VERSION "dbc-export 1 2025.20.8"

NS_ :

BS_:

BU_: ADSP APSB BB BMS CMP CP DAS DI DIF DIR DPB EPASTP EPASTS GTW ICR IDB OCS1P PM PMF PMR PTC RCM RCU TCU UI UIS VCLEFT VCSEC

BO_ 896 PM_alertMatrix2: 8 PM
 SG_ PM_a066_pmfMIA : 1|1@1+ (1,0) [0|1] "" Vector__XXX
 SG_ PM_a067_pmrMIA : 2|1@1+ (1,0) [0|1] "" Vector__XXX
 SG_ PM_a068_brakePedalMonitor : 3|1@1+ (1,0) [0|1] "" Vector__XXX
 SG_ PM_a069_brakeMonitorsUnhealthy : 4|1@1+ (1,0) [0|1] "" Vector__XXX
 SG_ PM_a070_brakeTorqueSplitMonitorT : 5|1@1+ (1,0) [0|1] "" Vector__XXX
 SG_ PM_a071_baseBrakingMonitor : 6|1@1+ (1,0) [0|1] "" Vector__XXX
 SG_ PM_a072_brakeTorqueCommandInterf : 7|1@1+ (1,0) [0|1] "" Vector__XXX
 SG_ PM_a073_canDataBusC : 8|1@1+ (1,0) [0|1] "" Vector__XXX
 SG_ PM_a074_canHardwareBusC : 9|1@1+ (1,0) [0|1] "" Vector__XXX
 SG_ PM_a075_canDataBusD : 10|1@1+ (1,0) [0|1] "" Vector__XXX
 SG_ PM_a076_canHardwareBusD : 11|1@1+ (1,0) [0|1] "" Vector__XXX
 SG_ PM_a077_canDataBusE : 12|1@1+ (1,0) [0|1] "" Vector__XXX
 SG_ PM_a078_canHardwareBusE : 13|1@1+ (1,0) [0|1] "" Vector__XXX
 SG_ PM_a079_rcuMIA : 14|1@1+ (1,0) [0|1] "" Vector__XXX
 SG_ PM_a080_exceptionPrefetchAbort : 15|1@1+ (1,0) [0|1] "" Vector__XXX
 SG_ PM_a081_exceptionDataAbort : 16|1@1+ (1,0) [0|1] "" Vector__XXX
 SG_ PM_a082_exceptionDataAbort2 : 17|1@1+ (1,0) [0|1] "" Vector__XXX
 SG_ PM_a083_ahbWriteError : 18|1@1+ (1,0) [0|1] "" Vector__XXX
 SG_ PM_a084_exceptionMpuFirewall : 19|1@1+ (1,0) [0|1] "" Vector__XXX
 SG_ PM_a085_dpbMIA : 20|1@1+ (1,0) [0|1] "" Vector__XXX
 SG_ PM_a086_exceptionUndefinedInstru : 21|1@1+ (1,0) [0|1] "" Vector__XXX
 SG_ PM_a087_canHardwareBusLIPC : 22|1@1+ (1,0) [0|1] "" Vector__XXX
 SG_ PM_a092_xtalOscillator : 27|1@1+ (1,0) [0|1] "" Vector__XXX
 SG_ PM_a093_accelPedalSupply : 28|1@1+ (1,0) [0|1] "" Vector__XXX
 SG_ PM_a095_ITPMSTimeoutGNSSConverge : 30|1@1+ (1,0) [0|1] "" Vector__XXX
 SG_ PM_a096_ITPMSConvergedGNSSAbsRad : 31|1@1+ (1,0) [0|1] "" Vector__XXX
 SG_ PM_a098_ITPMSTriggerDebug : 33|1@1+ (1,0) [0|1] "" Vector__XXX
 SG_ PM_a099_ITPMSCalibrated : 34|1@1+ (1,0) [0|1] "" Vector__XXX
 SG_ PM_a100_diTraceInfo1 : 35|1@1+ (1,0) [0|1] "" Vector__XXX
 SG_ PM_a110_indirectTPMSSoftWarningF : 45|1@1+ (1,0) [0|1] "" Vector__XXX
 SG_ PM_a111_indirectTPMSSoftWarningF : 46|1@1+ (1,0) [0|1] "" Vector__XXX
 SG_ PM_a112_indirectTPMSSoftWarningR : 47|1@1+ (1,0) [0|1] "" Vector__XXX
 SG_ PM_a113_indirectTPMSSoftWarningR : 48|1@1+ (1,0) [0|1] "" Vector__XXX
 SG_ PM_a114_indirectTPMSHardWarningF : 49|1@1+ (1,0) [0|1] "" Vector__XXX
 SG_ PM_a115_indirectTPMSHardWarningF : 50|1@1+ (1,0) [0|1] "" Vector__XXX
 SG_ PM_a116_indirectTPMSHardWarningR : 51|1@1+ (1,0) [0|1] "" Vector__XXX
 SG_ PM_a117_indirectTPMSHardWarningR : 52|1@1+ (1,0) [0|1] "" Vector__XXX
 SG_ PM_a120_indirectTPMSFaulted : 55|1@1+ (1,0) [0|1] "" Vector__XXX
 SG_ PM_a121_unintendedReset2 : 56|1@1+ (1,0) [0|1] "" Vector__XXX

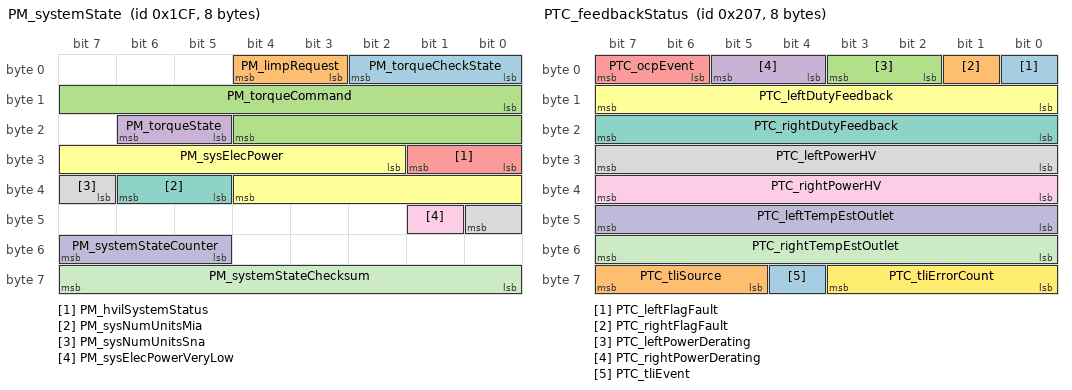
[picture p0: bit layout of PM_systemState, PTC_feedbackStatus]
BO_ 463 PM_systemState: 8 PM
 SG_ PM_torqueCheckState : 0|3@1+ (1,0) [0|7] "" Vector__XXX
 SG_ PM_limpRequest : 3|2@1+ (1,0) [0|3] "" Vector__XXX
 SG_ PM_torqueCommand : 8|13@1- (2,0) [-8192|8190] "Nm" Vector__XXX
 SG_ PM_torqueState : 21|2@1+ (1,0) [0|3] "" Vector__XXX
 SG_ PM_hvilSystemStatus : 24|2@1+ (1,0) [0|2] "" Vector__XXX
 SG_ PM_sysElecPower : 26|11@1- (1,250) [-774|1273] "kW" Vector__XXX
 SG_ PM_sysNumUnitsMia : 37|2@1+ (1,0) [0|3] "" Vector__XXX
 SG_ PM_sysNumUnitsSna : 39|2@1+ (1,0) [0|3] "" Vector__XXX
 SG_ PM_sysElecPowerVeryLow : 41|1@1+ (1,0) [0|1] "" Vector__XXX
 SG_ PM_systemStateCounter : 53|3@1+ (1,0) [0|7] "" Vector__XXX
 SG_ PM_systemStateChecksum : 56|8@1+ (1,0) [0|255] "" Vector__XXX

BO_ 519 PTC_feedbackStatus: 8 PTC
 SG_ PTC_leftFlagFault : 0|1@1+ (1,0) [0|1] "" Vector__XXX
 SG_ PTC_rightFlagFault : 1|1@1+ (1,0) [0|1] "" Vector__XXX
 SG_ PTC_leftPowerDerating : 2|2@1+ (1,0) [0|3] "" Vector__XXX
 SG_ PTC_rightPowerDerating : 4|2@1+ (1,0) [0|3] "" Vector__XXX
 SG_ PTC_ocpEvent : 6|2@1+ (1,0) [0|3] "" Vector__XXX
 SG_ PTC_leftDutyFeedback : 8|8@1+ (0.5,0) [0|100] "%" Vector__XXX
 SG_ PTC_rightDutyFeedback : 16|8@1+ (0.5,0) [0|100] "%" Vector__XXX
 SG_ PTC_leftPowerHV : 24|8@1+ (30,0) [0|7650] "W" Vector__XXX
 SG_ PTC_rightPowerHV : 32|8@1+ (30,0) [0|7650] "W" Vector__XXX
 SG_ PTC_leftTempEstOutlet : 40|8@1+ (1,-40) [-40|200] "degC" Vector__XXX
 SG_ PTC_rightTempEstOutlet : 48|8@1+ (1,-40) [-40|200] "degC" Vector__XXX
 SG_ PTC_tliErrorCount : 56|4@1+ (1,0) [0|15] "" Vector__XXX
 SG_ PTC_tliEvent : 60|1@1+ (1,0) [0|1] "" Vector__XXX
 SG_ PTC_tliSource : 61|3@1+ (1,0) [0|7] "" Vector__XXX

BO_ 1297 RCM_alertLog: 8 RCM
 SG_ RCM_alertID M : 0|10@1+ (1,0) [0|1023] "" Vector__XXX
 SG_ RCM_alertState : 10|1@1+ (1,0) [0|1] "" Vector__XXX
 SG_ RCM_a000_eventArmStatus m0 : 11|1@1+ (1,0) [0|1] "" Vector__XXX
 SG_ RCM_a000_eventFactoryMode m0 : 12|1@1+ (1,0) [0|1] "" Vector__XXX
 SG_ RCM_a000_eventDiagEnabled m0 : 13|1@1+ (1,0) [0|1] "" Vector__XXX
 SG_ RCM_a000_eventDriveOrientation m0 : 14|1@1+ (1,0) [0|1] "" Vector__XXX
 SG_ RCM_a000_crashDetectedFront m0 : 16|1@1+ (1,0) [0|1] "" Vector__XXX
 SG_ RCM_a000_crashDetectedRear m0 : 17|1@1+ (1,0) [0|1] "" Vector__XXX
 SG_ RCM_a000_crashDetectedLeft m0 : 18|1@1+ (1,0) [0|1] "" Vector__XXX
 SG_ RCM_a000_crashDetectedRight m0 : 19|1@1+ (1,0) [0|1] "" Vector__XXX
 SG_ RCM_a000_crashDetectedRoll m0 : 20|1@1+ (1,0) [0|1] "" Vector__XXX
 SG_ RCM_a000_crashDetectedPreten m0 : 21|1@1+ (1,0) [0|1] "" Vector__XXX
 SG_ RCM_a000_crashDetectedStage1 m0 : 22|1@1+ (1,0) [0|1] "" Vector__XXX
 SG_ RCM_a000_crashDetectedStage2 m0 : 23|1@1+ (1,0) [0|1] "" Vector__XXX
 SG_ RCM_a000_crashDetectedHVpyro m0 : 24|1@1+ (1,0) [0|1] "" Vector__XXX
 SG_ RCM_a000_eventIDFsignal m0 : 25|1@1+ (1,0) [0|1] "" Vector__XXX
 SG_ RCM_a000_eventFrontLeftSeatbelt m0 : 26|1@1+ (1,0) [0|1] "" Vector__XXX
 SG_ RCM_a000_eventFrontRightSeatbelt m0 : 27|1@1+ (1,0) [0|1] "" Vector__XXX
 SG_ RCM_a000_eventVehicleSpeed m0 : 28|12@1+ (0.08,-40) [-40|287.6] "kph" Vector__XXX
 SG_ RCM_a000_eventSteeringAngle m0 : 45|14@0+ (0.1,-819.2) [-819.2|819.1] "deg" Vector__XXX
 SG_ RCM_a000_eventDriverBrakeApply m0 : 46|2@1+ (1,0) [0|3] "" Vector__XXX
 SG_ RCM_a000_eventAccelPedalPos m0 : 56|8@1+ (0.4,0) [0|102] "%" Vector__XXX
 SG_ RCM_a001_eventArmStatus m1 : 11|1@1+ (1,0) [0|1] "" Vector__XXX
 SG_ RCM_a001_eventFactoryMode m1 : 12|1@1+ (1,0) [0|1] "" Vector__XXX
 SG_ RCM_a001_eventDiagEnabled m1 : 13|1@1+ (1,0) [0|1] "" Vector__XXX
 SG_ RCM_a001_eventDriveOrientation m1 : 14|1@1+ (1,0) [0|1] "" Vector__XXX
 SG_ RCM_a001_nearDeployFront m1 : 16|1@1+ (1,0) [0|1] "" Vector__XXX
 SG_ RCM_a001_nearDeployRear m1 : 17|1@1+ (1,0) [0|1] "" Vector__XXX
 SG_ RCM_a001_nearDeployLeft m1 : 18|1@1+ (1,0) [0|1] "" Vector__XXX
 SG_ RCM_a001_nearDeployRight m1 : 19|1@1+ (1,0) [0|1] "" Vector__XXX
 SG_ RCM_a001_nearDeployRoll m1 : 20|1@1+ (1,0) [0|1] "" Vector__XXX
 SG_ RCM_a001_nearDeployPretensioner m1 : 21|1@1+ (1,0) [0|1] "" Vector__XXX
 SG_ RCM_a001_eventIDFsignal m1 : 25|1@1+ (1,0) [0|1] "" Vector__XXX
 SG_ RCM_a001_eventFrontLeftSeatbelt m1 : 26|1@1+ (1,0) [0|1] "" Vector__XXX
 SG_ RCM_a001_eventFrontRightSeatbelt m1 : 27|1@1+ (1,0) [0|1] "" Vector__XXX
 SG_ RCM_a001_eventVehicleSpeed m1 : 28|12@1+ (0.08,-40) [-40|287.6] "kph" Vector__XXX
 SG_ RCM_a001_eventSteeringAngle m1 : 45|14@0+ (0.1,-819.2) [-819.2|819.1] "deg" Vector__XXX
 SG_ RCM_a001_eventDriverBrakeApply m1 : 46|2@1+ (1,0) [0|2] "" Vector__XXX
 SG_ RCM_a001_eventAccelPedalPos m1 : 56|8@1+ (0.4,0) [0|101.6] "%" Vector__XXX
 SG_ RCM_a002_eventArmStatus m2 : 11|1@1+ (1,0) [0|1] "" Vector__XXX
 SG_ RCM_a002_eventFactoryMode m2 : 12|1@1+ (1,0) [0|1] "" Vector__XXX
 SG_ RCM_a002_eventDiagEnabled m2 : 13|1@1+ (1,0) [0|1] "" Vector__XXX
 SG_ RCM_a002_eventDriveOrientation m2 : 14|1@1+ (1,0) [0|1] "" Vector__XXX
 SG_ RCM_a002_airbagsUnArmed m2 : 16|1@1+ (1,0) [0|1] "" Vector__XXX
 SG_ RCM_a002_eventIDFsignal m2 : 25|1@1+ (1,0) [0|1] "" Vector__XXX
 SG_ RCM_a002_eventFrontLeftSeatbelt m2 : 26|1@1+ (1,0) [0|1] "" Vector__XXX
 SG_ RCM_a002_eventFrontRightSeatbelt m2 : 27|1@1+ (1,0) [0|1] "" Vector__XXX
 SG_ RCM_a002_eventVehicleSpeed m2 : 28|12@1+ (0.08,-40) [-40|287.6] "kph" Vector__XXX
 SG_ RCM_a002_eventSteeringAngle m2 : 45|14@0+ (0.1,-819.2) [-819.2|819.1] "deg" Vector__XXX
 SG_ RCM_a002_eventDriverBrakeApply m2 : 46|2@1+ (1,0) [0|2] "" Vector__XXX
 SG_ RCM_a002_eventAccelPedalPos m2 : 56|8@1+ (0.4,0) [0|101.6] "%" Vector__XXX
 SG_ RCM_a003_eventArmStatus m3 : 11|1@1+ (1,0) [0|1] "" Vector__XXX
 SG_ RCM_a003_eventFactoryMode m3 : 12|1@1+ (1,0) [0|1] "" Vector__XXX
 SG_ RCM_a003_eventDiagEnabled m3 : 13|1@1+ (1,0) [0|1] "" Vector__XXX
 SG_ RCM_a003_eventDriveOrientation m3 : 14|1@1+ (1,0) [0|1] "" Vector__XXX
 SG_ RCM_a003_warningIndicatorOn m3 : 16|1@1+ (1,0) [0|1] "" Vector__XXX
 SG_ RCM_a003_eventIDFsignal m3 : 25|1@1+ (1,0) [0|1] "" Vector__XXX
 SG_ RCM_a003_eventFrontLeftSeatbelt m3 : 26|1@1+ (1,0) [0|1] "" Vector__XXX
 SG_ RCM_a003_eventFrontRightSeatbelt m3 : 27|1@1+ (1,0) [0|1] "" Vector__XXX
 SG_ RCM_a003_eventVehicleSpeed m3 : 28|12@1+ (0.08,-40) [-40|287.6] "kph" Vector__XXX
 SG_ RCM_a003_eventSteeringAngle m3 : 45|14@0+ (0.1,-819.2) [-819.2|819.1] "deg" Vector__XXX
 SG_ RCM_a003_eventDriverBrakeApply m3 : 46|2@1+ (1,0) [0|2] "" Vector__XXX
 SG_ RCM_a003_eventAccelPedalPos m3 : 56|8@1+ (0.4,0) [0|101.6] "%" Vector__XXX
 SG_ RCM_a004_eventArmStatus m4 : 11|1@1+ (1,0) [0|1] "" Vector__XXX
 SG_ RCM_a004_eventFactoryMode m4 : 12|1@1+ (1,0) [0|1] "" Vector__XXX
 SG_ RCM_a004_eventDiagEnabled m4 : 13|1@1+ (1,0) [0|1] "" Vector__XXX
 SG_ RCM_a004_eventDriveOrientation m4 : 14|1@1+ (1,0) [0|1] "" Vector__XXX
 SG_ RCM_a004_frontAlgoDisabled m4 : 16|1@1+ (1,0) [0|1] "" Vector__XXX
 SG_ RCM_a004_sideAlgoDisabled m4 : 17|1@1+ (1,0) [0|1] "" Vector__XXX
 SG_ RCM_a004_rollAlgoDisabled m4 : 18|1@1+ (1,0) [0|1] "" Vector__XXX
 SG_ RCM_a004_idleMode m4 : 19|1@1+ (1,0) [0|1] "" Vector__XXX
 SG_ RCM_a004_internalFaultDetected m4 : 20|1@1+ (1,0) [0|1] "" Vector__XXX
 SG_ RCM_a004_swVersionMismatch m4 : 21|1@1+ (1,0) [0|1] "" Vector__XXX
 SG_ RCM_a004_paramLayoutIDInv m4 : 22|1@1+ (1,0) [0|1] "" Vector__XXX
 SG_ RCM_a004_algoPASIDMismatch m4 : 23|1@1+ (1,0) [0|1] "" Vector__XXX
 SG_ RCM_a004_eventIDFsignal m4 : 25|1@1+ (1,0) [0|1] "" Vector__XXX
 SG_ RCM_a004_eventFrontLeftSeatbelt m4 : 26|1@1+ (1,0) [0|1] "" Vector__XXX
 SG_ RCM_a004_eventFrontRightSeatbelt m4 : 27|1@1+ (1,0) [0|1] "" Vector__XXX
 SG_ RCM_a004_eventVehicleSpeed m4 : 28|12@1+ (0.08,-40) [-40|287.6] "kph" Vector__XXX
 SG_ RCM_a004_eventSteeringAngle m4 : 45|14@0+ (0.1,-819.2) [-819.2|819.1] "deg" Vector__XXX
 SG_ RCM_a004_eventDriverBrakeApply m4 : 46|2@1+ (1,0) [0|2] "" Vector__XXX
 SG_ RCM_a004_eventAccelPedalPos m4 : 56|8@1+ (0.4,0) [0|101.6] "%" Vector__XXX
 SG_ RCM_a005_eventArmStatus m5 : 11|1@1+ (1,0) [0|1] "" Vector__XXX
 SG_ RCM_a005_eventFactoryMode m5 : 12|1@1+ (1,0) [0|1] "" Vector__XXX
 SG_ RCM_a005_eventDiagEnabled m5 : 13|1@1+ (1,0) [0|1] "" Vector__XXX
 SG_ RCM_a005_eventDriveOrientation m5 : 14|1@1+ (1,0) [0|1] "" Vector__XXX
 SG_ RCM_a005_externalCRCError m5 : 16|1@1+ (1,0) [0|1] "" Vector__XXX
 SG_ RCM_a005_eventIDFsignal m5 : 25|1@1+ (1,0) [0|1] "" Vector__XXX
 SG_ RCM_a005_eventFrontLeftSeatbelt m5 : 26|1@1+ (1,0) [0|1] "" Vector__XXX
 SG_ RCM_a005_eventFrontRightSeatbelt m5 : 27|1@1+ (1,0) [0|1] "" Vector__XXX
 SG_ RCM_a005_eventVehicleSpeed m5 : 28|12@1+ (0.08,-40) [-40|287.6] "kph" Vector__XXX
 SG_ RCM_a005_eventSteeringAngle m5 : 45|14@0+ (0.1,-819.2) [-819.2|819.1] "deg" Vector__XXX
 SG_ RCM_a005_eventDriverBrakeApply m5 : 46|2@1+ (1,0) [0|2] "" Vector__XXX
 SG_ RCM_a005_eventAccelPedalPos m5 : 56|8@1+ (0.4,0) [0|101.6] "%" Vector__XXX
 SG_ RCM_a006_eventArmStatus m6 : 11|1@1+ (1,0) [0|1] "" Vector__XXX
 SG_ RCM_a006_eventFactoryMode m6 : 12|1@1+ (1,0) [0|1] "" Vector__XXX
 SG_ RCM_a006_eventDiagEnabled m6 : 13|1@1+ (1,0) [0|1] "" Vector__XXX
 SG_ RCM_a006_eventDriveOrientation m6 : 14|1@1+ (1,0) [0|1] "" Vector__XXX
 SG_ RCM_a006_batteryVoltageTooHigh m6 : 16|1@1+ (1,0) [0|1] "" Vector__XXX
 SG_ RCM_a006_batteryVoltageTooLow m6 : 17|1@1+ (1,0) [0|1] "" Vector__XXX
 SG_ RCM_a006_eventIDFsignal m6 : 25|1@1+ (1,0) [0|1] "" Vector__XXX
 SG_ RCM_a006_eventFrontLeftSeatbelt m6 : 26|1@1+ (1,0) [0|1] "" Vector__XXX
 SG_ RCM_a006_eventFrontRightSeatbelt m6 : 27|1@1+ (1,0) [0|1] "" Vector__XXX
 SG_ RCM_a006_eventVehicleSpeed m6 : 28|12@1+ (0.08,-40) [-40|287.6] "kph" Vector__XXX
 SG_ RCM_a006_eventSteeringAngle m6 : 45|14@0+ (0.1,-819.2) [-819.2|819.1] "deg" Vector__XXX
 SG_ RCM_a006_eventDriverBrakeApply m6 : 46|2@1+ (1,0) [0|2] "" Vector__XXX
 SG_ RCM_a006_eventAccelPedalPos m6 : 56|8@1+ (0.4,0) [0|101.6] "%" Vector__XXX
 SG_ RCM_a008_eventArmStatus m8 : 11|1@1+ (1,0) [0|1] "" Vector__XXX
 SG_ RCM_a008_eventFactoryMode m8 : 12|1@1+ (1,0) [0|1] "" Vector__XXX
 SG_ RCM_a008_eventDiagEnabled m8 : 13|1@1+ (1,0) [0|1] "" Vector__XXX
 SG_ RCM_a008_eventDriveOrientation m8 : 14|1@1+ (1,0) [0|1] "" Vector__XXX
 SG_ RCM_a008_lossOfMainPwrSupMonit m8 : 16|1@1+ (1,0) [0|1] "" Vector__XXX
 SG_ RCM_a008_lossOfBckupPwrSupMonit m8 : 17|1@1+ (1,0) [0|1] "" Vector__XXX
 SG_ RCM_a008_normalShtdwnUnavail m8 : 18|1@1+ (1,0) [0|1] "" Vector__XXX
 SG_ RCM_a008_eventIDFsignal m8 : 25|1@1+ (1,0) [0|1] "" Vector__XXX
 SG_ RCM_a008_eventFrontLeftSeatbelt m8 : 26|1@1+ (1,0) [0|1] "" Vector__XXX
 SG_ RCM_a008_eventFrontRightSeatbelt m8 : 27|1@1+ (1,0) [0|1] "" Vector__XXX
 SG_ RCM_a008_eventVehicleSpeed m8 : 28|12@1+ (0.08,-40) [-40|287.6] "kph" Vector__XXX
 SG_ RCM_a008_eventSteeringAngle m8 : 45|14@0+ (0.1,-819.2) [-819.2|819.1] "deg" Vector__XXX
 SG_ RCM_a008_eventDriverBrakeApply m8 : 46|2@1+ (1,0) [0|2] "" Vector__XXX
 SG_ RCM_a008_eventAccelPedalPos m8 : 56|8@1+ (0.4,0) [0|101.6] "%" Vector__XXX
 SG_ RCM_a009_eventArmStatus m9 : 11|1@1+ (1,0) [0|1] "" Vector__XXX
 SG_ RCM_a009_eventFactoryMode m9 : 12|1@1+ (1,0) [0|1] "" Vector__XXX
 SG_ RCM_a009_eventDiagEnabled m9 : 13|1@1+ (1,0) [0|1] "" Vector__XXX
 SG_ RCM_a009_eventDriveOrientation m9 : 14|1@1+ (1,0) [0|1] "" Vector__XXX
 SG_ RCM_a009_reprogramLimitExceeded m9 : 16|1@1+ (1,0) [0|1] "" Vector__XXX
 SG_ RCM_a009_eventIDFsignal m9 : 25|1@1+ (1,0) [0|1] "" Vector__XXX
 SG_ RCM_a009_eventFrontLeftSeatbelt m9 : 26|1@1+ (1,0) [0|1] "" Vector__XXX
 SG_ RCM_a009_eventFrontRightSeatbelt m9 : 27|1@1+ (1,0) [0|1] "" Vector__XXX
 SG_ RCM_a009_eventVehicleSpeed m9 : 28|12@1+ (0.08,-40) [-40|287.6] "kph" Vector__XXX
 SG_ RCM_a009_eventSteeringAngle m9 : 45|14@0+ (0.1,-819.2) [-819.2|819.1] "deg" Vector__XXX
 SG_ RCM_a009_eventDriverBrakeApply m9 : 46|2@1+ (1,0) [0|2] "" Vector__XXX
 SG_ RCM_a009_eventAccelPedalPos m9 : 56|8@1+ (0.4,0) [0|101.6] "%" Vector__XXX
 SG_ RCM_a011_eventArmStatus m11 : 11|1@1+ (1,0) [0|1] "" Vector__XXX
 SG_ RCM_a011_eventFactoryMode m11 : 12|1@1+ (1,0) [0|1] "" Vector__XXX
 SG_ RCM_a011_eventDiagEnabled m11 : 13|1@1+ (1,0) [0|1] "" Vector__XXX
 SG_ RCM_a011_eventDriveOrientation m11 : 14|1@1+ (1,0) [0|1] "" Vector__XXX
 SG_ RCM_a011_edrDataAreaLocked m11 : 16|1@1+ (1,0) [0|1] "" Vector__XXX
 SG_ RCM_a011_eventIDFsignal m11 : 25|1@1+ (1,0) [0|1] "" Vector__XXX
 SG_ RCM_a011_eventFrontLeftSeatbelt m11 : 26|1@1+ (1,0) [0|1] "" Vector__XXX
 SG_ RCM_a011_eventFrontRightSeatbelt m11 : 27|1@1+ (1,0) [0|1] "" Vector__XXX
 SG_ RCM_a011_eventVehicleSpeed m11 : 28|12@1+ (0.08,-40) [-40|287.6] "kph" Vector__XXX
 SG_ RCM_a011_eventSteeringAngle m11 : 45|14@0+ (0.1,-819.2) [-819.2|819.1] "deg" Vector__XXX
 SG_ RCM_a011_eventDriverBrakeApply m11 : 46|2@1+ (1,0) [0|2] "" Vector__XXX
 SG_ RCM_a011_eventAccelPedalPos m11 : 56|8@1+ (0.4,0) [0|101.6] "%" Vector__XXX
 SG_ RCM_a012_eventArmStatus m12 : 11|1@1+ (1,0) [0|1] "" Vector__XXX
 SG_ RCM_a012_eventFactoryMode m12 : 12|1@1+ (1,0) [0|1] "" Vector__XXX
 SG_ RCM_a012_eventDiagEnabled m12 : 13|1@1+ (1,0) [0|1] "" Vector__XXX
 SG_ RCM_a012_eventDriveOrientation m12 : 14|1@1+ (1,0) [0|1] "" Vector__XXX
 SG_ RCM_a012_vinMismatch m12 : 16|1@1+ (1,0) [0|1] "" Vector__XXX
 SG_ RCM_a012_vinNotProgrammed m12 : 17|1@1+ (1,0) [0|1] "" Vector__XXX
 SG_ RCM_a012_eventIDFsignal m12 : 25|1@1+ (1,0) [0|1] "" Vector__XXX
 SG_ RCM_a012_eventFrontLeftSeatbelt m12 : 26|1@1+ (1,0) [0|1] "" Vector__XXX
 SG_ RCM_a012_eventFrontRightSeatbelt m12 : 27|1@1+ (1,0) [0|1] "" Vector__XXX
 SG_ RCM_a012_eventVehicleSpeed m12 : 28|12@1+ (0.08,-40) [-40|287.6] "kph" Vector__XXX
 SG_ RCM_a012_eventSteeringAngle m12 : 45|14@0+ (0.1,-819.2) [-819.2|819.1] "deg" Vector__XXX
 SG_ RCM_a012_eventDriverBrakeApply m12 : 46|2@1+ (1,0) [0|2] "" Vector__XXX
 SG_ RCM_a012_eventAccelPedalPos m12 : 56|8@1+ (0.4,0) [0|101.6] "%" Vector__XXX
 SG_ RCM_a013_eventArmStatus m13 : 11|1@1+ (1,0) [0|1] "" Vector__XXX
 SG_ RCM_a013_eventFactoryMode m13 : 12|1@1+ (1,0) [0|1] "" Vector__XXX
 SG_ RCM_a013_eventDiagEnabled m13 : 13|1@1+ (1,0) [0|1] "" Vector__XXX
 SG_ RCM_a013_eventDriveOrientation m13 : 14|1@1+ (1,0) [0|1] "" Vector__XXX
 SG_ RCM_a013_driveOrientiInitNotDone m13 : 16|1@1+ (1,0) [0|1] "" Vector__XXX
 SG_ RCM_a013_driveOrientPlausiCheck m13 : 17|1@1+ (1,0) [0|1] "" Vector__XXX
 SG_ RCM_a013_eventIDFsignal m13 : 25|1@1+ (1,0) [0|1] "" Vector__XXX
 SG_ RCM_a013_eventFrontLeftSeatbelt m13 : 26|1@1+ (1,0) [0|1] "" Vector__XXX
 SG_ RCM_a013_eventFrontRightSeatbelt m13 : 27|1@1+ (1,0) [0|1] "" Vector__XXX
 SG_ RCM_a013_eventVehicleSpeed m13 : 28|12@1+ (0.08,-40) [-40|287.6] "kph" Vector__XXX
 SG_ RCM_a013_eventSteeringAngle m13 : 45|14@0+ (0.1,-819.2) [-819.2|819.1] "deg" Vector__XXX
 SG_ RCM_a013_eventDriverBrakeApply m13 : 46|2@1+ (1,0) [0|2] "" Vector__XXX
 SG_ RCM_a013_eventAccelPedalPos m13 : 56|8@1+ (0.4,0) [0|101.6] "%" Vector__XXX
 SG_ RCM_a014_eventArmStatus m14 : 11|1@1+ (1,0) [0|1] "" Vector__XXX
 SG_ RCM_a014_eventFactoryMode m14 : 12|1@1+ (1,0) [0|1] "" Vector__XXX
 SG_ RCM_a014_eventDiagEnabled m14 : 13|1@1+ (1,0) [0|1] "" Vector__XXX
 SG_ RCM_a014_eventDriveOrientation m14 : 14|1@1+ (1,0) [0|1] "" Vector__XXX
 SG_ RCM_a014_driverABStg1Sht2Gnd m14 : 16|1@1+ (1,0) [0|1] "" Vector__XXX
 SG_ RCM_a014_driverABStg1Sht2Bat m14 : 17|1@1+ (1,0) [0|1] "" Vector__XXX
 SG_ RCM_a014_driverABStg1Open m14 : 18|1@1+ (1,0) [0|1] "" Vector__XXX
 SG_ RCM_a014_driverABStg1Short m14 : 19|1@1+ (1,0) [0|1] "" Vector__XXX
 SG_ RCM_a014_driverABStg1CrossCoup m14 : 20|1@1+ (1,0) [0|1] "" Vector__XXX
 SG_ RCM_a014_driverABStg1Config m14 : 21|1@1+ (1,0) [0|1] "" Vector__XXX
 SG_ RCM_a014_eventIDFsignal m14 : 25|1@1+ (1,0) [0|1] "" Vector__XXX
 SG_ RCM_a014_eventFrontLeftSeatbelt m14 : 26|1@1+ (1,0) [0|1] "" Vector__XXX
 SG_ RCM_a014_eventFrontRightSeatbelt m14 : 27|1@1+ (1,0) [0|1] "" Vector__XXX
 SG_ RCM_a014_eventVehicleSpeed m14 : 28|12@1+ (0.08,-40) [-40|287.6] "kph" Vector__XXX
 SG_ RCM_a014_eventSteeringAngle m14 : 45|14@0+ (0.1,-819.2) [-819.2|819.1] "deg" Vector__XXX
 SG_ RCM_a014_eventDriverBrakeApply m14 : 46|2@1+ (1,0) [0|2] "" Vector__XXX
 SG_ RCM_a014_eventAccelPedalPos m14 : 56|8@1+ (0.4,0) [0|101.6] "%" Vector__XXX
 SG_ RCM_a015_eventArmStatus m15 : 11|1@1+ (1,0) [0|1] "" Vector__XXX
 SG_ RCM_a015_eventFactoryMode m15 : 12|1@1+ (1,0) [0|1] "" Vector__XXX
 SG_ RCM_a015_eventDiagEnabled m15 : 13|1@1+ (1,0) [0|1] "" Vector__XXX
 SG_ RCM_a015_eventDriveOrientation m15 : 14|1@1+ (1,0) [0|1] "" Vector__XXX
 SG_ RCM_a015_driverABStg2Sht2Gnd m15 : 16|1@1+ (1,0) [0|1] "" Vector__XXX
 SG_ RCM_a015_driverABStg2Sht2Bat m15 : 17|1@1+ (1,0) [0|1] "" Vector__XXX
 SG_ RCM_a015_driverABStg2Open m15 : 18|1@1+ (1,0) [0|1] "" Vector__XXX
 SG_ RCM_a015_driverABStg2Short m15 : 19|1@1+ (1,0) [0|1] "" Vector__XXX
 SG_ RCM_a015_driverABStg2CrossCoup m15 : 20|1@1+ (1,0) [0|1] "" Vector__XXX
 SG_ RCM_a015_driverABStg2Config m15 : 21|1@1+ (1,0) [0|1] "" Vector__XXX
 SG_ RCM_a015_eventIDFsignal m15 : 25|1@1+ (1,0) [0|1] "" Vector__XXX
 SG_ RCM_a015_eventFrontLeftSeatbelt m15 : 26|1@1+ (1,0) [0|1] "" Vector__XXX
 SG_ RCM_a015_eventFrontRightSeatbelt m15 : 27|1@1+ (1,0) [0|1] "" Vector__XXX
 SG_ RCM_a015_eventVehicleSpeed m15 : 28|12@1+ (0.08,-40) [-40|287.6] "kph" Vector__XXX
 SG_ RCM_a015_eventSteeringAngle m15 : 45|14@0+ (0.1,-819.2) [-819.2|819.1] "deg" Vector__XXX
 SG_ RCM_a015_eventDriverBrakeApply m15 : 46|2@1+ (1,0) [0|2] "" Vector__XXX
 SG_ RCM_a015_eventAccelPedalPos m15 : 56|8@1+ (0.4,0) [0|101.6] "%" Vector__XXX
 SG_ RCM_a016_eventArmStatus m16 : 11|1@1+ (1,0) [0|1] "" Vector__XXX
 SG_ RCM_a016_eventFactoryMode m16 : 12|1@1+ (1,0) [0|1] "" Vector__XXX
 SG_ RCM_a016_eventDiagEnabled m16 : 13|1@1+ (1,0) [0|1] "" Vector__XXX
 SG_ RCM_a016_eventDriveOrientation m16 : 14|1@1+ (1,0) [0|1] "" Vector__XXX
 SG_ RCM_a016_passABStg1Sht2Gnd m16 : 16|1@1+ (1,0) [0|1] "" Vector__XXX
 SG_ RCM_a016_passABStg1Sht2Bat m16 : 17|1@1+ (1,0) [0|1] "" Vector__XXX
 SG_ RCM_a016_passABStg1Open m16 : 18|1@1+ (1,0) [0|1] "" Vector__XXX
 SG_ RCM_a016_passABStg1Short m16 : 19|1@1+ (1,0) [0|1] "" Vector__XXX
 SG_ RCM_a016_passABStg1CrossCoup m16 : 20|1@1+ (1,0) [0|1] "" Vector__XXX
 SG_ RCM_a016_passABStg1Config m16 : 21|1@1+ (1,0) [0|1] "" Vector__XXX
 SG_ RCM_a016_eventIDFsignal m16 : 25|1@1+ (1,0) [0|1] "" Vector__XXX
 SG_ RCM_a016_eventFrontLeftSeatbelt m16 : 26|1@1+ (1,0) [0|1] "" Vector__XXX
 SG_ RCM_a016_eventFrontRightSeatbelt m16 : 27|1@1+ (1,0) [0|1] "" Vector__XXX
 SG_ RCM_a016_eventVehicleSpeed m16 : 28|12@1+ (0.08,-40) [-40|287.6] "kph" Vector__XXX
 SG_ RCM_a016_eventSteeringAngle m16 : 45|14@0+ (0.1,-819.2) [-819.2|819.1] "deg" Vector__XXX
 SG_ RCM_a016_eventDriverBrakeApply m16 : 46|2@1+ (1,0) [0|2] "" Vector__XXX
 SG_ RCM_a016_eventAccelPedalPos m16 : 56|8@1+ (0.4,0) [0|101.6] "%" Vector__XXX
 SG_ RCM_a017_eventArmStatus m17 : 11|1@1+ (1,0) [0|1] "" Vector__XXX
 SG_ RCM_a017_eventFactoryMode m17 : 12|1@1+ (1,0) [0|1] "" Vector__XXX
 SG_ RCM_a017_eventDiagEnabled m17 : 13|1@1+ (1,0) [0|1] "" Vector__XXX
 SG_ RCM_a017_eventDriveOrientation m17 : 14|1@1+ (1,0) [0|1] "" Vector__XXX
 SG_ RCM_a017_passABStg2Sht2Gnd m17 : 16|1@1+ (1,0) [0|1] "" Vector__XXX
 SG_ RCM_a017_passABStg2Sht2Bat m17 : 17|1@1+ (1,0) [0|1] "" Vector__XXX
 SG_ RCM_a017_passABStg2Open m17 : 18|1@1+ (1,0) [0|1] "" Vector__XXX
 SG_ RCM_a017_passABStg2Short m17 : 19|1@1+ (1,0) [0|1] "" Vector__XXX
 SG_ RCM_a017_passABStg2CrossCoup m17 : 20|1@1+ (1,0) [0|1] "" Vector__XXX
 SG_ RCM_a017_passABStg2Config m17 : 21|1@1+ (1,0) [0|1] "" Vector__XXX
 SG_ RCM_a017_eventIDFsignal m17 : 25|1@1+ (1,0) [0|1] "" Vector__XXX
 SG_ RCM_a017_eventFrontLeftSeatbelt m17 : 26|1@1+ (1,0) [0|1] "" Vector__XXX
 SG_ RCM_a017_eventFrontRightSeatbelt m17 : 27|1@1+ (1,0) [0|1] "" Vector__XXX
 SG_ RCM_a017_eventVehicleSpeed m17 : 28|12@1+ (0.08,-40) [-40|287.6] "kph" Vector__XXX
 SG_ RCM_a017_eventSteeringAngle m17 : 45|14@0+ (0.1,-819.2) [-819.2|819.1] "deg" Vector__XXX
 SG_ RCM_a017_eventDriverBrakeApply m17 : 46|2@1+ (1,0) [0|2] "" Vector__XXX
 SG_ RCM_a017_eventAccelPedalPos m17 : 56|8@1+ (0.4,0) [0|101.6] "%" Vector__XXX
 SG_ RCM_a018_eventArmStatus m18 : 11|1@1+ (1,0) [0|1] "" Vector__XXX
 SG_ RCM_a018_eventFactoryMode m18 : 12|1@1+ (1,0) [0|1] "" Vector__XXX
 SG_ RCM_a018_eventDiagEnabled m18 : 13|1@1+ (1,0) [0|1] "" Vector__XXX
 SG_ RCM_a018_eventDriveOrientation m18 : 14|1@1+ (1,0) [0|1] "" Vector__XXX
 SG_ RCM_a018_passActiveVentSht2Gnd m18 : 16|1@1+ (1,0) [0|1] "" Vector__XXX
 SG_ RCM_a018_passActiveVentSht2Bat m18 : 17|1@1+ (1,0) [0|1] "" Vector__XXX
 SG_ RCM_a018_passActiveVentOpen m18 : 18|1@1+ (1,0) [0|1] "" Vector__XXX
 SG_ RCM_a018_passActiveVentShort m18 : 19|1@1+ (1,0) [0|1] "" Vector__XXX
 SG_ RCM_a018_passActiveVentCrossCoup m18 : 20|1@1+ (1,0) [0|1] "" Vector__XXX
 SG_ RCM_a018_passActiveVentConfig m18 : 21|1@1+ (1,0) [0|1] "" Vector__XXX
 SG_ RCM_a018_eventIDFsignal m18 : 25|1@1+ (1,0) [0|1] "" Vector__XXX
 SG_ RCM_a018_eventFrontLeftSeatbelt m18 : 26|1@1+ (1,0) [0|1] "" Vector__XXX
 SG_ RCM_a018_eventFrontRightSeatbelt m18 : 27|1@1+ (1,0) [0|1] "" Vector__XXX
 SG_ RCM_a018_eventVehicleSpeed m18 : 28|12@1+ (0.08,-40) [-40|287.6] "kph" Vector__XXX
 SG_ RCM_a018_eventSteeringAngle m18 : 45|14@0+ (0.1,-819.2) [-819.2|819.1] "deg" Vector__XXX
 SG_ RCM_a018_eventDriverBrakeApply m18 : 46|2@1+ (1,0) [0|2] "" Vector__XXX
 SG_ RCM_a018_eventAccelPedalPos m18 : 56|8@1+ (0.4,0) [0|101.6] "%" Vector__XXX
 SG_ RCM_a019_eventArmStatus m19 : 11|1@1+ (1,0) [0|1] "" Vector__XXX
 SG_ RCM_a019_eventFactoryMode m19 : 12|1@1+ (1,0) [0|1] "" Vector__XXX
 SG_ RCM_a019_eventDiagEnabled m19 : 13|1@1+ (1,0) [0|1] "" Vector__XXX
 SG_ RCM_a019_eventDriveOrientation m19 : 14|1@1+ (1,0) [0|1] "" Vector__XXX
 SG_ RCM_a019_pretenShldLeftSht2Gnd m19 : 16|1@1+ (1,0) [0|1] "" Vector__XXX
 SG_ RCM_a019_pretenShldLeftSht2Bat m19 : 17|1@1+ (1,0) [0|1] "" Vector__XXX
 SG_ RCM_a019_pretenShldLeftOpen m19 : 18|1@1+ (1,0) [0|1] "" Vector__XXX
 SG_ RCM_a019_pretenShldLeftShort m19 : 19|1@1+ (1,0) [0|1] "" Vector__XXX
 SG_ RCM_a019_pretenShldLeftCrossC m19 : 20|1@1+ (1,0) [0|1] "" Vector__XXX
 SG_ RCM_a019_pretenShldLeftConfig m19 : 21|1@1+ (1,0) [0|1] "" Vector__XXX
 SG_ RCM_a019_eventIDFsignal m19 : 25|1@1+ (1,0) [0|1] "" Vector__XXX
 SG_ RCM_a019_eventFrontLeftSeatbelt m19 : 26|1@1+ (1,0) [0|1] "" Vector__XXX
 SG_ RCM_a019_eventFrontRightSeatbelt m19 : 27|1@1+ (1,0) [0|1] "" Vector__XXX
 SG_ RCM_a019_eventVehicleSpeed m19 : 28|12@1+ (0.08,-40) [-40|287.6] "kph" Vector__XXX
 SG_ RCM_a019_eventSteeringAngle m19 : 45|14@0+ (0.1,-819.2) [-819.2|819.1] "deg" Vector__XXX
 SG_ RCM_a019_eventDriverBrakeApply m19 : 46|2@1+ (1,0) [0|2] "" Vector__XXX
 SG_ RCM_a019_eventAccelPedalPos m19 : 56|8@1+ (0.4,0) [0|101.6] "%" Vector__XXX
 SG_ RCM_a020_eventArmStatus m20 : 11|1@1+ (1,0) [0|1] "" Vector__XXX
 SG_ RCM_a020_eventFactoryMode m20 : 12|1@1+ (1,0) [0|1] "" Vector__XXX
 SG_ RCM_a020_eventDiagEnabled m20 : 13|1@1+ (1,0) [0|1] "" Vector__XXX
 SG_ RCM_a020_eventDriveOrientation m20 : 14|1@1+ (1,0) [0|1] "" Vector__XXX
 SG_ RCM_a020_pretenShldRightSht2Gnd m20 : 16|1@1+ (1,0) [0|1] "" Vector__XXX
 SG_ RCM_a020_pretenShldRightSht2Bat m20 : 17|1@1+ (1,0) [0|1] "" Vector__XXX
 SG_ RCM_a020_pretenShldRightOpen m20 : 18|1@1+ (1,0) [0|1] "" Vector__XXX
 SG_ RCM_a020_pretenShldRightShort m20 : 19|1@1+ (1,0) [0|1] "" Vector__XXX
 SG_ RCM_a020_pretenShldRightCrossC m20 : 20|1@1+ (1,0) [0|1] "" Vector__XXX
 SG_ RCM_a020_pretenShldRightConfig m20 : 21|1@1+ (1,0) [0|1] "" Vector__XXX
 SG_ RCM_a020_eventIDFsignal m20 : 25|1@1+ (1,0) [0|1] "" Vector__XXX
 SG_ RCM_a020_eventFrontLeftSeatbelt m20 : 26|1@1+ (1,0) [0|1] "" Vector__XXX
 SG_ RCM_a020_eventFrontRightSeatbelt m20 : 27|1@1+ (1,0) [0|1] "" Vector__XXX
 SG_ RCM_a020_eventVehicleSpeed m20 : 28|12@1+ (0.08,-40) [-40|287.6] "kph" Vector__XXX
 SG_ RCM_a020_eventSteeringAngle m20 : 45|14@0+ (0.1,-819.2) [-819.2|819.1] "deg" Vector__XXX
 SG_ RCM_a020_eventDriverBrakeApply m20 : 46|2@1+ (1,0) [0|2] "" Vector__XXX
 SG_ RCM_a020_eventAccelPedalPos m20 : 56|8@1+ (0.4,0) [0|101.6] "%" Vector__XXX
 SG_ RCM_a021_eventArmStatus m21 : 11|1@1+ (1,0) [0|1] "" Vector__XXX
 SG_ RCM_a021_eventFactoryMode m21 : 12|1@1+ (1,0) [0|1] "" Vector__XXX
 SG_ RCM_a021_eventDiagEnabled m21 : 13|1@1+ (1,0) [0|1] "" Vector__XXX
 SG_ RCM_a021_eventDriveOrientation m21 : 14|1@1+ (1,0) [0|1] "" Vector__XXX
 SG_ RCM_a021_pretenLapLeftSht2Gnd m21 : 16|1@1+ (1,0) [0|1] "" Vector__XXX
 SG_ RCM_a021_pretenLapLeftSht2Bat m21 : 17|1@1+ (1,0) [0|1] "" Vector__XXX
 SG_ RCM_a021_pretenLapLeftOpen m21 : 18|1@1+ (1,0) [0|1] "" Vector__XXX
 SG_ RCM_a021_pretenLapLeftShort m21 : 19|1@1+ (1,0) [0|1] "" Vector__XXX
 SG_ RCM_a021_pretenLapLeftCrossCoup m21 : 20|1@1+ (1,0) [0|1] "" Vector__XXX
 SG_ RCM_a021_pretenLapLeftConfig m21 : 21|1@1+ (1,0) [0|1] "" Vector__XXX
 SG_ RCM_a021_eventIDFsignal m21 : 25|1@1+ (1,0) [0|1] "" Vector__XXX
 SG_ RCM_a021_eventFrontLeftSeatbelt m21 : 26|1@1+ (1,0) [0|1] "" Vector__XXX
 SG_ RCM_a021_eventFrontRightSeatbelt m21 : 27|1@1+ (1,0) [0|1] "" Vector__XXX
 SG_ RCM_a021_eventVehicleSpeed m21 : 28|12@1+ (0.08,-40) [-40|287.6] "kph" Vector__XXX
 SG_ RCM_a021_eventSteeringAngle m21 : 45|14@0+ (0.1,-819.2) [-819.2|819.1] "deg" Vector__XXX
 SG_ RCM_a021_eventDriverBrakeApply m21 : 46|2@1+ (1,0) [0|2] "" Vector__XXX
 SG_ RCM_a021_eventAccelPedalPos m21 : 56|8@1+ (0.4,0) [0|101.6] "%" Vector__XXX
 SG_ RCM_a022_eventArmStatus m22 : 11|1@1+ (1,0) [0|1] "" Vector__XXX
 SG_ RCM_a022_eventFactoryMode m22 : 12|1@1+ (1,0) [0|1] "" Vector__XXX
 SG_ RCM_a022_eventDiagEnabled m22 : 13|1@1+ (1,0) [0|1] "" Vector__XXX
 SG_ RCM_a022_eventDriveOrientation m22 : 14|1@1+ (1,0) [0|1] "" Vector__XXX
 SG_ RCM_a022_pretenLapRightSht2Gnd m22 : 16|1@1+ (1,0) [0|1] "" Vector__XXX
 SG_ RCM_a022_pretenLapRightSht2Bat m22 : 17|1@1+ (1,0) [0|1] "" Vector__XXX
 SG_ RCM_a022_pretenLapRightOpen m22 : 18|1@1+ (1,0) [0|1] "" Vector__XXX
 SG_ RCM_a022_pretenLapRightShort m22 : 19|1@1+ (1,0) [0|1] "" Vector__XXX
 SG_ RCM_a022_pretenLapRightCrossCoup m22 : 20|1@1+ (1,0) [0|1] "" Vector__XXX
 SG_ RCM_a022_pretenLapRightConfig m22 : 21|1@1+ (1,0) [0|1] "" Vector__XXX
 SG_ RCM_a022_eventIDFsignal m22 : 25|1@1+ (1,0) [0|1] "" Vector__XXX
 SG_ RCM_a022_eventFrontLeftSeatbelt m22 : 26|1@1+ (1,0) [0|1] "" Vector__XXX
 SG_ RCM_a022_eventFrontRightSeatbelt m22 : 27|1@1+ (1,0) [0|1] "" Vector__XXX
 SG_ RCM_a022_eventVehicleSpeed m22 : 28|12@1+ (0.08,-40) [-40|287.6] "kph" Vector__XXX
 SG_ RCM_a022_eventSteeringAngle m22 : 45|14@0+ (0.1,-819.2) [-819.2|819.1] "deg" Vector__XXX
 SG_ RCM_a022_eventDriverBrakeApply m22 : 46|2@1+ (1,0) [0|2] "" Vector__XXX
 SG_ RCM_a022_eventAccelPedalPos m22 : 56|8@1+ (0.4,0) [0|101.6] "%" Vector__XXX
 SG_ RCM_a023_eventArmStatus m23 : 11|1@1+ (1,0) [0|1] "" Vector__XXX
 SG_ RCM_a023_eventFactoryMode m23 : 12|1@1+ (1,0) [0|1] "" Vector__XXX
 SG_ RCM_a023_eventDiagEnabled m23 : 13|1@1+ (1,0) [0|1] "" Vector__XXX
 SG_ RCM_a023_eventDriveOrientation m23 : 14|1@1+ (1,0) [0|1] "" Vector__XXX
 SG_ RCM_a023_loadLimLeftSht2Gnd m23 : 16|1@1+ (1,0) [0|1] "" Vector__XXX
 SG_ RCM_a023_loadLimLeftSht2Bat m23 : 17|1@1+ (1,0) [0|1] "" Vector__XXX
 SG_ RCM_a023_loadLimLeftOpen m23 : 18|1@1+ (1,0) [0|1] "" Vector__XXX
 SG_ RCM_a023_loadLimLeftShort m23 : 19|1@1+ (1,0) [0|1] "" Vector__XXX
 SG_ RCM_a023_loadLimLeftCrossCoup m23 : 20|1@1+ (1,0) [0|1] "" Vector__XXX
 SG_ RCM_a023_loadLimLeftConfig m23 : 21|1@1+ (1,0) [0|1] "" Vector__XXX
 SG_ RCM_a023_eventIDFsignal m23 : 25|1@1+ (1,0) [0|1] "" Vector__XXX
 SG_ RCM_a023_eventFrontLeftSeatbelt m23 : 26|1@1+ (1,0) [0|1] "" Vector__XXX
 SG_ RCM_a023_eventFrontRightSeatbelt m23 : 27|1@1+ (1,0) [0|1] "" Vector__XXX
 SG_ RCM_a023_eventVehicleSpeed m23 : 28|12@1+ (0.08,-40) [-40|287.6] "kph" Vector__XXX
 SG_ RCM_a023_eventSteeringAngle m23 : 45|14@0+ (0.1,-819.2) [-819.2|819.1] "deg" Vector__XXX
 SG_ RCM_a023_eventDriverBrakeApply m23 : 46|2@1+ (1,0) [0|2] "" Vector__XXX
 SG_ RCM_a023_eventAccelPedalPos m23 : 56|8@1+ (0.4,0) [0|101.6] "%" Vector__XXX
 SG_ RCM_a024_eventArmStatus m24 : 11|1@1+ (1,0) [0|1] "" Vector__XXX
 SG_ RCM_a024_eventFactoryMode m24 : 12|1@1+ (1,0) [0|1] "" Vector__XXX
 SG_ RCM_a024_eventDiagEnabled m24 : 13|1@1+ (1,0) [0|1] "" Vector__XXX
 SG_ RCM_a024_eventDriveOrientation m24 : 14|1@1+ (1,0) [0|1] "" Vector__XXX
 SG_ RCM_a024_loadLimRightSht2Gnd m24 : 16|1@1+ (1,0) [0|1] "" Vector__XXX
 SG_ RCM_a024_loadLimRightSht2Bat m24 : 17|1@1+ (1,0) [0|1] "" Vector__XXX
 SG_ RCM_a024_loadLimRightOpen m24 : 18|1@1+ (1,0) [0|1] "" Vector__XXX
 SG_ RCM_a024_loadLimRightShort m24 : 19|1@1+ (1,0) [0|1] "" Vector__XXX
 SG_ RCM_a024_loadLimRightCrossCoup m24 : 20|1@1+ (1,0) [0|1] "" Vector__XXX
 SG_ RCM_a024_loadLimRightConfig m24 : 21|1@1+ (1,0) [0|1] "" Vector__XXX
 SG_ RCM_a024_eventIDFsignal m24 : 25|1@1+ (1,0) [0|1] "" Vector__XXX
 SG_ RCM_a024_eventFrontLeftSeatbelt m24 : 26|1@1+ (1,0) [0|1] "" Vector__XXX
 SG_ RCM_a024_eventFrontRightSeatbelt m24 : 27|1@1+ (1,0) [0|1] "" Vector__XXX
 SG_ RCM_a024_eventVehicleSpeed m24 : 28|12@1+ (0.08,-40) [-40|287.6] "kph" Vector__XXX
 SG_ RCM_a024_eventSteeringAngle m24 : 45|14@0+ (0.1,-819.2) [-819.2|819.1] "deg" Vector__XXX
 SG_ RCM_a024_eventDriverBrakeApply m24 : 46|2@1+ (1,0) [0|2] "" Vector__XXX
 SG_ RCM_a024_eventAccelPedalPos m24 : 56|8@1+ (0.4,0) [0|101.6] "%" Vector__XXX
 SG_ RCM_a025_eventArmStatus m25 : 11|1@1+ (1,0) [0|1] "" Vector__XXX
 SG_ RCM_a025_eventFactoryMode m25 : 12|1@1+ (1,0) [0|1] "" Vector__XXX
 SG_ RCM_a025_eventDiagEnabled m25 : 13|1@1+ (1,0) [0|1] "" Vector__XXX
 SG_ RCM_a025_eventDriveOrientation m25 : 14|1@1+ (1,0) [0|1] "" Vector__XXX
 SG_ RCM_a025_kneeABDrvrSht2Gnd m25 : 16|1@1+ (1,0) [0|1] "" Vector__XXX
 SG_ RCM_a025_kneeABDrvrSht2Bat m25 : 17|1@1+ (1,0) [0|1] "" Vector__XXX
 SG_ RCM_a025_kneeABDrvrOpen m25 : 18|1@1+ (1,0) [0|1] "" Vector__XXX
 SG_ RCM_a025_kneeABDrvrShort m25 : 19|1@1+ (1,0) [0|1] "" Vector__XXX
 SG_ RCM_a025_kneeABDrvrCrossCoup m25 : 20|1@1+ (1,0) [0|1] "" Vector__XXX
 SG_ RCM_a025_kneeABDrvrConfig m25 : 21|1@1+ (1,0) [0|1] "" Vector__XXX
 SG_ RCM_a025_eventIDFsignal m25 : 25|1@1+ (1,0) [0|1] "" Vector__XXX
 SG_ RCM_a025_eventFrontLeftSeatbelt m25 : 26|1@1+ (1,0) [0|1] "" Vector__XXX
 SG_ RCM_a025_eventFrontRightSeatbelt m25 : 27|1@1+ (1,0) [0|1] "" Vector__XXX
 SG_ RCM_a025_eventVehicleSpeed m25 : 28|12@1+ (0.08,-40) [-40|287.6] "kph" Vector__XXX
 SG_ RCM_a025_eventSteeringAngle m25 : 45|14@0+ (0.1,-819.2) [-819.2|819.1] "deg" Vector__XXX
 SG_ RCM_a025_eventDriverBrakeApply m25 : 46|2@1+ (1,0) [0|2] "" Vector__XXX
 SG_ RCM_a025_eventAccelPedalPos m25 : 56|8@1+ (0.4,0) [0|101.6] "%" Vector__XXX
 SG_ RCM_a026_eventArmStatus m26 : 11|1@1+ (1,0) [0|1] "" Vector__XXX
 SG_ RCM_a026_eventFactoryMode m26 : 12|1@1+ (1,0) [0|1] "" Vector__XXX
 SG_ RCM_a026_eventDiagEnabled m26 : 13|1@1+ (1,0) [0|1] "" Vector__XXX
 SG_ RCM_a026_eventDriveOrientation m26 : 14|1@1+ (1,0) [0|1] "" Vector__XXX
 SG_ RCM_a026_kneeABPassSht2Gnd m26 : 16|1@1+ (1,0) [0|1] "" Vector__XXX
 SG_ RCM_a026_kneeABPassSht2Bat m26 : 17|1@1+ (1,0) [0|1] "" Vector__XXX
 SG_ RCM_a026_kneeABPassOpen m26 : 18|1@1+ (1,0) [0|1] "" Vector__XXX
 SG_ RCM_a026_kneeABPassShort m26 : 19|1@1+ (1,0) [0|1] "" Vector__XXX
 SG_ RCM_a026_kneeABPassCrossCoup m26 : 20|1@1+ (1,0) [0|1] "" Vector__XXX
 SG_ RCM_a026_kneeABPassConfig m26 : 21|1@1+ (1,0) [0|1] "" Vector__XXX
 SG_ RCM_a026_eventIDFsignal m26 : 25|1@1+ (1,0) [0|1] "" Vector__XXX
 SG_ RCM_a026_eventFrontLeftSeatbelt m26 : 26|1@1+ (1,0) [0|1] "" Vector__XXX
 SG_ RCM_a026_eventFrontRightSeatbelt m26 : 27|1@1+ (1,0) [0|1] "" Vector__XXX
 SG_ RCM_a026_eventVehicleSpeed m26 : 28|12@1+ (0.08,-40) [-40|287.6] "kph" Vector__XXX
 SG_ RCM_a026_eventSteeringAngle m26 : 45|14@0+ (0.1,-819.2) [-819.2|819.1] "deg" Vector__XXX
 SG_ RCM_a026_eventDriverBrakeApply m26 : 46|2@1+ (1,0) [0|2] "" Vector__XXX
 SG_ RCM_a026_eventAccelPedalPos m26 : 56|8@1+ (0.4,0) [0|101.6] "%" Vector__XXX
 SG_ RCM_a027_eventArmStatus m27 : 11|1@1+ (1,0) [0|1] "" Vector__XXX
 SG_ RCM_a027_eventFactoryMode m27 : 12|1@1+ (1,0) [0|1] "" Vector__XXX
 SG_ RCM_a027_eventDiagEnabled m27 : 13|1@1+ (1,0) [0|1] "" Vector__XXX
 SG_ RCM_a027_eventDriveOrientation m27 : 14|1@1+ (1,0) [0|1] "" Vector__XXX
 SG_ RCM_a027_sideAB1stRowLSht2Gnd m27 : 16|1@1+ (1,0) [0|1] "" Vector__XXX
 SG_ RCM_a027_sideAB1stRowLSht2Bat m27 : 17|1@1+ (1,0) [0|1] "" Vector__XXX
 SG_ RCM_a027_sideAB1stRowLOpen m27 : 18|1@1+ (1,0) [0|1] "" Vector__XXX
 SG_ RCM_a027_sideAB1stRowLShort m27 : 19|1@1+ (1,0) [0|1] "" Vector__XXX
 SG_ RCM_a027_sideAB1stRowLCrossCoup m27 : 20|1@1+ (1,0) [0|1] "" Vector__XXX
 SG_ RCM_a027_sideAB1stRowLConfig m27 : 21|1@1+ (1,0) [0|1] "" Vector__XXX
 SG_ RCM_a027_eventIDFsignal m27 : 25|1@1+ (1,0) [0|1] "" Vector__XXX
 SG_ RCM_a027_eventFrontLeftSeatbelt m27 : 26|1@1+ (1,0) [0|1] "" Vector__XXX
 SG_ RCM_a027_eventFrontRightSeatbelt m27 : 27|1@1+ (1,0) [0|1] "" Vector__XXX
 SG_ RCM_a027_eventVehicleSpeed m27 : 28|12@1+ (0.08,-40) [-40|287.6] "kph" Vector__XXX
 SG_ RCM_a027_eventSteeringAngle m27 : 45|14@0+ (0.1,-819.2) [-819.2|819.1] "deg" Vector__XXX
 SG_ RCM_a027_eventDriverBrakeApply m27 : 46|2@1+ (1,0) [0|2] "" Vector__XXX
 SG_ RCM_a027_eventAccelPedalPos m27 : 56|8@1+ (0.4,0) [0|101.6] "%" Vector__XXX
 SG_ RCM_a028_eventArmStatus m28 : 11|1@1+ (1,0) [0|1] "" Vector__XXX
 SG_ RCM_a028_eventFactoryMode m28 : 12|1@1+ (1,0) [0|1] "" Vector__XXX
 SG_ RCM_a028_eventDiagEnabled m28 : 13|1@1+ (1,0) [0|1] "" Vector__XXX
 SG_ RCM_a028_eventDriveOrientation m28 : 14|1@1+ (1,0) [0|1] "" Vector__XXX
 SG_ RCM_a028_sideAB1stRowRSht2Gnd m28 : 16|1@1+ (1,0) [0|1] "" Vector__XXX
 SG_ RCM_a028_sideAB1stRowRSht2Bat m28 : 17|1@1+ (1,0) [0|1] "" Vector__XXX
 SG_ RCM_a028_sideAB1stRowROpen m28 : 18|1@1+ (1,0) [0|1] "" Vector__XXX
 SG_ RCM_a028_sideAB1stRowRShort m28 : 19|1@1+ (1,0) [0|1] "" Vector__XXX
 SG_ RCM_a028_sideAB1stRowRCrossCoup m28 : 20|1@1+ (1,0) [0|1] "" Vector__XXX
 SG_ RCM_a028_sideAB1stRowRConfig m28 : 21|1@1+ (1,0) [0|1] "" Vector__XXX
 SG_ RCM_a028_eventIDFsignal m28 : 25|1@1+ (1,0) [0|1] "" Vector__XXX
 SG_ RCM_a028_eventFrontLeftSeatbelt m28 : 26|1@1+ (1,0) [0|1] "" Vector__XXX
 SG_ RCM_a028_eventFrontRightSeatbelt m28 : 27|1@1+ (1,0) [0|1] "" Vector__XXX
 SG_ RCM_a028_eventVehicleSpeed m28 : 28|12@1+ (0.08,-40) [-40|287.6] "kph" Vector__XXX
 SG_ RCM_a028_eventSteeringAngle m28 : 45|14@0+ (0.1,-819.2) [-819.2|819.1] "deg" Vector__XXX
 SG_ RCM_a028_eventDriverBrakeApply m28 : 46|2@1+ (1,0) [0|2] "" Vector__XXX
 SG_ RCM_a028_eventAccelPedalPos m28 : 56|8@1+ (0.4,0) [0|101.6] "%" Vector__XXX
 SG_ RCM_a029_eventArmStatus m29 : 11|1@1+ (1,0) [0|1] "" Vector__XXX
 SG_ RCM_a029_eventFactoryMode m29 : 12|1@1+ (1,0) [0|1] "" Vector__XXX
 SG_ RCM_a029_eventDiagEnabled m29 : 13|1@1+ (1,0) [0|1] "" Vector__XXX
 SG_ RCM_a029_eventDriveOrientation m29 : 14|1@1+ (1,0) [0|1] "" Vector__XXX
 SG_ RCM_a029_driverABAVSht2Gnd m29 : 16|1@1+ (1,0) [0|1] "" Vector__XXX
 SG_ RCM_a029_driverABAVSht2Bat m29 : 17|1@1+ (1,0) [0|1] "" Vector__XXX
 SG_ RCM_a029_driverABAVOpen m29 : 18|1@1+ (1,0) [0|1] "" Vector__XXX
 SG_ RCM_a029_driverABAVShort m29 : 19|1@1+ (1,0) [0|1] "" Vector__XXX
 SG_ RCM_a029_driverABAVCrossCoup m29 : 20|1@1+ (1,0) [0|1] "" Vector__XXX
 SG_ RCM_a029_driverABAVConfig m29 : 21|1@1+ (1,0) [0|1] "" Vector__XXX
 SG_ RCM_a029_eventIDFsignal m29 : 25|1@1+ (1,0) [0|1] "" Vector__XXX
 SG_ RCM_a029_eventFrontLeftSeatbelt m29 : 26|1@1+ (1,0) [0|1] "" Vector__XXX
 SG_ RCM_a029_eventFrontRightSeatbelt m29 : 27|1@1+ (1,0) [0|1] "" Vector__XXX
 SG_ RCM_a029_eventVehicleSpeed m29 : 28|12@1+ (0.08,-40) [-40|287.6] "kph" Vector__XXX
 SG_ RCM_a029_eventSteeringAngle m29 : 45|14@0+ (0.1,-819.2) [-819.2|819.1] "deg" Vector__XXX
 SG_ RCM_a029_eventDriverBrakeApply m29 : 46|2@1+ (1,0) [0|2] "" Vector__XXX
 SG_ RCM_a029_eventAccelPedalPos m29 : 56|8@1+ (0.4,0) [0|101.6] "%" Vector__XXX
 SG_ RCM_a030_eventArmStatus m30 : 11|1@1+ (1,0) [0|1] "" Vector__XXX
 SG_ RCM_a030_eventFactoryMode m30 : 12|1@1+ (1,0) [0|1] "" Vector__XXX
 SG_ RCM_a030_eventDiagEnabled m30 : 13|1@1+ (1,0) [0|1] "" Vector__XXX
 SG_ RCM_a030_eventDriveOrientation m30 : 14|1@1+ (1,0) [0|1] "" Vector__XXX
 SG_ RCM_a030_farsideABSht2Gnd m30 : 16|1@1+ (1,0) [0|1] "" Vector__XXX
 SG_ RCM_a030_farsideABSht2Bat m30 : 17|1@1+ (1,0) [0|1] "" Vector__XXX
 SG_ RCM_a030_farsideABOpen m30 : 18|1@1+ (1,0) [0|1] "" Vector__XXX
 SG_ RCM_a030_farsideABShort m30 : 19|1@1+ (1,0) [0|1] "" Vector__XXX
 SG_ RCM_a030_farsideABCrossCoup m30 : 20|1@1+ (1,0) [0|1] "" Vector__XXX
 SG_ RCM_a030_farsideABConfig m30 : 21|1@1+ (1,0) [0|1] "" Vector__XXX
 SG_ RCM_a030_eventIDFsignal m30 : 25|1@1+ (1,0) [0|1] "" Vector__XXX
 SG_ RCM_a030_eventFrontLeftSeatbelt m30 : 26|1@1+ (1,0) [0|1] "" Vector__XXX
 SG_ RCM_a030_eventFrontRightSeatbelt m30 : 27|1@1+ (1,0) [0|1] "" Vector__XXX
 SG_ RCM_a030_eventVehicleSpeed m30 : 28|12@1+ (0.08,-40) [-40|287.6] "kph" Vector__XXX
 SG_ RCM_a030_eventSteeringAngle m30 : 45|14@0+ (0.1,-819.2) [-819.2|819.1] "deg" Vector__XXX
 SG_ RCM_a030_eventDriverBrakeApply m30 : 46|2@1+ (1,0) [0|2] "" Vector__XXX
 SG_ RCM_a030_eventAccelPedalPos m30 : 56|8@1+ (0.4,0) [0|101.6] "%" Vector__XXX
 SG_ RCM_a031_eventArmStatus m31 : 11|1@1+ (1,0) [0|1] "" Vector__XXX
 SG_ RCM_a031_eventFactoryMode m31 : 12|1@1+ (1,0) [0|1] "" Vector__XXX
 SG_ RCM_a031_eventDiagEnabled m31 : 13|1@1+ (1,0) [0|1] "" Vector__XXX
 SG_ RCM_a031_eventDriveOrientation m31 : 14|1@1+ (1,0) [0|1] "" Vector__XXX
 SG_ RCM_a031_frntCentrABSht2Gnd m31 : 16|1@1+ (1,0) [0|1] "" Vector__XXX
 SG_ RCM_a031_frntCentrABSht2Bat m31 : 17|1@1+ (1,0) [0|1] "" Vector__XXX
 SG_ RCM_a031_frntCentrABOpen m31 : 18|1@1+ (1,0) [0|1] "" Vector__XXX
 SG_ RCM_a031_frntCentrABShort m31 : 19|1@1+ (1,0) [0|1] "" Vector__XXX
 SG_ RCM_a031_frntCentrABCrossCoup m31 : 20|1@1+ (1,0) [0|1] "" Vector__XXX
 SG_ RCM_a031_frntCentrABConfig m31 : 21|1@1+ (1,0) [0|1] "" Vector__XXX
 SG_ RCM_a031_eventIDFsignal m31 : 25|1@1+ (1,0) [0|1] "" Vector__XXX
 SG_ RCM_a031_eventFrontLeftSeatbelt m31 : 26|1@1+ (1,0) [0|1] "" Vector__XXX
 SG_ RCM_a031_eventFrontRightSeatbelt m31 : 27|1@1+ (1,0) [0|1] "" Vector__XXX
 SG_ RCM_a031_eventVehicleSpeed m31 : 28|12@1+ (0.08,-40) [-40|287.6] "kph" Vector__XXX
 SG_ RCM_a031_eventSteeringAngle m31 : 45|14@0+ (0.1,-819.2) [-819.2|819.1] "deg" Vector__XXX
 SG_ RCM_a031_eventDriverBrakeApply m31 : 46|2@1+ (1,0) [0|2] "" Vector__XXX
 SG_ RCM_a031_eventAccelPedalPos m31 : 56|8@1+ (0.4,0) [0|101.6] "%" Vector__XXX
 SG_ RCM_a032_eventArmStatus m32 : 11|1@1+ (1,0) [0|1] "" Vector__XXX
 SG_ RCM_a032_eventFactoryMode m32 : 12|1@1+ (1,0) [0|1] "" Vector__XXX
 SG_ RCM_a032_eventDiagEnabled m32 : 13|1@1+ (1,0) [0|1] "" Vector__XXX
 SG_ RCM_a032_eventDriveOrientation m32 : 14|1@1+ (1,0) [0|1] "" Vector__XXX
 SG_ RCM_a032_curABLeftSht2Gnd m32 : 16|1@1+ (1,0) [0|1] "" Vector__XXX
 SG_ RCM_a032_curABLeftSht2Bat m32 : 17|1@1+ (1,0) [0|1] "" Vector__XXX
 SG_ RCM_a032_curABLeftOpen m32 : 18|1@1+ (1,0) [0|1] "" Vector__XXX
 SG_ RCM_a032_curABLeftShort m32 : 19|1@1+ (1,0) [0|1] "" Vector__XXX
 SG_ RCM_a032_curABLeftCrossCoup m32 : 20|1@1+ (1,0) [0|1] "" Vector__XXX
 SG_ RCM_a032_curABLeftConfig m32 : 21|1@1+ (1,0) [0|1] "" Vector__XXX
 SG_ RCM_a032_eventIDFsignal m32 : 25|1@1+ (1,0) [0|1] "" Vector__XXX
 SG_ RCM_a032_eventFrontLeftSeatbelt m32 : 26|1@1+ (1,0) [0|1] "" Vector__XXX
 SG_ RCM_a032_eventFrontRightSeatbelt m32 : 27|1@1+ (1,0) [0|1] "" Vector__XXX
 SG_ RCM_a032_eventVehicleSpeed m32 : 28|12@1+ (0.08,-40) [-40|287.6] "kph" Vector__XXX
 SG_ RCM_a032_eventSteeringAngle m32 : 45|14@0+ (0.1,-819.2) [-819.2|819.1] "deg" Vector__XXX
 SG_ RCM_a032_eventDriverBrakeApply m32 : 46|2@1+ (1,0) [0|2] "" Vector__XXX
 SG_ RCM_a032_eventAccelPedalPos m32 : 56|8@1+ (0.4,0) [0|101.6] "%" Vector__XXX
 SG_ RCM_a033_eventArmStatus m33 : 11|1@1+ (1,0) [0|1] "" Vector__XXX
 SG_ RCM_a033_eventFactoryMode m33 : 12|1@1+ (1,0) [0|1] "" Vector__XXX
 SG_ RCM_a033_eventDiagEnabled m33 : 13|1@1+ (1,0) [0|1] "" Vector__XXX
 SG_ RCM_a033_eventDriveOrientation m33 : 14|1@1+ (1,0) [0|1] "" Vector__XXX
 SG_ RCM_a033_curABRightSht2Gnd m33 : 16|1@1+ (1,0) [0|1] "" Vector__XXX
 SG_ RCM_a033_curABRightSht2Bat m33 : 17|1@1+ (1,0) [0|1] "" Vector__XXX
 SG_ RCM_a033_curABRightOpen m33 : 18|1@1+ (1,0) [0|1] "" Vector__XXX
 SG_ RCM_a033_curABRightShort m33 : 19|1@1+ (1,0) [0|1] "" Vector__XXX
 SG_ RCM_a033_curABRightCrossCoup m33 : 20|1@1+ (1,0) [0|1] "" Vector__XXX
 SG_ RCM_a033_curABRightConfig m33 : 21|1@1+ (1,0) [0|1] "" Vector__XXX
 SG_ RCM_a033_eventIDFsignal m33 : 25|1@1+ (1,0) [0|1] "" Vector__XXX
 SG_ RCM_a033_eventFrontLeftSeatbelt m33 : 26|1@1+ (1,0) [0|1] "" Vector__XXX
 SG_ RCM_a033_eventFrontRightSeatbelt m33 : 27|1@1+ (1,0) [0|1] "" Vector__XXX
 SG_ RCM_a033_eventVehicleSpeed m33 : 28|12@1+ (0.08,-40) [-40|287.6] "kph" Vector__XXX
 SG_ RCM_a033_eventSteeringAngle m33 : 45|14@0+ (0.1,-819.2) [-819.2|819.1] "deg" Vector__XXX
 SG_ RCM_a033_eventDriverBrakeApply m33 : 46|2@1+ (1,0) [0|2] "" Vector__XXX
 SG_ RCM_a033_eventAccelPedalPos m33 : 56|8@1+ (0.4,0) [0|101.6] "%" Vector__XXX
 SG_ RCM_a034_eventArmStatus m34 : 11|1@1+ (1,0) [0|1] "" Vector__XXX
 SG_ RCM_a034_eventFactoryMode m34 : 12|1@1+ (1,0) [0|1] "" Vector__XXX
 SG_ RCM_a034_eventDiagEnabled m34 : 13|1@1+ (1,0) [0|1] "" Vector__XXX
 SG_ RCM_a034_eventDriveOrientation m34 : 14|1@1+ (1,0) [0|1] "" Vector__XXX
 SG_ RCM_a034_preten2ndRowLSht2Gnd m34 : 16|1@1+ (1,0) [0|1] "" Vector__XXX
 SG_ RCM_a034_preten2ndRowLSht2Bat m34 : 17|1@1+ (1,0) [0|1] "" Vector__XXX
 SG_ RCM_a034_preten2ndRowLOpen m34 : 18|1@1+ (1,0) [0|1] "" Vector__XXX
 SG_ RCM_a034_preten2ndRowLShort m34 : 19|1@1+ (1,0) [0|1] "" Vector__XXX
 SG_ RCM_a034_preten2ndRowLCrossCoup m34 : 20|1@1+ (1,0) [0|1] "" Vector__XXX
 SG_ RCM_a034_preten2ndRowLCgf m34 : 21|1@1+ (1,0) [0|1] "" Vector__XXX
 SG_ RCM_a034_eventIDFsignal m34 : 25|1@1+ (1,0) [0|1] "" Vector__XXX
 SG_ RCM_a034_eventFrontLeftSeatbelt m34 : 26|1@1+ (1,0) [0|1] "" Vector__XXX
 SG_ RCM_a034_eventFrontRightSeatbelt m34 : 27|1@1+ (1,0) [0|1] "" Vector__XXX
 SG_ RCM_a034_eventVehicleSpeed m34 : 28|12@1+ (0.08,-40) [-40|287.6] "kph" Vector__XXX
 SG_ RCM_a034_eventSteeringAngle m34 : 45|14@0+ (0.1,-819.2) [-819.2|819.1] "deg" Vector__XXX
 SG_ RCM_a034_eventDriverBrakeApply m34 : 46|2@1+ (1,0) [0|2] "" Vector__XXX
 SG_ RCM_a034_eventAccelPedalPos m34 : 56|8@1+ (0.4,0) [0|101.6] "%" Vector__XXX
 SG_ RCM_a035_eventArmStatus m35 : 11|1@1+ (1,0) [0|1] "" Vector__XXX
 SG_ RCM_a035_eventFactoryMode m35 : 12|1@1+ (1,0) [0|1] "" Vector__XXX
 SG_ RCM_a035_eventDiagEnabled m35 : 13|1@1+ (1,0) [0|1] "" Vector__XXX
 SG_ RCM_a035_eventDriveOrientation m35 : 14|1@1+ (1,0) [0|1] "" Vector__XXX
 SG_ RCM_a035_preten2ndRowRSht2Gnd m35 : 16|1@1+ (1,0) [0|1] "" Vector__XXX
 SG_ RCM_a035_preten2ndRowRSht2Bat m35 : 17|1@1+ (1,0) [0|1] "" Vector__XXX
 SG_ RCM_a035_preten2ndRowROpen m35 : 18|1@1+ (1,0) [0|1] "" Vector__XXX
 SG_ RCM_a035_preten2ndRowRShort m35 : 19|1@1+ (1,0) [0|1] "" Vector__XXX
 SG_ RCM_a035_preten2ndRowRCrossCoup m35 : 20|1@1+ (1,0) [0|1] "" Vector__XXX
 SG_ RCM_a035_preten2ndRowRCgf m35 : 21|1@1+ (1,0) [0|1] "" Vector__XXX
 SG_ RCM_a035_eventIDFsignal m35 : 25|1@1+ (1,0) [0|1] "" Vector__XXX
 SG_ RCM_a035_eventFrontLeftSeatbelt m35 : 26|1@1+ (1,0) [0|1] "" Vector__XXX
 SG_ RCM_a035_eventFrontRightSeatbelt m35 : 27|1@1+ (1,0) [0|1] "" Vector__XXX
 SG_ RCM_a035_eventVehicleSpeed m35 : 28|12@1+ (0.08,-40) [-40|287.6] "kph" Vector__XXX
 SG_ RCM_a035_eventSteeringAngle m35 : 45|14@0+ (0.1,-819.2) [-819.2|819.1] "deg" Vector__XXX
 SG_ RCM_a035_eventDriverBrakeApply m35 : 46|2@1+ (1,0) [0|2] "" Vector__XXX
 SG_ RCM_a035_eventAccelPedalPos m35 : 56|8@1+ (0.4,0) [0|101.6] "%" Vector__XXX
 SG_ RCM_a036_eventArmStatus m36 : 11|1@1+ (1,0) [0|1] "" Vector__XXX
 SG_ RCM_a036_eventFactoryMode m36 : 12|1@1+ (1,0) [0|1] "" Vector__XXX
 SG_ RCM_a036_eventDiagEnabled m36 : 13|1@1+ (1,0) [0|1] "" Vector__XXX
 SG_ RCM_a036_eventDriveOrientation m36 : 14|1@1+ (1,0) [0|1] "" Vector__XXX
 SG_ RCM_a036_curAB2ndRowLSht2Gnd m36 : 16|1@1+ (1,0) [0|1] "" Vector__XXX
 SG_ RCM_a036_curAB2ndRowLSht2Bat m36 : 17|1@1+ (1,0) [0|1] "" Vector__XXX
 SG_ RCM_a036_curAB2ndRowLOpen m36 : 18|1@1+ (1,0) [0|1] "" Vector__XXX
 SG_ RCM_a036_curAB2ndRowLShort m36 : 19|1@1+ (1,0) [0|1] "" Vector__XXX
 SG_ RCM_a036_curAB2ndRowLCrossCoup m36 : 20|1@1+ (1,0) [0|1] "" Vector__XXX
 SG_ RCM_a036_curAB2ndRowLConfig m36 : 21|1@1+ (1,0) [0|1] "" Vector__XXX
 SG_ RCM_a036_eventIDFsignal m36 : 25|1@1+ (1,0) [0|1] "" Vector__XXX
 SG_ RCM_a036_eventFrontLeftSeatbelt m36 : 26|1@1+ (1,0) [0|1] "" Vector__XXX
 SG_ RCM_a036_eventFrontRightSeatbelt m36 : 27|1@1+ (1,0) [0|1] "" Vector__XXX
 SG_ RCM_a036_eventVehicleSpeed m36 : 28|12@1+ (0.08,-40) [-40|287.6] "kph" Vector__XXX
 SG_ RCM_a036_eventSteeringAngle m36 : 45|14@0+ (0.1,-819.2) [-819.2|819.1] "deg" Vector__XXX
 SG_ RCM_a036_eventDriverBrakeApply m36 : 46|2@1+ (1,0) [0|2] "" Vector__XXX
 SG_ RCM_a036_eventAccelPedalPos m36 : 56|8@1+ (0.4,0) [0|101.6] "%" Vector__XXX
 SG_ RCM_a037_eventArmStatus m37 : 11|1@1+ (1,0) [0|1] "" Vector__XXX
 SG_ RCM_a037_eventFactoryMode m37 : 12|1@1+ (1,0) [0|1] "" Vector__XXX
 SG_ RCM_a037_eventDiagEnabled m37 : 13|1@1+ (1,0) [0|1] "" Vector__XXX
 SG_ RCM_a037_eventDriveOrientation m37 : 14|1@1+ (1,0) [0|1] "" Vector__XXX
 SG_ RCM_a037_curAB2ndRowRSht2Gnd m37 : 16|1@1+ (1,0) [0|1] "" Vector__XXX
 SG_ RCM_a037_curAB2ndRowRSht2Bat m37 : 17|1@1+ (1,0) [0|1] "" Vector__XXX
 SG_ RCM_a037_curAB2ndRowROpen m37 : 18|1@1+ (1,0) [0|1] "" Vector__XXX
 SG_ RCM_a037_curAB2ndRowRShort m37 : 19|1@1+ (1,0) [0|1] "" Vector__XXX
 SG_ RCM_a037_curAB2ndRowRCrossCoup m37 : 20|1@1+ (1,0) [0|1] "" Vector__XXX
 SG_ RCM_a037_curAB2ndRowRConfig m37 : 21|1@1+ (1,0) [0|1] "" Vector__XXX
 SG_ RCM_a037_eventIDFsignal m37 : 25|1@1+ (1,0) [0|1] "" Vector__XXX
 SG_ RCM_a037_eventFrontLeftSeatbelt m37 : 26|1@1+ (1,0) [0|1] "" Vector__XXX
 SG_ RCM_a037_eventFrontRightSeatbelt m37 : 27|1@1+ (1,0) [0|1] "" Vector__XXX
 SG_ RCM_a037_eventVehicleSpeed m37 : 28|12@1+ (0.08,-40) [-40|287.6] "kph" Vector__XXX
 SG_ RCM_a037_eventSteeringAngle m37 : 45|14@0+ (0.1,-819.2) [-819.2|819.1] "deg" Vector__XXX
 SG_ RCM_a037_eventDriverBrakeApply m37 : 46|2@1+ (1,0) [0|2] "" Vector__XXX
 SG_ RCM_a037_eventAccelPedalPos m37 : 56|8@1+ (0.4,0) [0|101.6] "%" Vector__XXX
 SG_ RCM_a040_eventArmStatus m40 : 11|1@1+ (1,0) [0|1] "" Vector__XXX
 SG_ RCM_a040_eventFactoryMode m40 : 12|1@1+ (1,0) [0|1] "" Vector__XXX
 SG_ RCM_a040_eventDiagEnabled m40 : 13|1@1+ (1,0) [0|1] "" Vector__XXX
 SG_ RCM_a040_eventDriveOrientation m40 : 14|1@1+ (1,0) [0|1] "" Vector__XXX
 SG_ RCM_a040_hoodActuatorRSht2Gnd m40 : 16|1@1+ (1,0) [0|1] "" Vector__XXX
 SG_ RCM_a040_hoodActuatorRSht2Bat m40 : 17|1@1+ (1,0) [0|1] "" Vector__XXX
 SG_ RCM_a040_hoodActuatorROpen m40 : 18|1@1+ (1,0) [0|1] "" Vector__XXX
 SG_ RCM_a040_hoodActuatorRShort m40 : 19|1@1+ (1,0) [0|1] "" Vector__XXX
 SG_ RCM_a040_hoodActuatorRCrossCoup m40 : 20|1@1+ (1,0) [0|1] "" Vector__XXX
 SG_ RCM_a040_hoodActuatorRConfig m40 : 21|1@1+ (1,0) [0|1] "" Vector__XXX
 SG_ RCM_a040_eventIDFsignal m40 : 25|1@1+ (1,0) [0|1] "" Vector__XXX
 SG_ RCM_a040_eventFrontLeftSeatbelt m40 : 26|1@1+ (1,0) [0|1] "" Vector__XXX
 SG_ RCM_a040_eventFrontRightSeatbelt m40 : 27|1@1+ (1,0) [0|1] "" Vector__XXX
 SG_ RCM_a040_eventVehicleSpeed m40 : 28|12@1+ (0.08,-40) [-40|287.6] "kph" Vector__XXX
 SG_ RCM_a040_eventSteeringAngle m40 : 45|14@0+ (0.1,-819.2) [-819.2|819.1] "deg" Vector__XXX
 SG_ RCM_a040_eventDriverBrakeApply m40 : 46|2@1+ (1,0) [0|2] "" Vector__XXX
 SG_ RCM_a040_eventAccelPedalPos m40 : 56|8@1+ (0.4,0) [0|101.6] "%" Vector__XXX
 SG_ RCM_a041_eventArmStatus m41 : 11|1@1+ (1,0) [0|1] "" Vector__XXX
 SG_ RCM_a041_eventFactoryMode m41 : 12|1@1+ (1,0) [0|1] "" Vector__XXX
 SG_ RCM_a041_eventDiagEnabled m41 : 13|1@1+ (1,0) [0|1] "" Vector__XXX
 SG_ RCM_a041_eventDriveOrientation m41 : 14|1@1+ (1,0) [0|1] "" Vector__XXX
 SG_ RCM_a041_hoodActuatorLSht2Gnd m41 : 16|1@1+ (1,0) [0|1] "" Vector__XXX
 SG_ RCM_a041_hoodActuatorLSht2Bat m41 : 17|1@1+ (1,0) [0|1] "" Vector__XXX
 SG_ RCM_a041_hoodActuatorLOpen m41 : 18|1@1+ (1,0) [0|1] "" Vector__XXX
 SG_ RCM_a041_hoodActuatorLShort m41 : 19|1@1+ (1,0) [0|1] "" Vector__XXX
 SG_ RCM_a041_hoodActuatorLCrossCoup m41 : 20|1@1+ (1,0) [0|1] "" Vector__XXX
 SG_ RCM_a041_hoodActuatorLConfig m41 : 21|1@1+ (1,0) [0|1] "" Vector__XXX
 SG_ RCM_a041_eventIDFsignal m41 : 25|1@1+ (1,0) [0|1] "" Vector__XXX
 SG_ RCM_a041_eventFrontLeftSeatbelt m41 : 26|1@1+ (1,0) [0|1] "" Vector__XXX
 SG_ RCM_a041_eventFrontRightSeatbelt m41 : 27|1@1+ (1,0) [0|1] "" Vector__XXX
 SG_ RCM_a041_eventVehicleSpeed m41 : 28|12@1+ (0.08,-40) [-40|287.6] "kph" Vector__XXX
 SG_ RCM_a041_eventSteeringAngle m41 : 45|14@0+ (0.1,-819.2) [-819.2|819.1] "deg" Vector__XXX
 SG_ RCM_a041_eventDriverBrakeApply m41 : 46|2@1+ (1,0) [0|2] "" Vector__XXX
 SG_ RCM_a041_eventAccelPedalPos m41 : 56|8@1+ (0.4,0) [0|101.6] "%" Vector__XXX
 SG_ RCM_a042_eventArmStatus m42 : 11|1@1+ (1,0) [0|1] "" Vector__XXX
 SG_ RCM_a042_eventFactoryMode m42 : 12|1@1+ (1,0) [0|1] "" Vector__XXX
 SG_ RCM_a042_eventDiagEnabled m42 : 13|1@1+ (1,0) [0|1] "" Vector__XXX
 SG_ RCM_a042_eventDriveOrientation m42 : 14|1@1+ (1,0) [0|1] "" Vector__XXX
 SG_ RCM_a042_ens1Sht2Bat m42 : 16|1@1+ (1,0) [0|1] "" Vector__XXX
 SG_ RCM_a042_ens1Sht2Gnd m42 : 17|1@1+ (1,0) [0|1] "" Vector__XXX
 SG_ RCM_a042_ens1Config m42 : 18|1@1+ (1,0) [0|1] "" Vector__XXX
 SG_ RCM_a042_eventIDFsignal m42 : 25|1@1+ (1,0) [0|1] "" Vector__XXX
 SG_ RCM_a042_eventFrontLeftSeatbelt m42 : 26|1@1+ (1,0) [0|1] "" Vector__XXX
 SG_ RCM_a042_eventFrontRightSeatbelt m42 : 27|1@1+ (1,0) [0|1] "" Vector__XXX
 SG_ RCM_a042_eventVehicleSpeed m42 : 28|12@1+ (0.08,-40) [-40|287.6] "kph" Vector__XXX
 SG_ RCM_a042_eventSteeringAngle m42 : 45|14@0+ (0.1,-819.2) [-819.2|819.1] "deg" Vector__XXX
 SG_ RCM_a042_eventDriverBrakeApply m42 : 46|2@1+ (1,0) [0|2] "" Vector__XXX
 SG_ RCM_a042_eventAccelPedalPos m42 : 56|8@1+ (0.4,0) [0|101.6] "%" Vector__XXX
 SG_ RCM_a043_eventArmStatus m43 : 11|1@1+ (1,0) [0|1] "" Vector__XXX
 SG_ RCM_a043_eventFactoryMode m43 : 12|1@1+ (1,0) [0|1] "" Vector__XXX
 SG_ RCM_a043_eventDiagEnabled m43 : 13|1@1+ (1,0) [0|1] "" Vector__XXX
 SG_ RCM_a043_eventDriveOrientation m43 : 14|1@1+ (1,0) [0|1] "" Vector__XXX
 SG_ RCM_a043_ens2Sht2Bat m43 : 16|1@1+ (1,0) [0|1] "" Vector__XXX
 SG_ RCM_a043_ens2Sht2Gnd m43 : 17|1@1+ (1,0) [0|1] "" Vector__XXX
 SG_ RCM_a043_ens2Config m43 : 18|1@1+ (1,0) [0|1] "" Vector__XXX
 SG_ RCM_a043_eventIDFsignal m43 : 25|1@1+ (1,0) [0|1] "" Vector__XXX
 SG_ RCM_a043_eventFrontLeftSeatbelt m43 : 26|1@1+ (1,0) [0|1] "" Vector__XXX
 SG_ RCM_a043_eventFrontRightSeatbelt m43 : 27|1@1+ (1,0) [0|1] "" Vector__XXX
 SG_ RCM_a043_eventVehicleSpeed m43 : 28|12@1+ (0.08,-40) [-40|287.6] "kph" Vector__XXX
 SG_ RCM_a043_eventSteeringAngle m43 : 45|14@0+ (0.1,-819.2) [-819.2|819.1] "deg" Vector__XXX
 SG_ RCM_a043_eventDriverBrakeApply m43 : 46|2@1+ (1,0) [0|2] "" Vector__XXX
 SG_ RCM_a043_eventAccelPedalPos m43 : 56|8@1+ (0.4,0) [0|101.6] "%" Vector__XXX
 SG_ RCM_a044_eventArmStatus m44 : 11|1@1+ (1,0) [0|1] "" Vector__XXX
 SG_ RCM_a044_eventFactoryMode m44 : 12|1@1+ (1,0) [0|1] "" Vector__XXX
 SG_ RCM_a044_eventDiagEnabled m44 : 13|1@1+ (1,0) [0|1] "" Vector__XXX
 SG_ RCM_a044_eventDriveOrientation m44 : 14|1@1+ (1,0) [0|1] "" Vector__XXX
 SG_ RCM_a044_upFrontSensorLSht2Gnd m44 : 16|1@1+ (1,0) [0|1] "" Vector__XXX
 SG_ RCM_a044_upFrontSensorLSht2Bat m44 : 17|1@1+ (1,0) [0|1] "" Vector__XXX
 SG_ RCM_a044_upFrontSensorLCrossCoup m44 : 18|1@1+ (1,0) [0|1] "" Vector__XXX
 SG_ RCM_a044_upFrontSensorLComm m44 : 19|1@1+ (1,0) [0|1] "" Vector__XXX
 SG_ RCM_a044_upFrontSensorLInitTyp m44 : 20|1@1+ (1,0) [0|1] "" Vector__XXX
 SG_ RCM_a044_upFrontSensorLOption m44 : 21|1@1+ (1,0) [0|1] "" Vector__XXX
 SG_ RCM_a044_upFrontSensorLplaus m44 : 22|1@1+ (1,0) [0|1] "" Vector__XXX
 SG_ RCM_a044_upFrontSensorLDefect m44 : 23|1@1+ (1,0) [0|1] "" Vector__XXX
 SG_ RCM_a044_eventIDFsignal m44 : 25|1@1+ (1,0) [0|1] "" Vector__XXX
 SG_ RCM_a044_eventFrontLeftSeatbelt m44 : 26|1@1+ (1,0) [0|1] "" Vector__XXX
 SG_ RCM_a044_eventFrontRightSeatbelt m44 : 27|1@1+ (1,0) [0|1] "" Vector__XXX
 SG_ RCM_a044_eventVehicleSpeed m44 : 28|12@1+ (0.08,-40) [-40|287.6] "kph" Vector__XXX
 SG_ RCM_a044_eventSteeringAngle m44 : 45|14@0+ (0.1,-819.2) [-819.2|819.1] "deg" Vector__XXX
 SG_ RCM_a044_eventDriverBrakeApply m44 : 46|2@1+ (1,0) [0|2] "" Vector__XXX
 SG_ RCM_a044_eventAccelPedalPos m44 : 56|8@1+ (0.4,0) [0|101.6] "%" Vector__XXX
 SG_ RCM_a045_eventArmStatus m45 : 11|1@1+ (1,0) [0|1] "" Vector__XXX
 SG_ RCM_a045_eventFactoryMode m45 : 12|1@1+ (1,0) [0|1] "" Vector__XXX
 SG_ RCM_a045_eventDiagEnabled m45 : 13|1@1+ (1,0) [0|1] "" Vector__XXX
 SG_ RCM_a045_eventDriveOrientation m45 : 14|1@1+ (1,0) [0|1] "" Vector__XXX
 SG_ RCM_a045_upFrontSensorRSht2Gnd m45 : 16|1@1+ (1,0) [0|1] "" Vector__XXX
 SG_ RCM_a045_upFrontSensorRSht2Bat m45 : 17|1@1+ (1,0) [0|1] "" Vector__XXX
 SG_ RCM_a045_upFrontSensorRCrossCoup m45 : 18|1@1+ (1,0) [0|1] "" Vector__XXX
 SG_ RCM_a045_upFrontSensorRComm m45 : 19|1@1+ (1,0) [0|1] "" Vector__XXX
 SG_ RCM_a045_upFrontSensorRInitTyp m45 : 20|1@1+ (1,0) [0|1] "" Vector__XXX
 SG_ RCM_a045_upFrontSensorROption m45 : 21|1@1+ (1,0) [0|1] "" Vector__XXX
 SG_ RCM_a045_upFrontSensorRplaus m45 : 22|1@1+ (1,0) [0|1] "" Vector__XXX
 SG_ RCM_a045_upFrontSensorRDefect m45 : 23|1@1+ (1,0) [0|1] "" Vector__XXX
 SG_ RCM_a045_eventIDFsignal m45 : 25|1@1+ (1,0) [0|1] "" Vector__XXX
 SG_ RCM_a045_eventFrontLeftSeatbelt m45 : 26|1@1+ (1,0) [0|1] "" Vector__XXX

BO_TX_BU_ 896 : PM;
BO_TX_BU_ 463 : PM;
BO_TX_BU_ 519 : PTC;
BO_TX_BU_ 1297 : RCM;
CM_ BO_ 896 "PM ECU message: alert matrix2";
CM_ SG_ 896 PM_a066_pmfMIA "PM ECU: a066 pmf MIA";
CM_ SG_ 896 PM_a067_pmrMIA "PM ECU: a067 pmr MIA";
CM_ SG_ 896 PM_a068_brakePedalMonitor "PM ECU: a068 brake pedal monitor";
CM_ SG_ 896 PM_a069_brakeMonitorsUnhealthy "PM ECU: a069 brake monitors unhealthy";
CM_ SG_ 896 PM_a070_brakeTorqueSplitMonitorT "PM ECU: a070 brake torque split monitor trip";
CM_ SG_ 896 PM_a071_baseBrakingMonitor "PM ECU: a071 base braking monitor";
CM_ SG_ 896 PM_a072_brakeTorqueCommandInterf "PM ECU: a072 brake torque command interface";
CM_ SG_ 896 PM_a073_canDataBusC "PM ECU: a073 can data bus c";
CM_ SG_ 896 PM_a074_canHardwareBusC "PM ECU: a074 can hardware bus c";
CM_ SG_ 896 PM_a075_canDataBusD "PM ECU: a075 can data bus d";
CM_ SG_ 896 PM_a076_canHardwareBusD "PM ECU: a076 can hardware bus d";
CM_ SG_ 896 PM_a077_canDataBusE "PM ECU: a077 can data bus e";
CM_ SG_ 896 PM_a078_canHardwareBusE "PM ECU: a078 can hardware bus e";
CM_ SG_ 896 PM_a079_rcuMIA "PM ECU: a079 rcu MIA";
CM_ SG_ 896 PM_a080_exceptionPrefetchAbort "PM ECU: a080 exception prefetch abort";
CM_ SG_ 896 PM_a081_exceptionDataAbort "PM ECU: a081 exception data abort";
CM_ SG_ 896 PM_a082_exceptionDataAbort2 "PM ECU: a082 exception data abort2";
CM_ SG_ 896 PM_a083_ahbWriteError "PM ECU: a083 ahb write error";
CM_ SG_ 896 PM_a084_exceptionMpuFirewall "PM ECU: a084 exception mpu firewall";
CM_ SG_ 896 PM_a085_dpbMIA "PM ECU: a085 dpb MIA";
CM_ SG_ 896 PM_a086_exceptionUndefinedInstru "PM ECU: a086 exception undefined instruction";
CM_ SG_ 896 PM_a087_canHardwareBusLIPC "PM ECU: a087 can hardware bus LIPC";
CM_ SG_ 896 PM_a092_xtalOscillator "PM ECU: a092 xtal oscillator";
CM_ SG_ 896 PM_a093_accelPedalSupply "PM ECU: a093 accel pedal supply";
CM_ SG_ 896 PM_a095_ITPMSTimeoutGNSSConverge "PM ECU: a095 ITPMS timeout GNSS convergence";
CM_ SG_ 896 PM_a096_ITPMSConvergedGNSSAbsRad "PM ECU: a096 ITPMS converged GNSS abs radius times";
CM_ SG_ 896 PM_a098_ITPMSTriggerDebug "PM ECU: a098 ITPMS trigger debug";
CM_ SG_ 896 PM_a099_ITPMSCalibrated "PM ECU: a099 ITPMS calibrated";
CM_ SG_ 896 PM_a100_diTraceInfo1 "PM ECU: a100 di trace info1";
CM_ SG_ 896 PM_a110_indirectTPMSSoftWarningF "PM ECU: a110 indirect TPMS soft warning front left";
CM_ SG_ 896 PM_a111_indirectTPMSSoftWarningF "PM ECU: a111 indirect TPMS soft warning front right";
CM_ SG_ 896 PM_a112_indirectTPMSSoftWarningR "PM ECU: a112 indirect TPMS soft warning rear left";
CM_ SG_ 896 PM_a113_indirectTPMSSoftWarningR "PM ECU: a113 indirect TPMS soft warning rear right";
CM_ SG_ 896 PM_a114_indirectTPMSHardWarningF "PM ECU: a114 indirect TPMS hard warning front left";
CM_ SG_ 896 PM_a115_indirectTPMSHardWarningF "PM ECU: a115 indirect TPMS hard warning front right";
CM_ SG_ 896 PM_a116_indirectTPMSHardWarningR "PM ECU: a116 indirect TPMS hard warning rear left";
CM_ SG_ 896 PM_a117_indirectTPMSHardWarningR "PM ECU: a117 indirect TPMS hard warning rear right";
CM_ SG_ 896 PM_a120_indirectTPMSFaulted "PM ECU: a120 indirect TPMS faulted";
CM_ SG_ 896 PM_a121_unintendedReset2 "PM ECU: a121 unintended reset2";
CM_ BO_ 463 "PM ECU message: system state";
CM_ SG_ 463 PM_torqueCheckState "PM ECU: torque check state";
CM_ SG_ 463 PM_limpRequest "PM ECU: limp request";
CM_ SG_ 463 PM_torqueCommand "PM ECU: torque command; raw 4096 = signal not available (SNA)";
CM_ SG_ 463 PM_torqueState "PM ECU: torque state";
CM_ SG_ 463 PM_hvilSystemStatus "HVIL system status; raw 3 = signal not available (SNA)";
CM_ SG_ 463 PM_sysElecPower "PM ECU: sys elec power; raw 1024 = signal not available (SNA)";
CM_ SG_ 463 PM_sysNumUnitsMia "PM ECU: sys num units mia";
CM_ SG_ 463 PM_sysNumUnitsSna "PM ECU: sys num units sna";
CM_ SG_ 463 PM_sysElecPowerVeryLow "PM ECU: sys elec power very low";
CM_ SG_ 463 PM_systemStateCounter "PM ECU: system state counter";
CM_ SG_ 463 PM_systemStateChecksum "PM ECU: system state checksum";
CM_ BO_ 519 "Cabin heater message: feedback status";
CM_ SG_ 519 PTC_leftFlagFault "Heater left bank fault indication flag";
CM_ SG_ 519 PTC_rightFlagFault "Heater right bank fault indication flag";
CM_ SG_ 519 PTC_leftPowerDerating "Heater left bank power derating state";
CM_ SG_ 519 PTC_rightPowerDerating "Heater right bank power derating state";
CM_ SG_ 519 PTC_ocpEvent "Indication that an over current protection event has occurred";
CM_ SG_ 519 PTC_leftDutyFeedback "Current PWM duty cycle applied to left side of PTC heater";
CM_ SG_ 519 PTC_rightDutyFeedback "Current PWM duty cycle applied to right side of PTC heater";
CM_ SG_ 519 PTC_leftPowerHV "Heater left bank power";
CM_ SG_ 519 PTC_rightPowerHV "Heater right bank power";
CM_ SG_ 519 PTC_leftTempEstOutlet "Cabin heater: left temp est outlet";
CM_ SG_ 519 PTC_rightTempEstOutlet "Cabin heater: right temp est outlet";
CM_ SG_ 519 PTC_tliErrorCount "Heater top level interrupt error count";
CM_ SG_ 519 PTC_tliEvent "Indicator of heater top level interrupt event";
CM_ SG_ 519 PTC_tliSource "Heater top level interrupt event source";
CM_ BO_ 1297 "Restraint control module message: alert log";
CM_ SG_ 1297 RCM_alertID "Restraint control module: alert ID";
CM_ SG_ 1297 RCM_alertState "Restraint control module: alert state";
CM_ SG_ 1297 RCM_a000_eventArmStatus "Restraint control module: a000 event arm status";
CM_ SG_ 1297 RCM_a000_eventFactoryMode "Restraint control module: a000 event factory mode";
CM_ SG_ 1297 RCM_a000_eventDiagEnabled "Restraint control module: a000 event diag enabled";
CM_ SG_ 1297 RCM_a000_eventDriveOrientation "Restraint control module: a000 event drive orientation";
CM_ SG_ 1297 RCM_a000_crashDetectedFront "Restraint control module: a000 crash detected front";
CM_ SG_ 1297 RCM_a000_crashDetectedRear "Restraint control module: a000 crash detected rear";
CM_ SG_ 1297 RCM_a000_crashDetectedLeft "Restraint control module: a000 crash detected left";
CM_ SG_ 1297 RCM_a000_crashDetectedRight "Restraint control module: a000 crash detected right";
CM_ SG_ 1297 RCM_a000_crashDetectedRoll "Restraint control module: a000 crash detected roll";
CM_ SG_ 1297 RCM_a000_crashDetectedPreten "Restraint control module: a000 crash detected preten";
CM_ SG_ 1297 RCM_a000_crashDetectedStage1 "Restraint control module: a000 crash detected stage1";
CM_ SG_ 1297 RCM_a000_crashDetectedStage2 "Restraint control module: a000 crash detected stage2";
CM_ SG_ 1297 RCM_a000_crashDetectedHVpyro "Restraint control module: a000 crash detected h vpyro";
CM_ SG_ 1297 RCM_a000_eventIDFsignal "Restraint control module: a000 event ID fsignal";
CM_ SG_ 1297 RCM_a000_eventFrontLeftSeatbelt "Restraint control module: a000 event front left seatbelt";
CM_ SG_ 1297 RCM_a000_eventFrontRightSeatbelt "Restraint control module: a000 event front right seatbelt";
CM_ SG_ 1297 RCM_a000_eventVehicleSpeed "Restraint control module: a000 event vehicle speed";
CM_ SG_ 1297 RCM_a000_eventSteeringAngle "Restraint control module: a000 event steering angle";
CM_ SG_ 1297 RCM_a000_eventDriverBrakeApply "Restraint control module: a000 event driver brake apply";
CM_ SG_ 1297 RCM_a000_eventAccelPedalPos "Restraint control module: a000 event accel pedal pos";
CM_ SG_ 1297 RCM_a001_eventArmStatus "Restraint control module: a001 event arm status";
CM_ SG_ 1297 RCM_a001_eventFactoryMode "Restraint control module: a001 event factory mode";
CM_ SG_ 1297 RCM_a001_eventDiagEnabled "Restraint control module: a001 event diag enabled";
CM_ SG_ 1297 RCM_a001_eventDriveOrientation "Restraint control module: a001 event drive orientation";
CM_ SG_ 1297 RCM_a001_nearDeployFront "Restraint control module: a001 near deploy front";
CM_ SG_ 1297 RCM_a001_nearDeployRear "Restraint control module: a001 near deploy rear";
CM_ SG_ 1297 RCM_a001_nearDeployLeft "Restraint control module: a001 near deploy left";
CM_ SG_ 1297 RCM_a001_nearDeployRight "Restraint control module: a001 near deploy right";
CM_ SG_ 1297 RCM_a001_nearDeployRoll "Restraint control module: a001 near deploy roll";
CM_ SG_ 1297 RCM_a001_nearDeployPretensioner "Restraint control module: a001 near deploy pretensioner";
CM_ SG_ 1297 RCM_a001_eventIDFsignal "Restraint control module: a001 event ID fsignal";
CM_ SG_ 1297 RCM_a001_eventFrontLeftSeatbelt "Restraint control module: a001 event front left seatbelt";
CM_ SG_ 1297 RCM_a001_eventFrontRightSeatbelt "Restraint control module: a001 event front right seatbelt";
CM_ SG_ 1297 RCM_a001_eventVehicleSpeed "Restraint control module: a001 event vehicle speed";
CM_ SG_ 1297 RCM_a001_eventSteeringAngle "Restraint control module: a001 event steering angle";
CM_ SG_ 1297 RCM_a001_eventDriverBrakeApply "Restraint control module: a001 event driver brake apply; raw 3 = signal not available (SNA)";
CM_ SG_ 1297 RCM_a001_eventAccelPedalPos "Restraint control module: a001 event accel pedal pos; raw 255 = signal not available (SNA)";
CM_ SG_ 1297 RCM_a002_eventArmStatus "Restraint control module: a002 event arm status";
CM_ SG_ 1297 RCM_a002_eventFactoryMode "Restraint control module: a002 event factory mode";
CM_ SG_ 1297 RCM_a002_eventDiagEnabled "Restraint control module: a002 event diag enabled";
CM_ SG_ 1297 RCM_a002_eventDriveOrientation "Restraint control module: a002 event drive orientation";
CM_ SG_ 1297 RCM_a002_airbagsUnArmed "Restraint control module: a002 airbags un armed";
CM_ SG_ 1297 RCM_a002_eventIDFsignal "Restraint control module: a002 event ID fsignal";
CM_ SG_ 1297 RCM_a002_eventFrontLeftSeatbelt "Restraint control module: a002 event front left seatbelt";
CM_ SG_ 1297 RCM_a002_eventFrontRightSeatbelt "Restraint control module: a002 event front right seatbelt";
CM_ SG_ 1297 RCM_a002_eventVehicleSpeed "Restraint control module: a002 event vehicle speed";
CM_ SG_ 1297 RCM_a002_eventSteeringAngle "Restraint control module: a002 event steering angle";
CM_ SG_ 1297 RCM_a002_eventDriverBrakeApply "Restraint control module: a002 event driver brake apply; raw 3 = signal not available (SNA)";
CM_ SG_ 1297 RCM_a002_eventAccelPedalPos "Restraint control module: a002 event accel pedal pos; raw 255 = signal not available (SNA)";
CM_ SG_ 1297 RCM_a003_eventArmStatus "Restraint control module: a003 event arm status";
CM_ SG_ 1297 RCM_a003_eventFactoryMode "Restraint control module: a003 event factory mode";
CM_ SG_ 1297 RCM_a003_eventDiagEnabled "Restraint control module: a003 event diag enabled";
CM_ SG_ 1297 RCM_a003_eventDriveOrientation "Restraint control module: a003 event drive orientation";
CM_ SG_ 1297 RCM_a003_warningIndicatorOn "Restraint control module: a003 warning indicator on";
CM_ SG_ 1297 RCM_a003_eventIDFsignal "Restraint control module: a003 event ID fsignal";
CM_ SG_ 1297 RCM_a003_eventFrontLeftSeatbelt "Restraint control module: a003 event front left seatbelt";
CM_ SG_ 1297 RCM_a003_eventFrontRightSeatbelt "Restraint control module: a003 event front right seatbelt";
CM_ SG_ 1297 RCM_a003_eventVehicleSpeed "Restraint control module: a003 event vehicle speed";
CM_ SG_ 1297 RCM_a003_eventSteeringAngle "Restraint control module: a003 event steering angle";
CM_ SG_ 1297 RCM_a003_eventDriverBrakeApply "Restraint control module: a003 event driver brake apply; raw 3 = signal not available (SNA)";
CM_ SG_ 1297 RCM_a003_eventAccelPedalPos "Restraint control module: a003 event accel pedal pos; raw 255 = signal not available (SNA)";
CM_ SG_ 1297 RCM_a004_eventArmStatus "Restraint control module: a004 event arm status";
CM_ SG_ 1297 RCM_a004_eventFactoryMode "Restraint control module: a004 event factory mode";
CM_ SG_ 1297 RCM_a004_eventDiagEnabled "Restraint control module: a004 event diag enabled";
CM_ SG_ 1297 RCM_a004_eventDriveOrientation "Restraint control module: a004 event drive orientation";
CM_ SG_ 1297 RCM_a004_frontAlgoDisabled "Restraint control module: a004 front algo disabled";
CM_ SG_ 1297 RCM_a004_sideAlgoDisabled "Restraint control module: a004 side algo disabled";
CM_ SG_ 1297 RCM_a004_rollAlgoDisabled "Restraint control module: a004 roll algo disabled";
CM_ SG_ 1297 RCM_a004_idleMode "Restraint control module: a004 idle mode";
CM_ SG_ 1297 RCM_a004_internalFaultDetected "Restraint control module: a004 internal fault detected";
CM_ SG_ 1297 RCM_a004_swVersionMismatch "Restraint control module: a004 sw version mismatch";
CM_ SG_ 1297 RCM_a004_paramLayoutIDInv "Restraint control module: a004 param layout ID inv";
CM_ SG_ 1297 RCM_a004_algoPASIDMismatch "Restraint control module: a004 algo PASID mismatch";
CM_ SG_ 1297 RCM_a004_eventIDFsignal "Restraint control module: a004 event ID fsignal";
CM_ SG_ 1297 RCM_a004_eventFrontLeftSeatbelt "Restraint control module: a004 event front left seatbelt";
CM_ SG_ 1297 RCM_a004_eventFrontRightSeatbelt "Restraint control module: a004 event front right seatbelt";
CM_ SG_ 1297 RCM_a004_eventVehicleSpeed "Restraint control module: a004 event vehicle speed";
CM_ SG_ 1297 RCM_a004_eventSteeringAngle "Restraint control module: a004 event steering angle";
CM_ SG_ 1297 RCM_a004_eventDriverBrakeApply "Restraint control module: a004 event driver brake apply; raw 3 = signal not available (SNA)";
CM_ SG_ 1297 RCM_a004_eventAccelPedalPos "Restraint control module: a004 event accel pedal pos; raw 255 = signal not available (SNA)";
CM_ SG_ 1297 RCM_a005_eventArmStatus "Restraint control module: a005 event arm status";
CM_ SG_ 1297 RCM_a005_eventFactoryMode "Restraint control module: a005 event factory mode";
CM_ SG_ 1297 RCM_a005_eventDiagEnabled "Restraint control module: a005 event diag enabled";
CM_ SG_ 1297 RCM_a005_eventDriveOrientation "Restraint control module: a005 event drive orientation";
CM_ SG_ 1297 RCM_a005_externalCRCError "Restraint control module: a005 external CRC error";
CM_ SG_ 1297 RCM_a005_eventIDFsignal "Restraint control module: a005 event ID fsignal";
CM_ SG_ 1297 RCM_a005_eventFrontLeftSeatbelt "Restraint control module: a005 event front left seatbelt";
CM_ SG_ 1297 RCM_a005_eventFrontRightSeatbelt "Restraint control module: a005 event front right seatbelt";
CM_ SG_ 1297 RCM_a005_eventVehicleSpeed "Restraint control module: a005 event vehicle speed";
CM_ SG_ 1297 RCM_a005_eventSteeringAngle "Restraint control module: a005 event steering angle";
CM_ SG_ 1297 RCM_a005_eventDriverBrakeApply "Restraint control module: a005 event driver brake apply; raw 3 = signal not available (SNA)";
CM_ SG_ 1297 RCM_a005_eventAccelPedalPos "Restraint control module: a005 event accel pedal pos; raw 255 = signal not available (SNA)";
CM_ SG_ 1297 RCM_a006_eventArmStatus "Restraint control module: a006 event arm status";
CM_ SG_ 1297 RCM_a006_eventFactoryMode "Restraint control module: a006 event factory mode";
CM_ SG_ 1297 RCM_a006_eventDiagEnabled "Restraint control module: a006 event diag enabled";
CM_ SG_ 1297 RCM_a006_eventDriveOrientation "Restraint control module: a006 event drive orientation";
CM_ SG_ 1297 RCM_a006_batteryVoltageTooHigh "Restraint control module: a006 battery voltage too high";
CM_ SG_ 1297 RCM_a006_batteryVoltageTooLow "Restraint control module: a006 battery voltage too low";
CM_ SG_ 1297 RCM_a006_eventIDFsignal "Restraint control module: a006 event ID fsignal";
CM_ SG_ 1297 RCM_a006_eventFrontLeftSeatbelt "Restraint control module: a006 event front left seatbelt";
CM_ SG_ 1297 RCM_a006_eventFrontRightSeatbelt "Restraint control module: a006 event front right seatbelt";
CM_ SG_ 1297 RCM_a006_eventVehicleSpeed "Restraint control module: a006 event vehicle speed";
CM_ SG_ 1297 RCM_a006_eventSteeringAngle "Restraint control module: a006 event steering angle";
CM_ SG_ 1297 RCM_a006_eventDriverBrakeApply "Restraint control module: a006 event driver brake apply; raw 3 = signal not available (SNA)";
CM_ SG_ 1297 RCM_a006_eventAccelPedalPos "Restraint control module: a006 event accel pedal pos; raw 255 = signal not available (SNA)";
CM_ SG_ 1297 RCM_a008_eventArmStatus "Restraint control module: a008 event arm status";
CM_ SG_ 1297 RCM_a008_eventFactoryMode "Restraint control module: a008 event factory mode";
CM_ SG_ 1297 RCM_a008_eventDiagEnabled "Restraint control module: a008 event diag enabled";
CM_ SG_ 1297 RCM_a008_eventDriveOrientation "Restraint control module: a008 event drive orientation";
CM_ SG_ 1297 RCM_a008_lossOfMainPwrSupMonit "Restraint control module: a008 loss of main pwr sup monit";
CM_ SG_ 1297 RCM_a008_lossOfBckupPwrSupMonit "Restraint control module: a008 loss of bckup pwr sup monit";
CM_ SG_ 1297 RCM_a008_normalShtdwnUnavail "Restraint control module: a008 normal shtdwn unavail";
CM_ SG_ 1297 RCM_a008_eventIDFsignal "Restraint control module: a008 event ID fsignal";
CM_ SG_ 1297 RCM_a008_eventFrontLeftSeatbelt "Restraint control module: a008 event front left seatbelt";
CM_ SG_ 1297 RCM_a008_eventFrontRightSeatbelt "Restraint control module: a008 event front right seatbelt";
CM_ SG_ 1297 RCM_a008_eventVehicleSpeed "Restraint control module: a008 event vehicle speed";
CM_ SG_ 1297 RCM_a008_eventSteeringAngle "Restraint control module: a008 event steering angle";
CM_ SG_ 1297 RCM_a008_eventDriverBrakeApply "Restraint control module: a008 event driver brake apply; raw 3 = signal not available (SNA)";
CM_ SG_ 1297 RCM_a008_eventAccelPedalPos "Restraint control module: a008 event accel pedal pos; raw 255 = signal not available (SNA)";
CM_ SG_ 1297 RCM_a009_eventArmStatus "Restraint control module: a009 event arm status";
CM_ SG_ 1297 RCM_a009_eventFactoryMode "Restraint control module: a009 event factory mode";
CM_ SG_ 1297 RCM_a009_eventDiagEnabled "Restraint control module: a009 event diag enabled";
CM_ SG_ 1297 RCM_a009_eventDriveOrientation "Restraint control module: a009 event drive orientation";
CM_ SG_ 1297 RCM_a009_reprogramLimitExceeded "Restraint control module: a009 reprogram limit exceeded";
CM_ SG_ 1297 RCM_a009_eventIDFsignal "Restraint control module: a009 event ID fsignal";
CM_ SG_ 1297 RCM_a009_eventFrontLeftSeatbelt "Restraint control module: a009 event front left seatbelt";
CM_ SG_ 1297 RCM_a009_eventFrontRightSeatbelt "Restraint control module: a009 event front right seatbelt";
CM_ SG_ 1297 RCM_a009_eventVehicleSpeed "Restraint control module: a009 event vehicle speed";
CM_ SG_ 1297 RCM_a009_eventSteeringAngle "Restraint control module: a009 event steering angle";
CM_ SG_ 1297 RCM_a009_eventDriverBrakeApply "Restraint control module: a009 event driver brake apply; raw 3 = signal not available (SNA)";
CM_ SG_ 1297 RCM_a009_eventAccelPedalPos "Restraint control module: a009 event accel pedal pos; raw 255 = signal not available (SNA)";
CM_ SG_ 1297 RCM_a011_eventArmStatus "Restraint control module: a011 event arm status";
CM_ SG_ 1297 RCM_a011_eventFactoryMode "Restraint control module: a011 event factory mode";
CM_ SG_ 1297 RCM_a011_eventDiagEnabled "Restraint control module: a011 event diag enabled";
CM_ SG_ 1297 RCM_a011_eventDriveOrientation "Restraint control module: a011 event drive orientation";
CM_ SG_ 1297 RCM_a011_edrDataAreaLocked "Restraint control module: a011 edr data area locked";
CM_ SG_ 1297 RCM_a011_eventIDFsignal "Restraint control module: a011 event ID fsignal";
CM_ SG_ 1297 RCM_a011_eventFrontLeftSeatbelt "Restraint control module: a011 event front left seatbelt";
CM_ SG_ 1297 RCM_a011_eventFrontRightSeatbelt "Restraint control module: a011 event front right seatbelt";
CM_ SG_ 1297 RCM_a011_eventVehicleSpeed "Restraint control module: a011 event vehicle speed";
CM_ SG_ 1297 RCM_a011_eventSteeringAngle "Restraint control module: a011 event steering angle";
CM_ SG_ 1297 RCM_a011_eventDriverBrakeApply "Restraint control module: a011 event driver brake apply; raw 3 = signal not available (SNA)";
CM_ SG_ 1297 RCM_a011_eventAccelPedalPos "Restraint control module: a011 event accel pedal pos; raw 255 = signal not available (SNA)";
CM_ SG_ 1297 RCM_a012_eventArmStatus "Restraint control module: a012 event arm status";
CM_ SG_ 1297 RCM_a012_eventFactoryMode "Restraint control module: a012 event factory mode";
CM_ SG_ 1297 RCM_a012_eventDiagEnabled "Restraint control module: a012 event diag enabled";
CM_ SG_ 1297 RCM_a012_eventDriveOrientation "Restraint control module: a012 event drive orientation";
CM_ SG_ 1297 RCM_a012_vinMismatch "Restraint control module: a012 vin mismatch";
CM_ SG_ 1297 RCM_a012_vinNotProgrammed "Restraint control module: a012 vin not programmed";
CM_ SG_ 1297 RCM_a012_eventIDFsignal "Restraint control module: a012 event ID fsignal";
CM_ SG_ 1297 RCM_a012_eventFrontLeftSeatbelt "Restraint control module: a012 event front left seatbelt";
CM_ SG_ 1297 RCM_a012_eventFrontRightSeatbelt "Restraint control module: a012 event front right seatbelt";
CM_ SG_ 1297 RCM_a012_eventVehicleSpeed "Restraint control module: a012 event vehicle speed";
CM_ SG_ 1297 RCM_a012_eventSteeringAngle "Restraint control module: a012 event steering angle";
CM_ SG_ 1297 RCM_a012_eventDriverBrakeApply "Restraint control module: a012 event driver brake apply; raw 3 = signal not available (SNA)";
CM_ SG_ 1297 RCM_a012_eventAccelPedalPos "Restraint control module: a012 event accel pedal pos; raw 255 = signal not available (SNA)";
CM_ SG_ 1297 RCM_a013_eventArmStatus "Restraint control module: a013 event arm status";
CM_ SG_ 1297 RCM_a013_eventFactoryMode "Restraint control module: a013 event factory mode";
CM_ SG_ 1297 RCM_a013_eventDiagEnabled "Restraint control module: a013 event diag enabled";
CM_ SG_ 1297 RCM_a013_eventDriveOrientation "Restraint control module: a013 event drive orientation";
CM_ SG_ 1297 RCM_a013_driveOrientiInitNotDone "Restraint control module: a013 drive orienti init not done";
CM_ SG_ 1297 RCM_a013_driveOrientPlausiCheck "Restraint control module: a013 drive orient plausi check";
CM_ SG_ 1297 RCM_a013_eventIDFsignal "Restraint control module: a013 event ID fsignal";
CM_ SG_ 1297 RCM_a013_eventFrontLeftSeatbelt "Restraint control module: a013 event front left seatbelt";
CM_ SG_ 1297 RCM_a013_eventFrontRightSeatbelt "Restraint control module: a013 event front right seatbelt";
CM_ SG_ 1297 RCM_a013_eventVehicleSpeed "Restraint control module: a013 event vehicle speed";
CM_ SG_ 1297 RCM_a013_eventSteeringAngle "Restraint control module: a013 event steering angle";
CM_ SG_ 1297 RCM_a013_eventDriverBrakeApply "Restraint control module: a013 event driver brake apply; raw 3 = signal not available (SNA)";
CM_ SG_ 1297 RCM_a013_eventAccelPedalPos "Restraint control module: a013 event accel pedal pos; raw 255 = signal not available (SNA)";
CM_ SG_ 1297 RCM_a014_eventArmStatus "Restraint control module: a014 event arm status";
CM_ SG_ 1297 RCM_a014_eventFactoryMode "Restraint control module: a014 event factory mode";
CM_ SG_ 1297 RCM_a014_eventDiagEnabled "Restraint control module: a014 event diag enabled";
CM_ SG_ 1297 RCM_a014_eventDriveOrientation "Restraint control module: a014 event drive orientation";
CM_ SG_ 1297 RCM_a014_driverABStg1Sht2Gnd "Restraint control module: a014 driver AB stg1 sht2 gnd";
CM_ SG_ 1297 RCM_a014_driverABStg1Sht2Bat "Restraint control module: a014 driver AB stg1 sht2 bat";
CM_ SG_ 1297 RCM_a014_driverABStg1Open "Restraint control module: a014 driver AB stg1 open";
CM_ SG_ 1297 RCM_a014_driverABStg1Short "Restraint control module: a014 driver AB stg1 short";
CM_ SG_ 1297 RCM_a014_driverABStg1CrossCoup "Restraint control module: a014 driver AB stg1 cross coup";
CM_ SG_ 1297 RCM_a014_driverABStg1Config "Restraint control module: a014 driver AB stg1 config";
CM_ SG_ 1297 RCM_a014_eventIDFsignal "Restraint control module: a014 event ID fsignal";
CM_ SG_ 1297 RCM_a014_eventFrontLeftSeatbelt "Restraint control module: a014 event front left seatbelt";
CM_ SG_ 1297 RCM_a014_eventFrontRightSeatbelt "Restraint control module: a014 event front right seatbelt";
CM_ SG_ 1297 RCM_a014_eventVehicleSpeed "Restraint control module: a014 event vehicle speed";
CM_ SG_ 1297 RCM_a014_eventSteeringAngle "Restraint control module: a014 event steering angle";
CM_ SG_ 1297 RCM_a014_eventDriverBrakeApply "Restraint control module: a014 event driver brake apply; raw 3 = signal not available (SNA)";
CM_ SG_ 1297 RCM_a014_eventAccelPedalPos "Restraint control module: a014 event accel pedal pos; raw 255 = signal not available (SNA)";
CM_ SG_ 1297 RCM_a015_eventArmStatus "Restraint control module: a015 event arm status";
CM_ SG_ 1297 RCM_a015_eventFactoryMode "Restraint control module: a015 event factory mode";
CM_ SG_ 1297 RCM_a015_eventDiagEnabled "Restraint control module: a015 event diag enabled";
CM_ SG_ 1297 RCM_a015_eventDriveOrientation "Restraint control module: a015 event drive orientation";
CM_ SG_ 1297 RCM_a015_driverABStg2Sht2Gnd "Restraint control module: a015 driver AB stg2 sht2 gnd";
CM_ SG_ 1297 RCM_a015_driverABStg2Sht2Bat "Restraint control module: a015 driver AB stg2 sht2 bat";
CM_ SG_ 1297 RCM_a015_driverABStg2Open "Restraint control module: a015 driver AB stg2 open";
CM_ SG_ 1297 RCM_a015_driverABStg2Short "Restraint control module: a015 driver AB stg2 short";
CM_ SG_ 1297 RCM_a015_driverABStg2CrossCoup "Restraint control module: a015 driver AB stg2 cross coup";
CM_ SG_ 1297 RCM_a015_driverABStg2Config "Restraint control module: a015 driver AB stg2 config";
CM_ SG_ 1297 RCM_a015_eventIDFsignal "Restraint control module: a015 event ID fsignal";
CM_ SG_ 1297 RCM_a015_eventFrontLeftSeatbelt "Restraint control module: a015 event front left seatbelt";
CM_ SG_ 1297 RCM_a015_eventFrontRightSeatbelt "Restraint control module: a015 event front right seatbelt";
CM_ SG_ 1297 RCM_a015_eventVehicleSpeed "Restraint control module: a015 event vehicle speed";
CM_ SG_ 1297 RCM_a015_eventSteeringAngle "Restraint control module: a015 event steering angle";
CM_ SG_ 1297 RCM_a015_eventDriverBrakeApply "Restraint control module: a015 event driver brake apply; raw 3 = signal not available (SNA)";
CM_ SG_ 1297 RCM_a015_eventAccelPedalPos "Restraint control module: a015 event accel pedal pos; raw 255 = signal not available (SNA)";
CM_ SG_ 1297 RCM_a016_eventArmStatus "Restraint control module: a016 event arm status";
CM_ SG_ 1297 RCM_a016_eventFactoryMode "Restraint control module: a016 event factory mode";
CM_ SG_ 1297 RCM_a016_eventDiagEnabled "Restraint control module: a016 event diag enabled";
CM_ SG_ 1297 RCM_a016_eventDriveOrientation "Restraint control module: a016 event drive orientation";
CM_ SG_ 1297 RCM_a016_passABStg1Sht2Gnd "Restraint control module: a016 pass AB stg1 sht2 gnd";
CM_ SG_ 1297 RCM_a016_passABStg1Sht2Bat "Restraint control module: a016 pass AB stg1 sht2 bat";
CM_ SG_ 1297 RCM_a016_passABStg1Open "Restraint control module: a016 pass AB stg1 open";
CM_ SG_ 1297 RCM_a016_passABStg1Short "Restraint control module: a016 pass AB stg1 short";
CM_ SG_ 1297 RCM_a016_passABStg1CrossCoup "Restraint control module: a016 pass AB stg1 cross coup";
CM_ SG_ 1297 RCM_a016_passABStg1Config "Restraint control module: a016 pass AB stg1 config";
CM_ SG_ 1297 RCM_a016_eventIDFsignal "Restraint control module: a016 event ID fsignal";
CM_ SG_ 1297 RCM_a016_eventFrontLeftSeatbelt "Restraint control module: a016 event front left seatbelt";
CM_ SG_ 1297 RCM_a016_eventFrontRightSeatbelt "Restraint control module: a016 event front right seatbelt";
CM_ SG_ 1297 RCM_a016_eventVehicleSpeed "Restraint control module: a016 event vehicle speed";
CM_ SG_ 1297 RCM_a016_eventSteeringAngle "Restraint control module: a016 event steering angle";
CM_ SG_ 1297 RCM_a016_eventDriverBrakeApply "Restraint control module: a016 event driver brake apply; raw 3 = signal not available (SNA)";
CM_ SG_ 1297 RCM_a016_eventAccelPedalPos "Restraint control module: a016 event accel pedal pos; raw 255 = signal not available (SNA)";
CM_ SG_ 1297 RCM_a017_eventArmStatus "Restraint control module: a017 event arm status";
CM_ SG_ 1297 RCM_a017_eventFactoryMode "Restraint control module: a017 event factory mode";
CM_ SG_ 1297 RCM_a017_eventDiagEnabled "Restraint control module: a017 event diag enabled";
CM_ SG_ 1297 RCM_a017_eventDriveOrientation "Restraint control module: a017 event drive orientation";
CM_ SG_ 1297 RCM_a017_passABStg2Sht2Gnd "Restraint control module: a017 pass AB stg2 sht2 gnd";
CM_ SG_ 1297 RCM_a017_passABStg2Sht2Bat "Restraint control module: a017 pass AB stg2 sht2 bat";
CM_ SG_ 1297 RCM_a017_passABStg2Open "Restraint control module: a017 pass AB stg2 open";
CM_ SG_ 1297 RCM_a017_passABStg2Short "Restraint control module: a017 pass AB stg2 short";
CM_ SG_ 1297 RCM_a017_passABStg2CrossCoup "Restraint control module: a017 pass AB stg2 cross coup";
CM_ SG_ 1297 RCM_a017_passABStg2Config "Restraint control module: a017 pass AB stg2 config";
CM_ SG_ 1297 RCM_a017_eventIDFsignal "Restraint control module: a017 event ID fsignal";
CM_ SG_ 1297 RCM_a017_eventFrontLeftSeatbelt "Restraint control module: a017 event front left seatbelt";
CM_ SG_ 1297 RCM_a017_eventFrontRightSeatbelt "Restraint control module: a017 event front right seatbelt";
CM_ SG_ 1297 RCM_a017_eventVehicleSpeed "Restraint control module: a017 event vehicle speed";
CM_ SG_ 1297 RCM_a017_eventSteeringAngle "Restraint control module: a017 event steering angle";
CM_ SG_ 1297 RCM_a017_eventDriverBrakeApply "Restraint control module: a017 event driver brake apply; raw 3 = signal not available (SNA)";
CM_ SG_ 1297 RCM_a017_eventAccelPedalPos "Restraint control module: a017 event accel pedal pos; raw 255 = signal not available (SNA)";
CM_ SG_ 1297 RCM_a018_eventArmStatus "Restraint control module: a018 event arm status";
CM_ SG_ 1297 RCM_a018_eventFactoryMode "Restraint control module: a018 event factory mode";
CM_ SG_ 1297 RCM_a018_eventDiagEnabled "Restraint control module: a018 event diag enabled";
CM_ SG_ 1297 RCM_a018_eventDriveOrientation "Restraint control module: a018 event drive orientation";
CM_ SG_ 1297 RCM_a018_passActiveVentSht2Gnd "Restraint control module: a018 pass active vent sht2 gnd";
CM_ SG_ 1297 RCM_a018_passActiveVentSht2Bat "Restraint control module: a018 pass active vent sht2 bat";
CM_ SG_ 1297 RCM_a018_passActiveVentOpen "Restraint control module: a018 pass active vent open";
CM_ SG_ 1297 RCM_a018_passActiveVentShort "Restraint control module: a018 pass active vent short";
CM_ SG_ 1297 RCM_a018_passActiveVentCrossCoup "Restraint control module: a018 pass active vent cross coup";
CM_ SG_ 1297 RCM_a018_passActiveVentConfig "Restraint control module: a018 pass active vent config";
CM_ SG_ 1297 RCM_a018_eventIDFsignal "Restraint control module: a018 event ID fsignal";
CM_ SG_ 1297 RCM_a018_eventFrontLeftSeatbelt "Restraint control module: a018 event front left seatbelt";
CM_ SG_ 1297 RCM_a018_eventFrontRightSeatbelt "Restraint control module: a018 event front right seatbelt";
CM_ SG_ 1297 RCM_a018_eventVehicleSpeed "Restraint control module: a018 event vehicle speed";
CM_ SG_ 1297 RCM_a018_eventSteeringAngle "Restraint control module: a018 event steering angle";
CM_ SG_ 1297 RCM_a018_eventDriverBrakeApply "Restraint control module: a018 event driver brake apply; raw 3 = signal not available (SNA)";
CM_ SG_ 1297 RCM_a018_eventAccelPedalPos "Restraint control module: a018 event accel pedal pos; raw 255 = signal not available (SNA)";
CM_ SG_ 1297 RCM_a019_eventArmStatus "Restraint control module: a019 event arm status";
CM_ SG_ 1297 RCM_a019_eventFactoryMode "Restraint control module: a019 event factory mode";
CM_ SG_ 1297 RCM_a019_eventDiagEnabled "Restraint control module: a019 event diag enabled";
CM_ SG_ 1297 RCM_a019_eventDriveOrientation "Restraint control module: a019 event drive orientation";
CM_ SG_ 1297 RCM_a019_pretenShldLeftSht2Gnd "Restraint control module: a019 preten shld left sht2 gnd";
CM_ SG_ 1297 RCM_a019_pretenShldLeftSht2Bat "Restraint control module: a019 preten shld left sht2 bat";
CM_ SG_ 1297 RCM_a019_pretenShldLeftOpen "Restraint control module: a019 preten shld left open";
CM_ SG_ 1297 RCM_a019_pretenShldLeftShort "Restraint control module: a019 preten shld left short";
CM_ SG_ 1297 RCM_a019_pretenShldLeftCrossC "Restraint control module: a019 preten shld left cross c";
CM_ SG_ 1297 RCM_a019_pretenShldLeftConfig "Restraint control module: a019 preten shld left config";
CM_ SG_ 1297 RCM_a019_eventIDFsignal "Restraint control module: a019 event ID fsignal";
CM_ SG_ 1297 RCM_a019_eventFrontLeftSeatbelt "Restraint control module: a019 event front left seatbelt";
CM_ SG_ 1297 RCM_a019_eventFrontRightSeatbelt "Restraint control module: a019 event front right seatbelt";
CM_ SG_ 1297 RCM_a019_eventVehicleSpeed "Restraint control module: a019 event vehicle speed";
CM_ SG_ 1297 RCM_a019_eventSteeringAngle "Restraint control module: a019 event steering angle";
CM_ SG_ 1297 RCM_a019_eventDriverBrakeApply "Restraint control module: a019 event driver brake apply; raw 3 = signal not available (SNA)";
CM_ SG_ 1297 RCM_a019_eventAccelPedalPos "Restraint control module: a019 event accel pedal pos; raw 255 = signal not available (SNA)";
CM_ SG_ 1297 RCM_a020_eventArmStatus "Restraint control module: a020 event arm status";
CM_ SG_ 1297 RCM_a020_eventFactoryMode "Restraint control module: a020 event factory mode";
CM_ SG_ 1297 RCM_a020_eventDiagEnabled "Restraint control module: a020 event diag enabled";
CM_ SG_ 1297 RCM_a020_eventDriveOrientation "Restraint control module: a020 event drive orientation";
CM_ SG_ 1297 RCM_a020_pretenShldRightSht2Gnd "Restraint control module: a020 preten shld right sht2 gnd";
CM_ SG_ 1297 RCM_a020_pretenShldRightSht2Bat "Restraint control module: a020 preten shld right sht2 bat";
CM_ SG_ 1297 RCM_a020_pretenShldRightOpen "Restraint control module: a020 preten shld right open";
CM_ SG_ 1297 RCM_a020_pretenShldRightShort "Restraint control module: a020 preten shld right short";
CM_ SG_ 1297 RCM_a020_pretenShldRightCrossC "Restraint control module: a020 preten shld right cross c";
CM_ SG_ 1297 RCM_a020_pretenShldRightConfig "Restraint control module: a020 preten shld right config";
CM_ SG_ 1297 RCM_a020_eventIDFsignal "Restraint control module: a020 event ID fsignal";
CM_ SG_ 1297 RCM_a020_eventFrontLeftSeatbelt "Restraint control module: a020 event front left seatbelt";
CM_ SG_ 1297 RCM_a020_eventFrontRightSeatbelt "Restraint control module: a020 event front right seatbelt";
CM_ SG_ 1297 RCM_a020_eventVehicleSpeed "Restraint control module: a020 event vehicle speed";
CM_ SG_ 1297 RCM_a020_eventSteeringAngle "Restraint control module: a020 event steering angle";
CM_ SG_ 1297 RCM_a020_eventDriverBrakeApply "Restraint control module: a020 event driver brake apply; raw 3 = signal not available (SNA)";
CM_ SG_ 1297 RCM_a020_eventAccelPedalPos "Restraint control module: a020 event accel pedal pos; raw 255 = signal not available (SNA)";
CM_ SG_ 1297 RCM_a021_eventArmStatus "Restraint control module: a021 event arm status";
CM_ SG_ 1297 RCM_a021_eventFactoryMode "Restraint control module: a021 event factory mode";
CM_ SG_ 1297 RCM_a021_eventDiagEnabled "Restraint control module: a021 event diag enabled";
CM_ SG_ 1297 RCM_a021_eventDriveOrientation "Restraint control module: a021 event drive orientation";
CM_ SG_ 1297 RCM_a021_pretenLapLeftSht2Gnd "Restraint control module: a021 preten lap left sht2 gnd";
CM_ SG_ 1297 RCM_a021_pretenLapLeftSht2Bat "Restraint control module: a021 preten lap left sht2 bat";
CM_ SG_ 1297 RCM_a021_pretenLapLeftOpen "Restraint control module: a021 preten lap left open";
CM_ SG_ 1297 RCM_a021_pretenLapLeftShort "Restraint control module: a021 preten lap left short";
CM_ SG_ 1297 RCM_a021_pretenLapLeftCrossCoup "Restraint control module: a021 preten lap left cross coup";
CM_ SG_ 1297 RCM_a021_pretenLapLeftConfig "Restraint control module: a021 preten lap left config";
CM_ SG_ 1297 RCM_a021_eventIDFsignal "Restraint control module: a021 event ID fsignal";
CM_ SG_ 1297 RCM_a021_eventFrontLeftSeatbelt "Restraint control module: a021 event front left seatbelt";
CM_ SG_ 1297 RCM_a021_eventFrontRightSeatbelt "Restraint control module: a021 event front right seatbelt";
CM_ SG_ 1297 RCM_a021_eventVehicleSpeed "Restraint control module: a021 event vehicle speed";
CM_ SG_ 1297 RCM_a021_eventSteeringAngle "Restraint control module: a021 event steering angle";
CM_ SG_ 1297 RCM_a021_eventDriverBrakeApply "Restraint control module: a021 event driver brake apply; raw 3 = signal not available (SNA)";
CM_ SG_ 1297 RCM_a021_eventAccelPedalPos "Restraint control module: a021 event accel pedal pos; raw 255 = signal not available (SNA)";
CM_ SG_ 1297 RCM_a022_eventArmStatus "Restraint control module: a022 event arm status";
CM_ SG_ 1297 RCM_a022_eventFactoryMode "Restraint control module: a022 event factory mode";
CM_ SG_ 1297 RCM_a022_eventDiagEnabled "Restraint control module: a022 event diag enabled";
CM_ SG_ 1297 RCM_a022_eventDriveOrientation "Restraint control module: a022 event drive orientation";
CM_ SG_ 1297 RCM_a022_pretenLapRightSht2Gnd "Restraint control module: a022 preten lap right sht2 gnd";
CM_ SG_ 1297 RCM_a022_pretenLapRightSht2Bat "Restraint control module: a022 preten lap right sht2 bat";
CM_ SG_ 1297 RCM_a022_pretenLapRightOpen "Restraint control module: a022 preten lap right open";
CM_ SG_ 1297 RCM_a022_pretenLapRightShort "Restraint control module: a022 preten lap right short";
CM_ SG_ 1297 RCM_a022_pretenLapRightCrossCoup "Restraint control module: a022 preten lap right cross coup";
CM_ SG_ 1297 RCM_a022_pretenLapRightConfig "Restraint control module: a022 preten lap right config";
CM_ SG_ 1297 RCM_a022_eventIDFsignal "Restraint control module: a022 event ID fsignal";
CM_ SG_ 1297 RCM_a022_eventFrontLeftSeatbelt "Restraint control module: a022 event front left seatbelt";
CM_ SG_ 1297 RCM_a022_eventFrontRightSeatbelt "Restraint control module: a022 event front right seatbelt";
CM_ SG_ 1297 RCM_a022_eventVehicleSpeed "Restraint control module: a022 event vehicle speed";
CM_ SG_ 1297 RCM_a022_eventSteeringAngle "Restraint control module: a022 event steering angle";
CM_ SG_ 1297 RCM_a022_eventDriverBrakeApply "Restraint control module: a022 event driver brake apply; raw 3 = signal not available (SNA)";
CM_ SG_ 1297 RCM_a022_eventAccelPedalPos "Restraint control module: a022 event accel pedal pos; raw 255 = signal not available (SNA)";
CM_ SG_ 1297 RCM_a023_eventArmStatus "Restraint control module: a023 event arm status";
CM_ SG_ 1297 RCM_a023_eventFactoryMode "Restraint control module: a023 event factory mode";
CM_ SG_ 1297 RCM_a023_eventDiagEnabled "Restraint control module: a023 event diag enabled";
CM_ SG_ 1297 RCM_a023_eventDriveOrientation "Restraint control module: a023 event drive orientation";
CM_ SG_ 1297 RCM_a023_loadLimLeftSht2Gnd "Restraint control module: a023 load lim left sht2 gnd";
CM_ SG_ 1297 RCM_a023_loadLimLeftSht2Bat "Restraint control module: a023 load lim left sht2 bat";
CM_ SG_ 1297 RCM_a023_loadLimLeftOpen "Restraint control module: a023 load lim left open";
CM_ SG_ 1297 RCM_a023_loadLimLeftShort "Restraint control module: a023 load lim left short";
CM_ SG_ 1297 RCM_a023_loadLimLeftCrossCoup "Restraint control module: a023 load lim left cross coup";
CM_ SG_ 1297 RCM_a023_loadLimLeftConfig "Restraint control module: a023 load lim left config";
CM_ SG_ 1297 RCM_a023_eventIDFsignal "Restraint control module: a023 event ID fsignal";
CM_ SG_ 1297 RCM_a023_eventFrontLeftSeatbelt "Restraint control module: a023 event front left seatbelt";
CM_ SG_ 1297 RCM_a023_eventFrontRightSeatbelt "Restraint control module: a023 event front right seatbelt";
CM_ SG_ 1297 RCM_a023_eventVehicleSpeed "Restraint control module: a023 event vehicle speed";
CM_ SG_ 1297 RCM_a023_eventSteeringAngle "Restraint control module: a023 event steering angle";
CM_ SG_ 1297 RCM_a023_eventDriverBrakeApply "Restraint control module: a023 event driver brake apply; raw 3 = signal not available (SNA)";
CM_ SG_ 1297 RCM_a023_eventAccelPedalPos "Restraint control module: a023 event accel pedal pos; raw 255 = signal not available (SNA)";
CM_ SG_ 1297 RCM_a024_eventArmStatus "Restraint control module: a024 event arm status";
CM_ SG_ 1297 RCM_a024_eventFactoryMode "Restraint control module: a024 event factory mode";
CM_ SG_ 1297 RCM_a024_eventDiagEnabled "Restraint control module: a024 event diag enabled";
CM_ SG_ 1297 RCM_a024_eventDriveOrientation "Restraint control module: a024 event drive orientation";
CM_ SG_ 1297 RCM_a024_loadLimRightSht2Gnd "Restraint control module: a024 load lim right sht2 gnd";
CM_ SG_ 1297 RCM_a024_loadLimRightSht2Bat "Restraint control module: a024 load lim right sht2 bat";
CM_ SG_ 1297 RCM_a024_loadLimRightOpen "Restraint control module: a024 load lim right open";
CM_ SG_ 1297 RCM_a024_loadLimRightShort "Restraint control module: a024 load lim right short";
CM_ SG_ 1297 RCM_a024_loadLimRightCrossCoup "Restraint control module: a024 load lim right cross coup";
CM_ SG_ 1297 RCM_a024_loadLimRightConfig "Restraint control module: a024 load lim right config";
CM_ SG_ 1297 RCM_a024_eventIDFsignal "Restraint control module: a024 event ID fsignal";
CM_ SG_ 1297 RCM_a024_eventFrontLeftSeatbelt "Restraint control module: a024 event front left seatbelt";
CM_ SG_ 1297 RCM_a024_eventFrontRightSeatbelt "Restraint control module: a024 event front right seatbelt";
CM_ SG_ 1297 RCM_a024_eventVehicleSpeed "Restraint control module: a024 event vehicle speed";
CM_ SG_ 1297 RCM_a024_eventSteeringAngle "Restraint control module: a024 event steering angle";
CM_ SG_ 1297 RCM_a024_eventDriverBrakeApply "Restraint control module: a024 event driver brake apply; raw 3 = signal not available (SNA)";
CM_ SG_ 1297 RCM_a024_eventAccelPedalPos "Restraint control module: a024 event accel pedal pos; raw 255 = signal not available (SNA)";
CM_ SG_ 1297 RCM_a025_eventArmStatus "Restraint control module: a025 event arm status";
CM_ SG_ 1297 RCM_a025_eventFactoryMode "Restraint control module: a025 event factory mode";
CM_ SG_ 1297 RCM_a025_eventDiagEnabled "Restraint control module: a025 event diag enabled";
CM_ SG_ 1297 RCM_a025_eventDriveOrientation "Restraint control module: a025 event drive orientation";
CM_ SG_ 1297 RCM_a025_kneeABDrvrSht2Gnd "Restraint control module: a025 knee AB drvr sht2 gnd";
CM_ SG_ 1297 RCM_a025_kneeABDrvrSht2Bat "Restraint control module: a025 knee AB drvr sht2 bat";
CM_ SG_ 1297 RCM_a025_kneeABDrvrOpen "Restraint control module: a025 knee AB drvr open";
CM_ SG_ 1297 RCM_a025_kneeABDrvrShort "Restraint control module: a025 knee AB drvr short";
CM_ SG_ 1297 RCM_a025_kneeABDrvrCrossCoup "Restraint control module: a025 knee AB drvr cross coup";
CM_ SG_ 1297 RCM_a025_kneeABDrvrConfig "Restraint control module: a025 knee AB drvr config";
CM_ SG_ 1297 RCM_a025_eventIDFsignal "Restraint control module: a025 event ID fsignal";
CM_ SG_ 1297 RCM_a025_eventFrontLeftSeatbelt "Restraint control module: a025 event front left seatbelt";
CM_ SG_ 1297 RCM_a025_eventFrontRightSeatbelt "Restraint control module: a025 event front right seatbelt";
CM_ SG_ 1297 RCM_a025_eventVehicleSpeed "Restraint control module: a025 event vehicle speed";
CM_ SG_ 1297 RCM_a025_eventSteeringAngle "Restraint control module: a025 event steering angle";
CM_ SG_ 1297 RCM_a025_eventDriverBrakeApply "Restraint control module: a025 event driver brake apply; raw 3 = signal not available (SNA)";
CM_ SG_ 1297 RCM_a025_eventAccelPedalPos "Restraint control module: a025 event accel pedal pos; raw 255 = signal not available (SNA)";
CM_ SG_ 1297 RCM_a026_eventArmStatus "Restraint control module: a026 event arm status";
CM_ SG_ 1297 RCM_a026_eventFactoryMode "Restraint control module: a026 event factory mode";
CM_ SG_ 1297 RCM_a026_eventDiagEnabled "Restraint control module: a026 event diag enabled";
CM_ SG_ 1297 RCM_a026_eventDriveOrientation "Restraint control module: a026 event drive orientation";
CM_ SG_ 1297 RCM_a026_kneeABPassSht2Gnd "Restraint control module: a026 knee AB pass sht2 gnd";
CM_ SG_ 1297 RCM_a026_kneeABPassSht2Bat "Restraint control module: a026 knee AB pass sht2 bat";
CM_ SG_ 1297 RCM_a026_kneeABPassOpen "Restraint control module: a026 knee AB pass open";
CM_ SG_ 1297 RCM_a026_kneeABPassShort "Restraint control module: a026 knee AB pass short";
CM_ SG_ 1297 RCM_a026_kneeABPassCrossCoup "Restraint control module: a026 knee AB pass cross coup";
CM_ SG_ 1297 RCM_a026_kneeABPassConfig "Restraint control module: a026 knee AB pass config";
CM_ SG_ 1297 RCM_a026_eventIDFsignal "Restraint control module: a026 event ID fsignal";
CM_ SG_ 1297 RCM_a026_eventFrontLeftSeatbelt "Restraint control module: a026 event front left seatbelt";
CM_ SG_ 1297 RCM_a026_eventFrontRightSeatbelt "Restraint control module: a026 event front right seatbelt";
CM_ SG_ 1297 RCM_a026_eventVehicleSpeed "Restraint control module: a026 event vehicle speed";
CM_ SG_ 1297 RCM_a026_eventSteeringAngle "Restraint control module: a026 event steering angle";
CM_ SG_ 1297 RCM_a026_eventDriverBrakeApply "Restraint control module: a026 event driver brake apply; raw 3 = signal not available (SNA)";
CM_ SG_ 1297 RCM_a026_eventAccelPedalPos "Restraint control module: a026 event accel pedal pos; raw 255 = signal not available (SNA)";
CM_ SG_ 1297 RCM_a027_eventArmStatus "Restraint control module: a027 event arm status";
CM_ SG_ 1297 RCM_a027_eventFactoryMode "Restraint control module: a027 event factory mode";
CM_ SG_ 1297 RCM_a027_eventDiagEnabled "Restraint control module: a027 event diag enabled";
CM_ SG_ 1297 RCM_a027_eventDriveOrientation "Restraint control module: a027 event drive orientation";
CM_ SG_ 1297 RCM_a027_sideAB1stRowLSht2Gnd "Restraint control module: a027 side ab1st row l sht2 gnd";
CM_ SG_ 1297 RCM_a027_sideAB1stRowLSht2Bat "Restraint control module: a027 side ab1st row l sht2 bat";
CM_ SG_ 1297 RCM_a027_sideAB1stRowLOpen "Restraint control module: a027 side ab1st row l open";
CM_ SG_ 1297 RCM_a027_sideAB1stRowLShort "Restraint control module: a027 side ab1st row l short";
CM_ SG_ 1297 RCM_a027_sideAB1stRowLCrossCoup "Restraint control module: a027 side ab1st row l cross coup";
CM_ SG_ 1297 RCM_a027_sideAB1stRowLConfig "Restraint control module: a027 side ab1st row l config";
CM_ SG_ 1297 RCM_a027_eventIDFsignal "Restraint control module: a027 event ID fsignal";
CM_ SG_ 1297 RCM_a027_eventFrontLeftSeatbelt "Restraint control module: a027 event front left seatbelt";
CM_ SG_ 1297 RCM_a027_eventFrontRightSeatbelt "Restraint control module: a027 event front right seatbelt";
CM_ SG_ 1297 RCM_a027_eventVehicleSpeed "Restraint control module: a027 event vehicle speed";
CM_ SG_ 1297 RCM_a027_eventSteeringAngle "Restraint control module: a027 event steering angle";
CM_ SG_ 1297 RCM_a027_eventDriverBrakeApply "Restraint control module: a027 event driver brake apply; raw 3 = signal not available (SNA)";
CM_ SG_ 1297 RCM_a027_eventAccelPedalPos "Restraint control module: a027 event accel pedal pos; raw 255 = signal not available (SNA)";
CM_ SG_ 1297 RCM_a028_eventArmStatus "Restraint control module: a028 event arm status";
CM_ SG_ 1297 RCM_a028_eventFactoryMode "Restraint control module: a028 event factory mode";
CM_ SG_ 1297 RCM_a028_eventDiagEnabled "Restraint control module: a028 event diag enabled";
CM_ SG_ 1297 RCM_a028_eventDriveOrientation "Restraint control module: a028 event drive orientation";
CM_ SG_ 1297 RCM_a028_sideAB1stRowRSht2Gnd "Restraint control module: a028 side ab1st row r sht2 gnd";
CM_ SG_ 1297 RCM_a028_sideAB1stRowRSht2Bat "Restraint control module: a028 side ab1st row r sht2 bat";
CM_ SG_ 1297 RCM_a028_sideAB1stRowROpen "Restraint control module: a028 side ab1st row r open";
CM_ SG_ 1297 RCM_a028_sideAB1stRowRShort "Restraint control module: a028 side ab1st row r short";
CM_ SG_ 1297 RCM_a028_sideAB1stRowRCrossCoup "Restraint control module: a028 side ab1st row r cross coup";
CM_ SG_ 1297 RCM_a028_sideAB1stRowRConfig "Restraint control module: a028 side ab1st row r config";
CM_ SG_ 1297 RCM_a028_eventIDFsignal "Restraint control module: a028 event ID fsignal";
CM_ SG_ 1297 RCM_a028_eventFrontLeftSeatbelt "Restraint control module: a028 event front left seatbelt";
CM_ SG_ 1297 RCM_a028_eventFrontRightSeatbelt "Restraint control module: a028 event front right seatbelt";
CM_ SG_ 1297 RCM_a028_eventVehicleSpeed "Restraint control module: a028 event vehicle speed";
CM_ SG_ 1297 RCM_a028_eventSteeringAngle "Restraint control module: a028 event steering angle";
CM_ SG_ 1297 RCM_a028_eventDriverBrakeApply "Restraint control module: a028 event driver brake apply; raw 3 = signal not available (SNA)";
CM_ SG_ 1297 RCM_a028_eventAccelPedalPos "Restraint control module: a028 event accel pedal pos; raw 255 = signal not available (SNA)";
CM_ SG_ 1297 RCM_a029_eventArmStatus "Restraint control module: a029 event arm status";
CM_ SG_ 1297 RCM_a029_eventFactoryMode "Restraint control module: a029 event factory mode";
CM_ SG_ 1297 RCM_a029_eventDiagEnabled "Restraint control module: a029 event diag enabled";
CM_ SG_ 1297 RCM_a029_eventDriveOrientation "Restraint control module: a029 event drive orientation";
CM_ SG_ 1297 RCM_a029_driverABAVSht2Gnd "Restraint control module: a029 driver ABAV sht2 gnd";
CM_ SG_ 1297 RCM_a029_driverABAVSht2Bat "Restraint control module: a029 driver ABAV sht2 bat";
CM_ SG_ 1297 RCM_a029_driverABAVOpen "Restraint control module: a029 driver ABAV open";
CM_ SG_ 1297 RCM_a029_driverABAVShort "Restraint control module: a029 driver ABAV short";
CM_ SG_ 1297 RCM_a029_driverABAVCrossCoup "Restraint control module: a029 driver ABAV cross coup";
CM_ SG_ 1297 RCM_a029_driverABAVConfig "Restraint control module: a029 driver ABAV config";
CM_ SG_ 1297 RCM_a029_eventIDFsignal "Restraint control module: a029 event ID fsignal";
CM_ SG_ 1297 RCM_a029_eventFrontLeftSeatbelt "Restraint control module: a029 event front left seatbelt";
CM_ SG_ 1297 RCM_a029_eventFrontRightSeatbelt "Restraint control module: a029 event front right seatbelt";
CM_ SG_ 1297 RCM_a029_eventVehicleSpeed "Restraint control module: a029 event vehicle speed";
CM_ SG_ 1297 RCM_a029_eventSteeringAngle "Restraint control module: a029 event steering angle";
CM_ SG_ 1297 RCM_a029_eventDriverBrakeApply "Restraint control module: a029 event driver brake apply; raw 3 = signal not available (SNA)";
CM_ SG_ 1297 RCM_a029_eventAccelPedalPos "Restraint control module: a029 event accel pedal pos; raw 255 = signal not available (SNA)";
CM_ SG_ 1297 RCM_a030_eventArmStatus "Restraint control module: a030 event arm status";
CM_ SG_ 1297 RCM_a030_eventFactoryMode "Restraint control module: a030 event factory mode";
CM_ SG_ 1297 RCM_a030_eventDiagEnabled "Restraint control module: a030 event diag enabled";
CM_ SG_ 1297 RCM_a030_eventDriveOrientation "Restraint control module: a030 event drive orientation";
CM_ SG_ 1297 RCM_a030_farsideABSht2Gnd "Restraint control module: a030 farside AB sht2 gnd";
CM_ SG_ 1297 RCM_a030_farsideABSht2Bat "Restraint control module: a030 farside AB sht2 bat";
CM_ SG_ 1297 RCM_a030_farsideABOpen "Restraint control module: a030 farside AB open";
CM_ SG_ 1297 RCM_a030_farsideABShort "Restraint control module: a030 farside AB short";
CM_ SG_ 1297 RCM_a030_farsideABCrossCoup "Restraint control module: a030 farside AB cross coup";
CM_ SG_ 1297 RCM_a030_farsideABConfig "Restraint control module: a030 farside AB config";
CM_ SG_ 1297 RCM_a030_eventIDFsignal "Restraint control module: a030 event ID fsignal";
CM_ SG_ 1297 RCM_a030_eventFrontLeftSeatbelt "Restraint control module: a030 event front left seatbelt";
CM_ SG_ 1297 RCM_a030_eventFrontRightSeatbelt "Restraint control module: a030 event front right seatbelt";
CM_ SG_ 1297 RCM_a030_eventVehicleSpeed "Restraint control module: a030 event vehicle speed";
CM_ SG_ 1297 RCM_a030_eventSteeringAngle "Restraint control module: a030 event steering angle";
CM_ SG_ 1297 RCM_a030_eventDriverBrakeApply "Restraint control module: a030 event driver brake apply; raw 3 = signal not available (SNA)";
CM_ SG_ 1297 RCM_a030_eventAccelPedalPos "Restraint control module: a030 event accel pedal pos; raw 255 = signal not available (SNA)";
CM_ SG_ 1297 RCM_a031_eventArmStatus "Restraint control module: a031 event arm status";
CM_ SG_ 1297 RCM_a031_eventFactoryMode "Restraint control module: a031 event factory mode";
CM_ SG_ 1297 RCM_a031_eventDiagEnabled "Restraint control module: a031 event diag enabled";
CM_ SG_ 1297 RCM_a031_eventDriveOrientation "Restraint control module: a031 event drive orientation";
CM_ SG_ 1297 RCM_a031_frntCentrABSht2Gnd "Restraint control module: a031 frnt centr AB sht2 gnd";
CM_ SG_ 1297 RCM_a031_frntCentrABSht2Bat "Restraint control module: a031 frnt centr AB sht2 bat";
CM_ SG_ 1297 RCM_a031_frntCentrABOpen "Restraint control module: a031 frnt centr AB open";
CM_ SG_ 1297 RCM_a031_frntCentrABShort "Restraint control module: a031 frnt centr AB short";
CM_ SG_ 1297 RCM_a031_frntCentrABCrossCoup "Restraint control module: a031 frnt centr AB cross coup";
CM_ SG_ 1297 RCM_a031_frntCentrABConfig "Restraint control module: a031 frnt centr AB config";
CM_ SG_ 1297 RCM_a031_eventIDFsignal "Restraint control module: a031 event ID fsignal";
CM_ SG_ 1297 RCM_a031_eventFrontLeftSeatbelt "Restraint control module: a031 event front left seatbelt";
CM_ SG_ 1297 RCM_a031_eventFrontRightSeatbelt "Restraint control module: a031 event front right seatbelt";
CM_ SG_ 1297 RCM_a031_eventVehicleSpeed "Restraint control module: a031 event vehicle speed";
CM_ SG_ 1297 RCM_a031_eventSteeringAngle "Restraint control module: a031 event steering angle";
CM_ SG_ 1297 RCM_a031_eventDriverBrakeApply "Restraint control module: a031 event driver brake apply; raw 3 = signal not available (SNA)";
CM_ SG_ 1297 RCM_a031_eventAccelPedalPos "Restraint control module: a031 event accel pedal pos; raw 255 = signal not available (SNA)";
CM_ SG_ 1297 RCM_a032_eventArmStatus "Restraint control module: a032 event arm status";
CM_ SG_ 1297 RCM_a032_eventFactoryMode "Restraint control module: a032 event factory mode";
CM_ SG_ 1297 RCM_a032_eventDiagEnabled "Restraint control module: a032 event diag enabled";
CM_ SG_ 1297 RCM_a032_eventDriveOrientation "Restraint control module: a032 event drive orientation";
CM_ SG_ 1297 RCM_a032_curABLeftSht2Gnd "Restraint control module: a032 cur AB left sht2 gnd";
CM_ SG_ 1297 RCM_a032_curABLeftSht2Bat "Restraint control module: a032 cur AB left sht2 bat";
CM_ SG_ 1297 RCM_a032_curABLeftOpen "Restraint control module: a032 cur AB left open";
CM_ SG_ 1297 RCM_a032_curABLeftShort "Restraint control module: a032 cur AB left short";
CM_ SG_ 1297 RCM_a032_curABLeftCrossCoup "Restraint control module: a032 cur AB left cross coup";
CM_ SG_ 1297 RCM_a032_curABLeftConfig "Restraint control module: a032 cur AB left config";
CM_ SG_ 1297 RCM_a032_eventIDFsignal "Restraint control module: a032 event ID fsignal";
CM_ SG_ 1297 RCM_a032_eventFrontLeftSeatbelt "Restraint control module: a032 event front left seatbelt";
CM_ SG_ 1297 RCM_a032_eventFrontRightSeatbelt "Restraint control module: a032 event front right seatbelt";
CM_ SG_ 1297 RCM_a032_eventVehicleSpeed "Restraint control module: a032 event vehicle speed";
CM_ SG_ 1297 RCM_a032_eventSteeringAngle "Restraint control module: a032 event steering angle";
CM_ SG_ 1297 RCM_a032_eventDriverBrakeApply "Restraint control module: a032 event driver brake apply; raw 3 = signal not available (SNA)";
CM_ SG_ 1297 RCM_a032_eventAccelPedalPos "Restraint control module: a032 event accel pedal pos; raw 255 = signal not available (SNA)";
CM_ SG_ 1297 RCM_a033_eventArmStatus "Restraint control module: a033 event arm status";
CM_ SG_ 1297 RCM_a033_eventFactoryMode "Restraint control module: a033 event factory mode";
CM_ SG_ 1297 RCM_a033_eventDiagEnabled "Restraint control module: a033 event diag enabled";
CM_ SG_ 1297 RCM_a033_eventDriveOrientation "Restraint control module: a033 event drive orientation";
CM_ SG_ 1297 RCM_a033_curABRightSht2Gnd "Restraint control module: a033 cur AB right sht2 gnd";
CM_ SG_ 1297 RCM_a033_curABRightSht2Bat "Restraint control module: a033 cur AB right sht2 bat";
CM_ SG_ 1297 RCM_a033_curABRightOpen "Restraint control module: a033 cur AB right open";
CM_ SG_ 1297 RCM_a033_curABRightShort "Restraint control module: a033 cur AB right short";
CM_ SG_ 1297 RCM_a033_curABRightCrossCoup "Restraint control module: a033 cur AB right cross coup";
CM_ SG_ 1297 RCM_a033_curABRightConfig "Restraint control module: a033 cur AB right config";
CM_ SG_ 1297 RCM_a033_eventIDFsignal "Restraint control module: a033 event ID fsignal";
CM_ SG_ 1297 RCM_a033_eventFrontLeftSeatbelt "Restraint control module: a033 event front left seatbelt";
CM_ SG_ 1297 RCM_a033_eventFrontRightSeatbelt "Restraint control module: a033 event front right seatbelt";
CM_ SG_ 1297 RCM_a033_eventVehicleSpeed "Restraint control module: a033 event vehicle speed";
CM_ SG_ 1297 RCM_a033_eventSteeringAngle "Restraint control module: a033 event steering angle";
CM_ SG_ 1297 RCM_a033_eventDriverBrakeApply "Restraint control module: a033 event driver brake apply; raw 3 = signal not available (SNA)";
CM_ SG_ 1297 RCM_a033_eventAccelPedalPos "Restraint control module: a033 event accel pedal pos; raw 255 = signal not available (SNA)";
CM_ SG_ 1297 RCM_a034_eventArmStatus "Restraint control module: a034 event arm status";
CM_ SG_ 1297 RCM_a034_eventFactoryMode "Restraint control module: a034 event factory mode";
CM_ SG_ 1297 RCM_a034_eventDiagEnabled "Restraint control module: a034 event diag enabled";
CM_ SG_ 1297 RCM_a034_eventDriveOrientation "Restraint control module: a034 event drive orientation";
CM_ SG_ 1297 RCM_a034_preten2ndRowLSht2Gnd "Restraint control module: a034 preten2nd row l sht2 gnd";
CM_ SG_ 1297 RCM_a034_preten2ndRowLSht2Bat "Restraint control module: a034 preten2nd row l sht2 bat";
CM_ SG_ 1297 RCM_a034_preten2ndRowLOpen "Restraint control module: a034 preten2nd row l open";
CM_ SG_ 1297 RCM_a034_preten2ndRowLShort "Restraint control module: a034 preten2nd row l short";
CM_ SG_ 1297 RCM_a034_preten2ndRowLCrossCoup "Restraint control module: a034 preten2nd row l cross coup";
CM_ SG_ 1297 RCM_a034_preten2ndRowLCgf "Restraint control module: a034 preten2nd row l cgf";
CM_ SG_ 1297 RCM_a034_eventIDFsignal "Restraint control module: a034 event ID fsignal";
CM_ SG_ 1297 RCM_a034_eventFrontLeftSeatbelt "Restraint control module: a034 event front left seatbelt";
CM_ SG_ 1297 RCM_a034_eventFrontRightSeatbelt "Restraint control module: a034 event front right seatbelt";
CM_ SG_ 1297 RCM_a034_eventVehicleSpeed "Restraint control module: a034 event vehicle speed";
CM_ SG_ 1297 RCM_a034_eventSteeringAngle "Restraint control module: a034 event steering angle";
CM_ SG_ 1297 RCM_a034_eventDriverBrakeApply "Restraint control module: a034 event driver brake apply; raw 3 = signal not available (SNA)";
CM_ SG_ 1297 RCM_a034_eventAccelPedalPos "Restraint control module: a034 event accel pedal pos; raw 255 = signal not available (SNA)";
CM_ SG_ 1297 RCM_a035_eventArmStatus "Restraint control module: a035 event arm status";
CM_ SG_ 1297 RCM_a035_eventFactoryMode "Restraint control module: a035 event factory mode";
CM_ SG_ 1297 RCM_a035_eventDiagEnabled "Restraint control module: a035 event diag enabled";
CM_ SG_ 1297 RCM_a035_eventDriveOrientation "Restraint control module: a035 event drive orientation";
CM_ SG_ 1297 RCM_a035_preten2ndRowRSht2Gnd "Restraint control module: a035 preten2nd row r sht2 gnd";
CM_ SG_ 1297 RCM_a035_preten2ndRowRSht2Bat "Restraint control module: a035 preten2nd row r sht2 bat";
CM_ SG_ 1297 RCM_a035_preten2ndRowROpen "Restraint control module: a035 preten2nd row r open";
CM_ SG_ 1297 RCM_a035_preten2ndRowRShort "Restraint control module: a035 preten2nd row r short";
CM_ SG_ 1297 RCM_a035_preten2ndRowRCrossCoup "Restraint control module: a035 preten2nd row r cross coup";
CM_ SG_ 1297 RCM_a035_preten2ndRowRCgf "Restraint control module: a035 preten2nd row r cgf";
CM_ SG_ 1297 RCM_a035_eventIDFsignal "Restraint control module: a035 event ID fsignal";
CM_ SG_ 1297 RCM_a035_eventFrontLeftSeatbelt "Restraint control module: a035 event front left seatbelt";
CM_ SG_ 1297 RCM_a035_eventFrontRightSeatbelt "Restraint control module: a035 event front right seatbelt";
CM_ SG_ 1297 RCM_a035_eventVehicleSpeed "Restraint control module: a035 event vehicle speed";
CM_ SG_ 1297 RCM_a035_eventSteeringAngle "Restraint control module: a035 event steering angle";
CM_ SG_ 1297 RCM_a035_eventDriverBrakeApply "Restraint control module: a035 event driver brake apply; raw 3 = signal not available (SNA)";
CM_ SG_ 1297 RCM_a035_eventAccelPedalPos "Restraint control module: a035 event accel pedal pos; raw 255 = signal not available (SNA)";
CM_ SG_ 1297 RCM_a036_eventArmStatus "Restraint control module: a036 event arm status";
CM_ SG_ 1297 RCM_a036_eventFactoryMode "Restraint control module: a036 event factory mode";
CM_ SG_ 1297 RCM_a036_eventDiagEnabled "Restraint control module: a036 event diag enabled";
CM_ SG_ 1297 RCM_a036_eventDriveOrientation "Restraint control module: a036 event drive orientation";
CM_ SG_ 1297 RCM_a036_curAB2ndRowLSht2Gnd "Restraint control module: a036 cur ab2nd row l sht2 gnd";
CM_ SG_ 1297 RCM_a036_curAB2ndRowLSht2Bat "Restraint control module: a036 cur ab2nd row l sht2 bat";
CM_ SG_ 1297 RCM_a036_curAB2ndRowLOpen "Restraint control module: a036 cur ab2nd row l open";
CM_ SG_ 1297 RCM_a036_curAB2ndRowLShort "Restraint control module: a036 cur ab2nd row l short";
CM_ SG_ 1297 RCM_a036_curAB2ndRowLCrossCoup "Restraint control module: a036 cur ab2nd row l cross coup";
CM_ SG_ 1297 RCM_a036_curAB2ndRowLConfig "Restraint control module: a036 cur ab2nd row l config";
CM_ SG_ 1297 RCM_a036_eventIDFsignal "Restraint control module: a036 event ID fsignal";
CM_ SG_ 1297 RCM_a036_eventFrontLeftSeatbelt "Restraint control module: a036 event front left seatbelt";
CM_ SG_ 1297 RCM_a036_eventFrontRightSeatbelt "Restraint control module: a036 event front right seatbelt";
CM_ SG_ 1297 RCM_a036_eventVehicleSpeed "Restraint control module: a036 event vehicle speed";
CM_ SG_ 1297 RCM_a036_eventSteeringAngle "Restraint control module: a036 event steering angle";
CM_ SG_ 1297 RCM_a036_eventDriverBrakeApply "Restraint control module: a036 event driver brake apply; raw 3 = signal not available (SNA)";
CM_ SG_ 1297 RCM_a036_eventAccelPedalPos "Restraint control module: a036 event accel pedal pos; raw 255 = signal not available (SNA)";
CM_ SG_ 1297 RCM_a037_eventArmStatus "Restraint control module: a037 event arm status";
CM_ SG_ 1297 RCM_a037_eventFactoryMode "Restraint control module: a037 event factory mode";
CM_ SG_ 1297 RCM_a037_eventDiagEnabled "Restraint control module: a037 event diag enabled";
CM_ SG_ 1297 RCM_a037_eventDriveOrientation "Restraint control module: a037 event drive orientation";
CM_ SG_ 1297 RCM_a037_curAB2ndRowRSht2Gnd "Restraint control module: a037 cur ab2nd row r sht2 gnd";
CM_ SG_ 1297 RCM_a037_curAB2ndRowRSht2Bat "Restraint control module: a037 cur ab2nd row r sht2 bat";
CM_ SG_ 1297 RCM_a037_curAB2ndRowROpen "Restraint control module: a037 cur ab2nd row r open";
CM_ SG_ 1297 RCM_a037_curAB2ndRowRShort "Restraint control module: a037 cur ab2nd row r short";
CM_ SG_ 1297 RCM_a037_curAB2ndRowRCrossCoup "Restraint control module: a037 cur ab2nd row r cross coup";
CM_ SG_ 1297 RCM_a037_curAB2ndRowRConfig "Restraint control module: a037 cur ab2nd row r config";
CM_ SG_ 1297 RCM_a037_eventIDFsignal "Restraint control module: a037 event ID fsignal";
CM_ SG_ 1297 RCM_a037_eventFrontLeftSeatbelt "Restraint control module: a037 event front left seatbelt";
CM_ SG_ 1297 RCM_a037_eventFrontRightSeatbelt "Restraint control module: a037 event front right seatbelt";
CM_ SG_ 1297 RCM_a037_eventVehicleSpeed "Restraint control module: a037 event vehicle speed";
CM_ SG_ 1297 RCM_a037_eventSteeringAngle "Restraint control module: a037 event steering angle";
CM_ SG_ 1297 RCM_a037_eventDriverBrakeApply "Restraint control module: a037 event driver brake apply; raw 3 = signal not available (SNA)";
CM_ SG_ 1297 RCM_a037_eventAccelPedalPos "Restraint control module: a037 event accel pedal pos; raw 255 = signal not available (SNA)";
CM_ SG_ 1297 RCM_a040_eventArmStatus "Restraint control module: a040 event arm status";
CM_ SG_ 1297 RCM_a040_eventFactoryMode "Restraint control module: a040 event factory mode";
CM_ SG_ 1297 RCM_a040_eventDiagEnabled "Restraint control module: a040 event diag enabled";
CM_ SG_ 1297 RCM_a040_eventDriveOrientation "Restraint control module: a040 event drive orientation";
CM_ SG_ 1297 RCM_a040_hoodActuatorRSht2Gnd "Restraint control module: a040 hood actuator r sht2 gnd";
CM_ SG_ 1297 RCM_a040_hoodActuatorRSht2Bat "Restraint control module: a040 hood actuator r sht2 bat";
CM_ SG_ 1297 RCM_a040_hoodActuatorROpen "Restraint control module: a040 hood actuator r open";
CM_ SG_ 1297 RCM_a040_hoodActuatorRShort "Restraint control module: a040 hood actuator r short";
CM_ SG_ 1297 RCM_a040_hoodActuatorRCrossCoup "Restraint control module: a040 hood actuator r cross coup";
CM_ SG_ 1297 RCM_a040_hoodActuatorRConfig "Restraint control module: a040 hood actuator r config";
CM_ SG_ 1297 RCM_a040_eventIDFsignal "Restraint control module: a040 event ID fsignal";
CM_ SG_ 1297 RCM_a040_eventFrontLeftSeatbelt "Restraint control module: a040 event front left seatbelt";
CM_ SG_ 1297 RCM_a040_eventFrontRightSeatbelt "Restraint control module: a040 event front right seatbelt";
CM_ SG_ 1297 RCM_a040_eventVehicleSpeed "Restraint control module: a040 event vehicle speed";
CM_ SG_ 1297 RCM_a040_eventSteeringAngle "Restraint control module: a040 event steering angle";
CM_ SG_ 1297 RCM_a040_eventDriverBrakeApply "Restraint control module: a040 event driver brake apply; raw 3 = signal not available (SNA)";
CM_ SG_ 1297 RCM_a040_eventAccelPedalPos "Restraint control module: a040 event accel pedal pos; raw 255 = signal not available (SNA)";
CM_ SG_ 1297 RCM_a041_eventArmStatus "Restraint control module: a041 event arm status";
CM_ SG_ 1297 RCM_a041_eventFactoryMode "Restraint control module: a041 event factory mode";
CM_ SG_ 1297 RCM_a041_eventDiagEnabled "Restraint control module: a041 event diag enabled";
CM_ SG_ 1297 RCM_a041_eventDriveOrientation "Restraint control module: a041 event drive orientation";
CM_ SG_ 1297 RCM_a041_hoodActuatorLSht2Gnd "Restraint control module: a041 hood actuator l sht2 gnd";
CM_ SG_ 1297 RCM_a041_hoodActuatorLSht2Bat "Restraint control module: a041 hood actuator l sht2 bat";
CM_ SG_ 1297 RCM_a041_hoodActuatorLOpen "Restraint control module: a041 hood actuator l open";
CM_ SG_ 1297 RCM_a041_hoodActuatorLShort "Restraint control module: a041 hood actuator l short";
CM_ SG_ 1297 RCM_a041_hoodActuatorLCrossCoup "Restraint control module: a041 hood actuator l cross coup";
CM_ SG_ 1297 RCM_a041_hoodActuatorLConfig "Restraint control module: a041 hood actuator l config";
CM_ SG_ 1297 RCM_a041_eventIDFsignal "Restraint control module: a041 event ID fsignal";
CM_ SG_ 1297 RCM_a041_eventFrontLeftSeatbelt "Restraint control module: a041 event front left seatbelt";
CM_ SG_ 1297 RCM_a041_eventFrontRightSeatbelt "Restraint control module: a041 event front right seatbelt";
CM_ SG_ 1297 RCM_a041_eventVehicleSpeed "Restraint control module: a041 event vehicle speed";
CM_ SG_ 1297 RCM_a041_eventSteeringAngle "Restraint control module: a041 event steering angle";
CM_ SG_ 1297 RCM_a041_eventDriverBrakeApply "Restraint control module: a041 event driver brake apply; raw 3 = signal not available (SNA)";
CM_ SG_ 1297 RCM_a041_eventAccelPedalPos "Restraint control module: a041 event accel pedal pos; raw 255 = signal not available (SNA)";
CM_ SG_ 1297 RCM_a042_eventArmStatus "Restraint control module: a042 event arm status";
CM_ SG_ 1297 RCM_a042_eventFactoryMode "Restraint control module: a042 event factory mode";
CM_ SG_ 1297 RCM_a042_eventDiagEnabled "Restraint control module: a042 event diag enabled";
CM_ SG_ 1297 RCM_a042_eventDriveOrientation "Restraint control module: a042 event drive orientation";
CM_ SG_ 1297 RCM_a042_ens1Sht2Bat "Restraint control module: a042 ens1 sht2 bat";
CM_ SG_ 1297 RCM_a042_ens1Sht2Gnd "Restraint control module: a042 ens1 sht2 gnd";
CM_ SG_ 1297 RCM_a042_ens1Config "Restraint control module: a042 ens1 config";
CM_ SG_ 1297 RCM_a042_eventIDFsignal "Restraint control module: a042 event ID fsignal";
CM_ SG_ 1297 RCM_a042_eventFrontLeftSeatbelt "Restraint control module: a042 event front left seatbelt";
CM_ SG_ 1297 RCM_a042_eventFrontRightSeatbelt "Restraint control module: a042 event front right seatbelt";
CM_ SG_ 1297 RCM_a042_eventVehicleSpeed "Restraint control module: a042 event vehicle speed";
CM_ SG_ 1297 RCM_a042_eventSteeringAngle "Restraint control module: a042 event steering angle";
CM_ SG_ 1297 RCM_a042_eventDriverBrakeApply "Restraint control module: a042 event driver brake apply; raw 3 = signal not available (SNA)";
CM_ SG_ 1297 RCM_a042_eventAccelPedalPos "Restraint control module: a042 event accel pedal pos; raw 255 = signal not available (SNA)";
CM_ SG_ 1297 RCM_a043_eventArmStatus "Restraint control module: a043 event arm status";
CM_ SG_ 1297 RCM_a043_eventFactoryMode "Restraint control module: a043 event factory mode";
CM_ SG_ 1297 RCM_a043_eventDiagEnabled "Restraint control module: a043 event diag enabled";
CM_ SG_ 1297 RCM_a043_eventDriveOrientation "Restraint control module: a043 event drive orientation";
CM_ SG_ 1297 RCM_a043_ens2Sht2Bat "Restraint control module: a043 ens2 sht2 bat";
CM_ SG_ 1297 RCM_a043_ens2Sht2Gnd "Restraint control module: a043 ens2 sht2 gnd";
CM_ SG_ 1297 RCM_a043_ens2Config "Restraint control module: a043 ens2 config";
CM_ SG_ 1297 RCM_a043_eventIDFsignal "Restraint control module: a043 event ID fsignal";
CM_ SG_ 1297 RCM_a043_eventFrontLeftSeatbelt "Restraint control module: a043 event front left seatbelt";
CM_ SG_ 1297 RCM_a043_eventFrontRightSeatbelt "Restraint control module: a043 event front right seatbelt";
CM_ SG_ 1297 RCM_a043_eventVehicleSpeed "Restraint control module: a043 event vehicle speed";
CM_ SG_ 1297 RCM_a043_eventSteeringAngle "Restraint control module: a043 event steering angle";
CM_ SG_ 1297 RCM_a043_eventDriverBrakeApply "Restraint control module: a043 event driver brake apply; raw 3 = signal not available (SNA)";
CM_ SG_ 1297 RCM_a043_eventAccelPedalPos "Restraint control module: a043 event accel pedal pos; raw 255 = signal not available (SNA)";
CM_ SG_ 1297 RCM_a044_eventArmStatus "Restraint control module: a044 event arm status";
CM_ SG_ 1297 RCM_a044_eventFactoryMode "Restraint control module: a044 event factory mode";
CM_ SG_ 1297 RCM_a044_eventDiagEnabled "Restraint control module: a044 event diag enabled";
CM_ SG_ 1297 RCM_a044_eventDriveOrientation "Restraint control module: a044 event drive orientation";
CM_ SG_ 1297 RCM_a044_upFrontSensorLSht2Gnd "Restraint control module: a044 up front sensor l sht2 gnd";
CM_ SG_ 1297 RCM_a044_upFrontSensorLSht2Bat "Restraint control module: a044 up front sensor l sht2 bat";
CM_ SG_ 1297 RCM_a044_upFrontSensorLCrossCoup "Restraint control module: a044 up front sensor l cross coup";
CM_ SG_ 1297 RCM_a044_upFrontSensorLComm "Restraint control module: a044 up front sensor l comm";
CM_ SG_ 1297 RCM_a044_upFrontSensorLInitTyp "Restraint control module: a044 up front sensor l init typ";
CM_ SG_ 1297 RCM_a044_upFrontSensorLOption "Restraint control module: a044 up front sensor l option";
CM_ SG_ 1297 RCM_a044_upFrontSensorLplaus "Restraint control module: a044 up front sensor lplaus";
CM_ SG_ 1297 RCM_a044_upFrontSensorLDefect "Restraint control module: a044 up front sensor l defect";
CM_ SG_ 1297 RCM_a044_eventIDFsignal "Restraint control module: a044 event ID fsignal";
CM_ SG_ 1297 RCM_a044_eventFrontLeftSeatbelt "Restraint control module: a044 event front left seatbelt";
CM_ SG_ 1297 RCM_a044_eventFrontRightSeatbelt "Restraint control module: a044 event front right seatbelt";
CM_ SG_ 1297 RCM_a044_eventVehicleSpeed "Restraint control module: a044 event vehicle speed";
CM_ SG_ 1297 RCM_a044_eventSteeringAngle "Restraint control module: a044 event steering angle";
CM_ SG_ 1297 RCM_a044_eventDriverBrakeApply "Restraint control module: a044 event driver brake apply; raw 3 = signal not available (SNA)";
CM_ SG_ 1297 RCM_a044_eventAccelPedalPos "Restraint control module: a044 event accel pedal pos; raw 255 = signal not available (SNA)";
CM_ SG_ 1297 RCM_a045_eventArmStatus "Restraint control module: a045 event arm status";
CM_ SG_ 1297 RCM_a045_eventFactoryMode "Restraint control module: a045 event factory mode";
CM_ SG_ 1297 RCM_a045_eventDiagEnabled "Restraint control module: a045 event diag enabled";
CM_ SG_ 1297 RCM_a045_eventDriveOrientation "Restraint control module: a045 event drive orientation";
CM_ SG_ 1297 RCM_a045_upFrontSensorRSht2Gnd "Restraint control module: a045 up front sensor r sht2 gnd";
CM_ SG_ 1297 RCM_a045_upFrontSensorRSht2Bat "Restraint control module: a045 up front sensor r sht2 bat";
CM_ SG_ 1297 RCM_a045_upFrontSensorRCrossCoup "Restraint control module: a045 up front sensor r cross coup";
CM_ SG_ 1297 RCM_a045_upFrontSensorRComm "Restraint control module: a045 up front sensor r comm";
CM_ SG_ 1297 RCM_a045_upFrontSensorRInitTyp "Restraint control module: a045 up front sensor r init typ";
CM_ SG_ 1297 RCM_a045_upFrontSensorROption "Restraint control module: a045 up front sensor r option";
CM_ SG_ 1297 RCM_a045_upFrontSensorRplaus "Restraint control module: a045 up front sensor rplaus";
CM_ SG_ 1297 RCM_a045_upFrontSensorRDefect "Restraint control module: a045 up front sensor r defect";
CM_ SG_ 1297 RCM_a045_eventIDFsignal "Restraint control module: a045 event ID fsignal";
CM_ SG_ 1297 RCM_a045_eventFrontLeftSeatbelt "Restraint control module: a045 event front left seatbelt";
BA_DEF_ BO_ "GenMsgCycleTime" INT 0 3600000;
BA_DEF_ BO_ "GenMsgSendType" ENUM "Cyclic","NotUsed","NotUsed","NotUsed","NotUsed","NotUsed","NotUsed","IfActive","NoMsgSendType","NotUsed";
BA_DEF_ BO_ "VFrameFormat" ENUM "StandardCAN","ExtendedCAN","reserved","J1939PG","reserved","reserved","reserved","reserved","reserved","reserved","reserved","reserved","reserved","reserved","StandardCAN_FD","ExtendedCAN_FD";
BA_DEF_ BO_ "CANFD_BRS" ENUM "0","1";
BA_DEF_ SG_ "GenSigSNA" STRING;
BA_DEF_ SG_ "SystemSignalLongSymbol" STRING;
BA_DEF_ SG_ "Confidence" ENUM "validated","plausible","layout-only","contradicted";
BA_DEF_DEF_ "GenMsgCycleTime" 0;
BA_DEF_DEF_ "GenMsgSendType" "NoMsgSendType";
BA_DEF_DEF_ "VFrameFormat" "StandardCAN";
BA_DEF_DEF_ "CANFD_BRS" "1";
BA_DEF_DEF_ "GenSigSNA" "";
BA_DEF_DEF_ "SystemSignalLongSymbol" "";
BA_DEF_DEF_ "Confidence" "layout-only";
BA_ "GenMsgCycleTime" BO_ 896 1000;
BA_ "GenMsgSendType" BO_ 896 0;
BA_ "GenMsgCycleTime" BO_ 463 10;
BA_ "GenMsgSendType" BO_ 463 0;
BA_ "GenMsgCycleTime" BO_ 519 100;
BA_ "GenMsgSendType" BO_ 519 0;
BA_ "SystemSignalLongSymbol" SG_ 896 PM_a070_brakeTorqueSplitMonitorT "PM_a070_brakeTorqueSplitMonitorTrip";
BA_ "SystemSignalLongSymbol" SG_ 896 PM_a072_brakeTorqueCommandInterf "PM_a072_brakeTorqueCommandInterface";
BA_ "SystemSignalLongSymbol" SG_ 896 PM_a086_exceptionUndefinedInstru "PM_a086_exceptionUndefinedInstruction";
BA_ "SystemSignalLongSymbol" SG_ 896 PM_a095_ITPMSTimeoutGNSSConverge "PM_a095_ITPMSTimeoutGNSSConvergence";
BA_ "SystemSignalLongSymbol" SG_ 896 PM_a096_ITPMSConvergedGNSSAbsRad "PM_a096_ITPMSConvergedGNSSAbsRadiusTimes";
BA_ "SystemSignalLongSymbol" SG_ 896 PM_a110_indirectTPMSSoftWarningF "PM_a110_indirectTPMSSoftWarningFrontLeft";
BA_ "SystemSignalLongSymbol" SG_ 896 PM_a111_indirectTPMSSoftWarningF "PM_a111_indirectTPMSSoftWarningFrontRight";
BA_ "SystemSignalLongSymbol" SG_ 896 PM_a112_indirectTPMSSoftWarningR "PM_a112_indirectTPMSSoftWarningRearLeft";
BA_ "SystemSignalLongSymbol" SG_ 896 PM_a113_indirectTPMSSoftWarningR "PM_a113_indirectTPMSSoftWarningRearRight";
BA_ "SystemSignalLongSymbol" SG_ 896 PM_a114_indirectTPMSHardWarningF "PM_a114_indirectTPMSHardWarningFrontLeft";
BA_ "SystemSignalLongSymbol" SG_ 896 PM_a115_indirectTPMSHardWarningF "PM_a115_indirectTPMSHardWarningFrontRight";
BA_ "SystemSignalLongSymbol" SG_ 896 PM_a116_indirectTPMSHardWarningR "PM_a116_indirectTPMSHardWarningRearLeft";
BA_ "SystemSignalLongSymbol" SG_ 896 PM_a117_indirectTPMSHardWarningR "PM_a117_indirectTPMSHardWarningRearRight";
BA_ "Confidence" SG_ 463 PM_torqueCheckState 1;
BA_ "Confidence" SG_ 463 PM_limpRequest 1;
BA_ "Confidence" SG_ 463 PM_torqueCommand 1;
BA_ "GenSigSNA" SG_ 463 PM_torqueCommand "4096";
BA_ "Confidence" SG_ 463 PM_torqueState 1;
BA_ "Confidence" SG_ 463 PM_hvilSystemStatus 1;
BA_ "GenSigSNA" SG_ 463 PM_hvilSystemStatus "3";
BA_ "Confidence" SG_ 463 PM_sysElecPower 1;
BA_ "GenSigSNA" SG_ 463 PM_sysElecPower "1024";
BA_ "Confidence" SG_ 519 PTC_leftFlagFault 0;
BA_ "Confidence" SG_ 519 PTC_rightFlagFault 0;
BA_ "Confidence" SG_ 519 PTC_leftPowerDerating 0;
BA_ "Confidence" SG_ 519 PTC_rightPowerDerating 0;
BA_ "Confidence" SG_ 519 PTC_ocpEvent 0;
BA_ "Confidence" SG_ 519 PTC_leftDutyFeedback 0;
BA_ "Confidence" SG_ 519 PTC_rightDutyFeedback 0;
BA_ "Confidence" SG_ 519 PTC_leftPowerHV 0;
BA_ "Confidence" SG_ 519 PTC_rightPowerHV 0;
BA_ "Confidence" SG_ 519 PTC_leftTempEstOutlet 0;
BA_ "Confidence" SG_ 519 PTC_rightTempEstOutlet 0;
BA_ "Confidence" SG_ 519 PTC_tliErrorCount 0;
BA_ "Confidence" SG_ 519 PTC_tliEvent 0;
BA_ "Confidence" SG_ 519 PTC_tliSource 0;
BA_ "Confidence" SG_ 1297 RCM_alertID 1;
BA_ "Confidence" SG_ 1297 RCM_alertState 1;
BA_ "Confidence" SG_ 1297 RCM_a000_eventArmStatus 1;
BA_ "Confidence" SG_ 1297 RCM_a000_eventFactoryMode 1;
BA_ "Confidence" SG_ 1297 RCM_a000_eventDiagEnabled 1;
BA_ "Confidence" SG_ 1297 RCM_a000_eventDriveOrientation 1;
BA_ "Confidence" SG_ 1297 RCM_a000_eventIDFsignal 1;
BA_ "Confidence" SG_ 1297 RCM_a000_eventFrontLeftSeatbelt 1;
BA_ "Confidence" SG_ 1297 RCM_a000_eventFrontRightSeatbelt 1;
BA_ "Confidence" SG_ 1297 RCM_a000_eventVehicleSpeed 1;
BA_ "Confidence" SG_ 1297 RCM_a000_eventSteeringAngle 1;
BA_ "Confidence" SG_ 1297 RCM_a000_eventDriverBrakeApply 1;
BA_ "Confidence" SG_ 1297 RCM_a000_eventAccelPedalPos 1;
BA_ "Confidence" SG_ 1297 RCM_a001_eventArmStatus 1;
BA_ "Confidence" SG_ 1297 RCM_a001_eventFactoryMode 1;
BA_ "Confidence" SG_ 1297 RCM_a001_eventDiagEnabled 1;
BA_ "Confidence" SG_ 1297 RCM_a001_eventDriveOrientation 1;
BA_ "Confidence" SG_ 1297 RCM_a001_eventIDFsignal 1;
BA_ "Confidence" SG_ 1297 RCM_a001_eventFrontLeftSeatbelt 1;
BA_ "Confidence" SG_ 1297 RCM_a001_eventFrontRightSeatbelt 1;
BA_ "Confidence" SG_ 1297 RCM_a001_eventVehicleSpeed 1;
BA_ "Confidence" SG_ 1297 RCM_a001_eventSteeringAngle 1;
BA_ "Confidence" SG_ 1297 RCM_a001_eventDriverBrakeApply 1;
BA_ "GenSigSNA" SG_ 1297 RCM_a001_eventDriverBrakeApply "3";
BA_ "Confidence" SG_ 1297 RCM_a001_eventAccelPedalPos 1;
BA_ "GenSigSNA" SG_ 1297 RCM_a001_eventAccelPedalPos "255";
BA_ "Confidence" SG_ 1297 RCM_a002_eventArmStatus 1;
BA_ "Confidence" SG_ 1297 RCM_a002_eventFactoryMode 1;
BA_ "Confidence" SG_ 1297 RCM_a002_eventDiagEnabled 1;
BA_ "Confidence" SG_ 1297 RCM_a002_eventDriveOrientation 1;
BA_ "Confidence" SG_ 1297 RCM_a002_eventIDFsignal 1;
BA_ "Confidence" SG_ 1297 RCM_a002_eventFrontLeftSeatbelt 1;
BA_ "Confidence" SG_ 1297 RCM_a002_eventFrontRightSeatbelt 1;
BA_ "Confidence" SG_ 1297 RCM_a002_eventVehicleSpeed 1;
BA_ "Confidence" SG_ 1297 RCM_a002_eventSteeringAngle 1;
BA_ "Confidence" SG_ 1297 RCM_a002_eventDriverBrakeApply 1;
BA_ "GenSigSNA" SG_ 1297 RCM_a002_eventDriverBrakeApply "3";
BA_ "Confidence" SG_ 1297 RCM_a002_eventAccelPedalPos 1;
BA_ "GenSigSNA" SG_ 1297 RCM_a002_eventAccelPedalPos "255";
BA_ "Confidence" SG_ 1297 RCM_a003_eventArmStatus 1;
BA_ "Confidence" SG_ 1297 RCM_a003_eventFactoryMode 1;
BA_ "Confidence" SG_ 1297 RCM_a003_eventDiagEnabled 1;
BA_ "Confidence" SG_ 1297 RCM_a003_eventDriveOrientation 1;
BA_ "Confidence" SG_ 1297 RCM_a003_eventIDFsignal 1;
BA_ "Confidence" SG_ 1297 RCM_a003_eventFrontLeftSeatbelt 1;
BA_ "Confidence" SG_ 1297 RCM_a003_eventFrontRightSeatbelt 1;
BA_ "Confidence" SG_ 1297 RCM_a003_eventVehicleSpeed 1;
BA_ "Confidence" SG_ 1297 RCM_a003_eventSteeringAngle 1;
BA_ "Confidence" SG_ 1297 RCM_a003_eventDriverBrakeApply 1;
BA_ "GenSigSNA" SG_ 1297 RCM_a003_eventDriverBrakeApply "3";
BA_ "Confidence" SG_ 1297 RCM_a003_eventAccelPedalPos 1;
BA_ "GenSigSNA" SG_ 1297 RCM_a003_eventAccelPedalPos "255";
BA_ "Confidence" SG_ 1297 RCM_a004_eventArmStatus 1;
BA_ "Confidence" SG_ 1297 RCM_a004_eventFactoryMode 1;
BA_ "Confidence" SG_ 1297 RCM_a004_eventDiagEnabled 1;
BA_ "Confidence" SG_ 1297 RCM_a004_eventDriveOrientation 1;
BA_ "Confidence" SG_ 1297 RCM_a004_eventIDFsignal 1;
BA_ "Confidence" SG_ 1297 RCM_a004_eventFrontLeftSeatbelt 1;
BA_ "Confidence" SG_ 1297 RCM_a004_eventFrontRightSeatbelt 1;
BA_ "Confidence" SG_ 1297 RCM_a004_eventVehicleSpeed 1;
BA_ "Confidence" SG_ 1297 RCM_a004_eventSteeringAngle 1;
BA_ "Confidence" SG_ 1297 RCM_a004_eventDriverBrakeApply 1;
BA_ "GenSigSNA" SG_ 1297 RCM_a004_eventDriverBrakeApply "3";
BA_ "Confidence" SG_ 1297 RCM_a004_eventAccelPedalPos 1;
BA_ "GenSigSNA" SG_ 1297 RCM_a004_eventAccelPedalPos "255";
BA_ "Confidence" SG_ 1297 RCM_a005_eventArmStatus 1;
BA_ "Confidence" SG_ 1297 RCM_a005_eventFactoryMode 1;
BA_ "Confidence" SG_ 1297 RCM_a005_eventDiagEnabled 1;
BA_ "Confidence" SG_ 1297 RCM_a005_eventDriveOrientation 1;
BA_ "Confidence" SG_ 1297 RCM_a005_eventIDFsignal 1;
BA_ "Confidence" SG_ 1297 RCM_a005_eventFrontLeftSeatbelt 1;
BA_ "Confidence" SG_ 1297 RCM_a005_eventFrontRightSeatbelt 1;
BA_ "Confidence" SG_ 1297 RCM_a005_eventVehicleSpeed 1;
BA_ "Confidence" SG_ 1297 RCM_a005_eventSteeringAngle 1;
BA_ "Confidence" SG_ 1297 RCM_a005_eventDriverBrakeApply 1;
BA_ "GenSigSNA" SG_ 1297 RCM_a005_eventDriverBrakeApply "3";
BA_ "Confidence" SG_ 1297 RCM_a005_eventAccelPedalPos 1;
BA_ "GenSigSNA" SG_ 1297 RCM_a005_eventAccelPedalPos "255";
BA_ "Confidence" SG_ 1297 RCM_a006_eventArmStatus 1;
BA_ "Confidence" SG_ 1297 RCM_a006_eventFactoryMode 1;
BA_ "Confidence" SG_ 1297 RCM_a006_eventDiagEnabled 1;
BA_ "Confidence" SG_ 1297 RCM_a006_eventDriveOrientation 1;
BA_ "Confidence" SG_ 1297 RCM_a006_eventIDFsignal 1;
BA_ "Confidence" SG_ 1297 RCM_a006_eventFrontLeftSeatbelt 1;
BA_ "Confidence" SG_ 1297 RCM_a006_eventFrontRightSeatbelt 1;
BA_ "Confidence" SG_ 1297 RCM_a006_eventVehicleSpeed 1;
BA_ "Confidence" SG_ 1297 RCM_a006_eventSteeringAngle 1;
BA_ "Confidence" SG_ 1297 RCM_a006_eventDriverBrakeApply 1;
BA_ "GenSigSNA" SG_ 1297 RCM_a006_eventDriverBrakeApply "3";
BA_ "Confidence" SG_ 1297 RCM_a006_eventAccelPedalPos 1;
BA_ "GenSigSNA" SG_ 1297 RCM_a006_eventAccelPedalPos "255";
BA_ "Confidence" SG_ 1297 RCM_a008_eventArmStatus 1;
BA_ "Confidence" SG_ 1297 RCM_a008_eventFactoryMode 1;
BA_ "Confidence" SG_ 1297 RCM_a008_eventDiagEnabled 1;
BA_ "Confidence" SG_ 1297 RCM_a008_eventDriveOrientation 1;
BA_ "Confidence" SG_ 1297 RCM_a008_eventIDFsignal 1;
BA_ "Confidence" SG_ 1297 RCM_a008_eventFrontLeftSeatbelt 1;
BA_ "Confidence" SG_ 1297 RCM_a008_eventFrontRightSeatbelt 1;
BA_ "Confidence" SG_ 1297 RCM_a008_eventVehicleSpeed 1;
BA_ "Confidence" SG_ 1297 RCM_a008_eventSteeringAngle 1;
BA_ "Confidence" SG_ 1297 RCM_a008_eventDriverBrakeApply 1;
BA_ "GenSigSNA" SG_ 1297 RCM_a008_eventDriverBrakeApply "3";
BA_ "Confidence" SG_ 1297 RCM_a008_eventAccelPedalPos 1;
BA_ "GenSigSNA" SG_ 1297 RCM_a008_eventAccelPedalPos "255";
BA_ "Confidence" SG_ 1297 RCM_a009_eventArmStatus 1;
BA_ "Confidence" SG_ 1297 RCM_a009_eventFactoryMode 1;
BA_ "Confidence" SG_ 1297 RCM_a009_eventDiagEnabled 1;
BA_ "Confidence" SG_ 1297 RCM_a009_eventDriveOrientation 1;
BA_ "Confidence" SG_ 1297 RCM_a009_eventIDFsignal 1;
BA_ "Confidence" SG_ 1297 RCM_a009_eventFrontLeftSeatbelt 1;
BA_ "Confidence" SG_ 1297 RCM_a009_eventFrontRightSeatbelt 1;
BA_ "Confidence" SG_ 1297 RCM_a009_eventVehicleSpeed 1;
BA_ "Confidence" SG_ 1297 RCM_a009_eventSteeringAngle 1;
BA_ "Confidence" SG_ 1297 RCM_a009_eventDriverBrakeApply 1;
BA_ "GenSigSNA" SG_ 1297 RCM_a009_eventDriverBrakeApply "3";
BA_ "Confidence" SG_ 1297 RCM_a009_eventAccelPedalPos 1;
BA_ "GenSigSNA" SG_ 1297 RCM_a009_eventAccelPedalPos "255";
BA_ "Confidence" SG_ 1297 RCM_a011_eventArmStatus 1;
BA_ "Confidence" SG_ 1297 RCM_a011_eventFactoryMode 1;
BA_ "Confidence" SG_ 1297 RCM_a011_eventDiagEnabled 1;
BA_ "Confidence" SG_ 1297 RCM_a011_eventDriveOrientation 1;
BA_ "Confidence" SG_ 1297 RCM_a011_eventIDFsignal 1;
BA_ "Confidence" SG_ 1297 RCM_a011_eventFrontLeftSeatbelt 1;
BA_ "Confidence" SG_ 1297 RCM_a011_eventFrontRightSeatbelt 1;
BA_ "Confidence" SG_ 1297 RCM_a011_eventVehicleSpeed 1;
BA_ "Confidence" SG_ 1297 RCM_a011_eventSteeringAngle 1;
BA_ "Confidence" SG_ 1297 RCM_a011_eventDriverBrakeApply 1;
BA_ "GenSigSNA" SG_ 1297 RCM_a011_eventDriverBrakeApply "3";
BA_ "Confidence" SG_ 1297 RCM_a011_eventAccelPedalPos 1;
BA_ "GenSigSNA" SG_ 1297 RCM_a011_eventAccelPedalPos "255";
BA_ "Confidence" SG_ 1297 RCM_a012_eventArmStatus 1;
BA_ "Confidence" SG_ 1297 RCM_a012_eventFactoryMode 1;
BA_ "Confidence" SG_ 1297 RCM_a012_eventDiagEnabled 1;
BA_ "Confidence" SG_ 1297 RCM_a012_eventDriveOrientation 1;
BA_ "Confidence" SG_ 1297 RCM_a012_eventIDFsignal 1;
BA_ "Confidence" SG_ 1297 RCM_a012_eventFrontLeftSeatbelt 1;
BA_ "Confidence" SG_ 1297 RCM_a012_eventFrontRightSeatbelt 1;
BA_ "Confidence" SG_ 1297 RCM_a012_eventVehicleSpeed 1;
BA_ "Confidence" SG_ 1297 RCM_a012_eventSteeringAngle 1;
BA_ "Confidence" SG_ 1297 RCM_a012_eventDriverBrakeApply 1;
BA_ "GenSigSNA" SG_ 1297 RCM_a012_eventDriverBrakeApply "3";
BA_ "Confidence" SG_ 1297 RCM_a012_eventAccelPedalPos 1;
BA_ "GenSigSNA" SG_ 1297 RCM_a012_eventAccelPedalPos "255";
BA_ "Confidence" SG_ 1297 RCM_a013_eventArmStatus 1;
BA_ "Confidence" SG_ 1297 RCM_a013_eventFactoryMode 1;
BA_ "Confidence" SG_ 1297 RCM_a013_eventDiagEnabled 1;
BA_ "Confidence" SG_ 1297 RCM_a013_eventDriveOrientation 1;
BA_ "Confidence" SG_ 1297 RCM_a013_eventIDFsignal 1;
BA_ "Confidence" SG_ 1297 RCM_a013_eventFrontLeftSeatbelt 1;
BA_ "Confidence" SG_ 1297 RCM_a013_eventFrontRightSeatbelt 1;
BA_ "Confidence" SG_ 1297 RCM_a013_eventVehicleSpeed 1;
BA_ "Confidence" SG_ 1297 RCM_a013_eventSteeringAngle 1;
BA_ "Confidence" SG_ 1297 RCM_a013_eventDriverBrakeApply 1;
BA_ "GenSigSNA" SG_ 1297 RCM_a013_eventDriverBrakeApply "3";
BA_ "Confidence" SG_ 1297 RCM_a013_eventAccelPedalPos 1;
BA_ "GenSigSNA" SG_ 1297 RCM_a013_eventAccelPedalPos "255";
BA_ "Confidence" SG_ 1297 RCM_a014_eventArmStatus 1;
BA_ "Confidence" SG_ 1297 RCM_a014_eventFactoryMode 1;
BA_ "Confidence" SG_ 1297 RCM_a014_eventDiagEnabled 1;
BA_ "Confidence" SG_ 1297 RCM_a014_eventDriveOrientation 1;
BA_ "Confidence" SG_ 1297 RCM_a014_eventIDFsignal 1;
BA_ "Confidence" SG_ 1297 RCM_a014_eventFrontLeftSeatbelt 1;
BA_ "Confidence" SG_ 1297 RCM_a014_eventFrontRightSeatbelt 1;
BA_ "Confidence" SG_ 1297 RCM_a014_eventVehicleSpeed 1;
BA_ "Confidence" SG_ 1297 RCM_a014_eventSteeringAngle 1;
BA_ "Confidence" SG_ 1297 RCM_a014_eventDriverBrakeApply 1;
BA_ "GenSigSNA" SG_ 1297 RCM_a014_eventDriverBrakeApply "3";
BA_ "Confidence" SG_ 1297 RCM_a014_eventAccelPedalPos 1;
BA_ "GenSigSNA" SG_ 1297 RCM_a014_eventAccelPedalPos "255";
BA_ "Confidence" SG_ 1297 RCM_a015_eventArmStatus 1;
BA_ "Confidence" SG_ 1297 RCM_a015_eventFactoryMode 1;
BA_ "Confidence" SG_ 1297 RCM_a015_eventDiagEnabled 1;
BA_ "Confidence" SG_ 1297 RCM_a015_eventDriveOrientation 1;
BA_ "Confidence" SG_ 1297 RCM_a015_eventIDFsignal 1;
BA_ "Confidence" SG_ 1297 RCM_a015_eventFrontLeftSeatbelt 1;
BA_ "Confidence" SG_ 1297 RCM_a015_eventFrontRightSeatbelt 1;
BA_ "Confidence" SG_ 1297 RCM_a015_eventVehicleSpeed 1;
BA_ "Confidence" SG_ 1297 RCM_a015_eventSteeringAngle 1;
BA_ "Confidence" SG_ 1297 RCM_a015_eventDriverBrakeApply 1;
BA_ "GenSigSNA" SG_ 1297 RCM_a015_eventDriverBrakeApply "3";
BA_ "Confidence" SG_ 1297 RCM_a015_eventAccelPedalPos 1;
BA_ "GenSigSNA" SG_ 1297 RCM_a015_eventAccelPedalPos "255";
BA_ "Confidence" SG_ 1297 RCM_a016_eventArmStatus 1;
BA_ "Confidence" SG_ 1297 RCM_a016_eventFactoryMode 1;
BA_ "Confidence" SG_ 1297 RCM_a016_eventDiagEnabled 1;
BA_ "Confidence" SG_ 1297 RCM_a016_eventDriveOrientation 1;
BA_ "Confidence" SG_ 1297 RCM_a016_eventIDFsignal 1;
BA_ "Confidence" SG_ 1297 RCM_a016_eventFrontLeftSeatbelt 1;
BA_ "Confidence" SG_ 1297 RCM_a016_eventFrontRightSeatbelt 1;
BA_ "Confidence" SG_ 1297 RCM_a016_eventVehicleSpeed 1;
BA_ "Confidence" SG_ 1297 RCM_a016_eventSteeringAngle 1;
BA_ "Confidence" SG_ 1297 RCM_a016_eventDriverBrakeApply 1;
BA_ "GenSigSNA" SG_ 1297 RCM_a016_eventDriverBrakeApply "3";
BA_ "Confidence" SG_ 1297 RCM_a016_eventAccelPedalPos 1;
BA_ "GenSigSNA" SG_ 1297 RCM_a016_eventAccelPedalPos "255";
BA_ "Confidence" SG_ 1297 RCM_a017_eventArmStatus 1;
BA_ "Confidence" SG_ 1297 RCM_a017_eventFactoryMode 1;
BA_ "Confidence" SG_ 1297 RCM_a017_eventDiagEnabled 1;
BA_ "Confidence" SG_ 1297 RCM_a017_eventDriveOrientation 1;
BA_ "Confidence" SG_ 1297 RCM_a017_eventIDFsignal 1;
BA_ "Confidence" SG_ 1297 RCM_a017_eventFrontLeftSeatbelt 1;
BA_ "Confidence" SG_ 1297 RCM_a017_eventFrontRightSeatbelt 1;
BA_ "Confidence" SG_ 1297 RCM_a017_eventVehicleSpeed 1;
BA_ "Confidence" SG_ 1297 RCM_a017_eventSteeringAngle 1;
BA_ "Confidence" SG_ 1297 RCM_a017_eventDriverBrakeApply 1;
BA_ "GenSigSNA" SG_ 1297 RCM_a017_eventDriverBrakeApply "3";
BA_ "Confidence" SG_ 1297 RCM_a017_eventAccelPedalPos 1;
BA_ "GenSigSNA" SG_ 1297 RCM_a017_eventAccelPedalPos "255";
BA_ "Confidence" SG_ 1297 RCM_a018_eventArmStatus 1;
BA_ "Confidence" SG_ 1297 RCM_a018_eventFactoryMode 1;
BA_ "Confidence" SG_ 1297 RCM_a018_eventDiagEnabled 1;
BA_ "Confidence" SG_ 1297 RCM_a018_eventDriveOrientation 1;
BA_ "Confidence" SG_ 1297 RCM_a018_eventIDFsignal 1;
BA_ "Confidence" SG_ 1297 RCM_a018_eventFrontLeftSeatbelt 1;
BA_ "Confidence" SG_ 1297 RCM_a018_eventFrontRightSeatbelt 1;
BA_ "Confidence" SG_ 1297 RCM_a018_eventVehicleSpeed 1;
BA_ "Confidence" SG_ 1297 RCM_a018_eventSteeringAngle 1;
BA_ "Confidence" SG_ 1297 RCM_a018_eventDriverBrakeApply 1;
BA_ "GenSigSNA" SG_ 1297 RCM_a018_eventDriverBrakeApply "3";
BA_ "Confidence" SG_ 1297 RCM_a018_eventAccelPedalPos 1;
BA_ "GenSigSNA" SG_ 1297 RCM_a018_eventAccelPedalPos "255";
BA_ "Confidence" SG_ 1297 RCM_a019_eventArmStatus 1;
BA_ "Confidence" SG_ 1297 RCM_a019_eventFactoryMode 1;
BA_ "Confidence" SG_ 1297 RCM_a019_eventDiagEnabled 1;
BA_ "Confidence" SG_ 1297 RCM_a019_eventDriveOrientation 1;
BA_ "Confidence" SG_ 1297 RCM_a019_eventIDFsignal 1;
BA_ "Confidence" SG_ 1297 RCM_a019_eventFrontLeftSeatbelt 1;
BA_ "Confidence" SG_ 1297 RCM_a019_eventFrontRightSeatbelt 1;
BA_ "Confidence" SG_ 1297 RCM_a019_eventVehicleSpeed 1;
BA_ "Confidence" SG_ 1297 RCM_a019_eventSteeringAngle 1;
BA_ "Confidence" SG_ 1297 RCM_a019_eventDriverBrakeApply 1;
BA_ "GenSigSNA" SG_ 1297 RCM_a019_eventDriverBrakeApply "3";
BA_ "Confidence" SG_ 1297 RCM_a019_eventAccelPedalPos 1;
BA_ "GenSigSNA" SG_ 1297 RCM_a019_eventAccelPedalPos "255";
BA_ "Confidence" SG_ 1297 RCM_a020_eventArmStatus 1;
BA_ "Confidence" SG_ 1297 RCM_a020_eventFactoryMode 1;
BA_ "Confidence" SG_ 1297 RCM_a020_eventDiagEnabled 1;
BA_ "Confidence" SG_ 1297 RCM_a020_eventDriveOrientation 1;
BA_ "Confidence" SG_ 1297 RCM_a020_eventIDFsignal 1;
BA_ "Confidence" SG_ 1297 RCM_a020_eventFrontLeftSeatbelt 1;
BA_ "Confidence" SG_ 1297 RCM_a020_eventFrontRightSeatbelt 1;
BA_ "Confidence" SG_ 1297 RCM_a020_eventVehicleSpeed 1;
BA_ "Confidence" SG_ 1297 RCM_a020_eventSteeringAngle 1;
BA_ "Confidence" SG_ 1297 RCM_a020_eventDriverBrakeApply 1;
BA_ "GenSigSNA" SG_ 1297 RCM_a020_eventDriverBrakeApply "3";
BA_ "Confidence" SG_ 1297 RCM_a020_eventAccelPedalPos 1;
BA_ "GenSigSNA" SG_ 1297 RCM_a020_eventAccelPedalPos "255";
BA_ "Confidence" SG_ 1297 RCM_a021_eventArmStatus 1;
BA_ "Confidence" SG_ 1297 RCM_a021_eventFactoryMode 1;
BA_ "Confidence" SG_ 1297 RCM_a021_eventDiagEnabled 1;
BA_ "Confidence" SG_ 1297 RCM_a021_eventDriveOrientation 1;
BA_ "Confidence" SG_ 1297 RCM_a021_eventIDFsignal 1;
BA_ "Confidence" SG_ 1297 RCM_a021_eventFrontLeftSeatbelt 1;
BA_ "Confidence" SG_ 1297 RCM_a021_eventFrontRightSeatbelt 1;
BA_ "Confidence" SG_ 1297 RCM_a021_eventVehicleSpeed 1;
BA_ "Confidence" SG_ 1297 RCM_a021_eventSteeringAngle 1;
BA_ "Confidence" SG_ 1297 RCM_a021_eventDriverBrakeApply 1;
BA_ "GenSigSNA" SG_ 1297 RCM_a021_eventDriverBrakeApply "3";
BA_ "Confidence" SG_ 1297 RCM_a021_eventAccelPedalPos 1;
BA_ "GenSigSNA" SG_ 1297 RCM_a021_eventAccelPedalPos "255";
BA_ "Confidence" SG_ 1297 RCM_a022_eventArmStatus 1;
BA_ "Confidence" SG_ 1297 RCM_a022_eventFactoryMode 1;
BA_ "Confidence" SG_ 1297 RCM_a022_eventDiagEnabled 1;
BA_ "Confidence" SG_ 1297 RCM_a022_eventDriveOrientation 1;
BA_ "Confidence" SG_ 1297 RCM_a022_eventIDFsignal 1;
BA_ "Confidence" SG_ 1297 RCM_a022_eventFrontLeftSeatbelt 1;
BA_ "Confidence" SG_ 1297 RCM_a022_eventFrontRightSeatbelt 1;
BA_ "Confidence" SG_ 1297 RCM_a022_eventVehicleSpeed 1;
BA_ "Confidence" SG_ 1297 RCM_a022_eventSteeringAngle 1;
BA_ "Confidence" SG_ 1297 RCM_a022_eventDriverBrakeApply 1;
BA_ "GenSigSNA" SG_ 1297 RCM_a022_eventDriverBrakeApply "3";
BA_ "Confidence" SG_ 1297 RCM_a022_eventAccelPedalPos 1;
BA_ "GenSigSNA" SG_ 1297 RCM_a022_eventAccelPedalPos "255";
BA_ "Confidence" SG_ 1297 RCM_a023_eventArmStatus 1;
BA_ "Confidence" SG_ 1297 RCM_a023_eventFactoryMode 1;
BA_ "Confidence" SG_ 1297 RCM_a023_eventDiagEnabled 1;
BA_ "Confidence" SG_ 1297 RCM_a023_eventDriveOrientation 1;
BA_ "Confidence" SG_ 1297 RCM_a023_eventIDFsignal 1;
BA_ "Confidence" SG_ 1297 RCM_a023_eventFrontLeftSeatbelt 1;
BA_ "Confidence" SG_ 1297 RCM_a023_eventFrontRightSeatbelt 1;
BA_ "Confidence" SG_ 1297 RCM_a023_eventVehicleSpeed 1;
BA_ "Confidence" SG_ 1297 RCM_a023_eventSteeringAngle 1;
BA_ "Confidence" SG_ 1297 RCM_a023_eventDriverBrakeApply 1;
BA_ "GenSigSNA" SG_ 1297 RCM_a023_eventDriverBrakeApply "3";
BA_ "Confidence" SG_ 1297 RCM_a023_eventAccelPedalPos 1;
BA_ "GenSigSNA" SG_ 1297 RCM_a023_eventAccelPedalPos "255";
BA_ "Confidence" SG_ 1297 RCM_a024_eventArmStatus 1;
BA_ "Confidence" SG_ 1297 RCM_a024_eventFactoryMode 1;
BA_ "Confidence" SG_ 1297 RCM_a024_eventDiagEnabled 1;
BA_ "Confidence" SG_ 1297 RCM_a024_eventDriveOrientation 1;
BA_ "Confidence" SG_ 1297 RCM_a024_eventIDFsignal 1;
BA_ "Confidence" SG_ 1297 RCM_a024_eventFrontLeftSeatbelt 1;
BA_ "Confidence" SG_ 1297 RCM_a024_eventFrontRightSeatbelt 1;
BA_ "Confidence" SG_ 1297 RCM_a024_eventVehicleSpeed 1;
BA_ "Confidence" SG_ 1297 RCM_a024_eventSteeringAngle 1;
BA_ "Confidence" SG_ 1297 RCM_a024_eventDriverBrakeApply 1;
BA_ "GenSigSNA" SG_ 1297 RCM_a024_eventDriverBrakeApply "3";
BA_ "Confidence" SG_ 1297 RCM_a024_eventAccelPedalPos 1;
BA_ "GenSigSNA" SG_ 1297 RCM_a024_eventAccelPedalPos "255";
BA_ "Confidence" SG_ 1297 RCM_a025_eventArmStatus 1;
BA_ "Confidence" SG_ 1297 RCM_a025_eventFactoryMode 1;
BA_ "Confidence" SG_ 1297 RCM_a025_eventDiagEnabled 1;
BA_ "Confidence" SG_ 1297 RCM_a025_eventDriveOrientation 1;
BA_ "Confidence" SG_ 1297 RCM_a025_eventIDFsignal 1;
BA_ "Confidence" SG_ 1297 RCM_a025_eventFrontLeftSeatbelt 1;
BA_ "Confidence" SG_ 1297 RCM_a025_eventFrontRightSeatbelt 1;
BA_ "Confidence" SG_ 1297 RCM_a025_eventVehicleSpeed 1;
BA_ "Confidence" SG_ 1297 RCM_a025_eventSteeringAngle 1;
BA_ "Confidence" SG_ 1297 RCM_a025_eventDriverBrakeApply 1;
BA_ "GenSigSNA" SG_ 1297 RCM_a025_eventDriverBrakeApply "3";
BA_ "Confidence" SG_ 1297 RCM_a025_eventAccelPedalPos 1;
BA_ "GenSigSNA" SG_ 1297 RCM_a025_eventAccelPedalPos "255";
BA_ "Confidence" SG_ 1297 RCM_a026_eventArmStatus 1;
BA_ "Confidence" SG_ 1297 RCM_a026_eventFactoryMode 1;
BA_ "Confidence" SG_ 1297 RCM_a026_eventDiagEnabled 1;
BA_ "Confidence" SG_ 1297 RCM_a026_eventDriveOrientation 1;
BA_ "Confidence" SG_ 1297 RCM_a026_eventIDFsignal 1;
BA_ "Confidence" SG_ 1297 RCM_a026_eventFrontLeftSeatbelt 1;
BA_ "Confidence" SG_ 1297 RCM_a026_eventFrontRightSeatbelt 1;
BA_ "Confidence" SG_ 1297 RCM_a026_eventVehicleSpeed 1;
BA_ "Confidence" SG_ 1297 RCM_a026_eventSteeringAngle 1;
BA_ "Confidence" SG_ 1297 RCM_a026_eventDriverBrakeApply 1;
BA_ "GenSigSNA" SG_ 1297 RCM_a026_eventDriverBrakeApply "3";
BA_ "Confidence" SG_ 1297 RCM_a026_eventAccelPedalPos 1;
BA_ "GenSigSNA" SG_ 1297 RCM_a026_eventAccelPedalPos "255";
BA_ "Confidence" SG_ 1297 RCM_a027_eventArmStatus 1;
BA_ "Confidence" SG_ 1297 RCM_a027_eventFactoryMode 1;
BA_ "Confidence" SG_ 1297 RCM_a027_eventDiagEnabled 1;
BA_ "Confidence" SG_ 1297 RCM_a027_eventDriveOrientation 1;
BA_ "Confidence" SG_ 1297 RCM_a027_eventIDFsignal 1;
BA_ "Confidence" SG_ 1297 RCM_a027_eventFrontLeftSeatbelt 1;
BA_ "Confidence" SG_ 1297 RCM_a027_eventFrontRightSeatbelt 1;
BA_ "Confidence" SG_ 1297 RCM_a027_eventVehicleSpeed 1;
BA_ "Confidence" SG_ 1297 RCM_a027_eventSteeringAngle 1;
BA_ "Confidence" SG_ 1297 RCM_a027_eventDriverBrakeApply 1;
BA_ "GenSigSNA" SG_ 1297 RCM_a027_eventDriverBrakeApply "3";
BA_ "Confidence" SG_ 1297 RCM_a027_eventAccelPedalPos 1;
BA_ "GenSigSNA" SG_ 1297 RCM_a027_eventAccelPedalPos "255";
BA_ "Confidence" SG_ 1297 RCM_a028_eventArmStatus 1;
BA_ "Confidence" SG_ 1297 RCM_a028_eventFactoryMode 1;
BA_ "Confidence" SG_ 1297 RCM_a028_eventDiagEnabled 1;
BA_ "Confidence" SG_ 1297 RCM_a028_eventDriveOrientation 1;
BA_ "Confidence" SG_ 1297 RCM_a028_eventIDFsignal 1;
BA_ "Confidence" SG_ 1297 RCM_a028_eventFrontLeftSeatbelt 1;
BA_ "Confidence" SG_ 1297 RCM_a028_eventFrontRightSeatbelt 1;
BA_ "Confidence" SG_ 1297 RCM_a028_eventVehicleSpeed 1;
BA_ "Confidence" SG_ 1297 RCM_a028_eventSteeringAngle 1;
BA_ "Confidence" SG_ 1297 RCM_a028_eventDriverBrakeApply 1;
BA_ "GenSigSNA" SG_ 1297 RCM_a028_eventDriverBrakeApply "3";
BA_ "Confidence" SG_ 1297 RCM_a028_eventAccelPedalPos 1;
BA_ "GenSigSNA" SG_ 1297 RCM_a028_eventAccelPedalPos "255";
BA_ "Confidence" SG_ 1297 RCM_a029_eventArmStatus 1;
BA_ "Confidence" SG_ 1297 RCM_a029_eventFactoryMode 1;
BA_ "Confidence" SG_ 1297 RCM_a029_eventDiagEnabled 1;
BA_ "Confidence" SG_ 1297 RCM_a029_eventDriveOrientation 1;
BA_ "Confidence" SG_ 1297 RCM_a029_eventIDFsignal 1;
BA_ "Confidence" SG_ 1297 RCM_a029_eventFrontLeftSeatbelt 1;
BA_ "Confidence" SG_ 1297 RCM_a029_eventFrontRightSeatbelt 1;
BA_ "Confidence" SG_ 1297 RCM_a029_eventVehicleSpeed 1;
BA_ "Confidence" SG_ 1297 RCM_a029_eventSteeringAngle 1;
BA_ "Confidence" SG_ 1297 RCM_a029_eventDriverBrakeApply 1;
BA_ "GenSigSNA" SG_ 1297 RCM_a029_eventDriverBrakeApply "3";
BA_ "Confidence" SG_ 1297 RCM_a029_eventAccelPedalPos 1;
BA_ "GenSigSNA" SG_ 1297 RCM_a029_eventAccelPedalPos "255";
BA_ "Confidence" SG_ 1297 RCM_a030_eventArmStatus 1;
BA_ "Confidence" SG_ 1297 RCM_a030_eventFactoryMode 1;
BA_ "Confidence" SG_ 1297 RCM_a030_eventDiagEnabled 1;
BA_ "Confidence" SG_ 1297 RCM_a030_eventDriveOrientation 1;
BA_ "Confidence" SG_ 1297 RCM_a030_eventIDFsignal 1;
BA_ "Confidence" SG_ 1297 RCM_a030_eventFrontLeftSeatbelt 1;
BA_ "Confidence" SG_ 1297 RCM_a030_eventFrontRightSeatbelt 1;
BA_ "Confidence" SG_ 1297 RCM_a030_eventVehicleSpeed 1;
BA_ "Confidence" SG_ 1297 RCM_a030_eventSteeringAngle 1;
BA_ "Confidence" SG_ 1297 RCM_a030_eventDriverBrakeApply 1;
BA_ "GenSigSNA" SG_ 1297 RCM_a030_eventDriverBrakeApply "3";
BA_ "Confidence" SG_ 1297 RCM_a030_eventAccelPedalPos 1;
BA_ "GenSigSNA" SG_ 1297 RCM_a030_eventAccelPedalPos "255";
BA_ "Confidence" SG_ 1297 RCM_a031_eventArmStatus 1;
BA_ "Confidence" SG_ 1297 RCM_a031_eventFactoryMode 1;
BA_ "Confidence" SG_ 1297 RCM_a031_eventDiagEnabled 1;
BA_ "Confidence" SG_ 1297 RCM_a031_eventDriveOrientation 1;
BA_ "Confidence" SG_ 1297 RCM_a031_eventIDFsignal 1;
BA_ "Confidence" SG_ 1297 RCM_a031_eventFrontLeftSeatbelt 1;
BA_ "Confidence" SG_ 1297 RCM_a031_eventFrontRightSeatbelt 1;
BA_ "Confidence" SG_ 1297 RCM_a031_eventVehicleSpeed 1;
BA_ "Confidence" SG_ 1297 RCM_a031_eventSteeringAngle 1;
BA_ "Confidence" SG_ 1297 RCM_a031_eventDriverBrakeApply 1;
BA_ "GenSigSNA" SG_ 1297 RCM_a031_eventDriverBrakeApply "3";
BA_ "Confidence" SG_ 1297 RCM_a031_eventAccelPedalPos 1;
BA_ "GenSigSNA" SG_ 1297 RCM_a031_eventAccelPedalPos "255";
BA_ "Confidence" SG_ 1297 RCM_a032_eventArmStatus 1;
BA_ "Confidence" SG_ 1297 RCM_a032_eventFactoryMode 1;
BA_ "Confidence" SG_ 1297 RCM_a032_eventDiagEnabled 1;
BA_ "Confidence" SG_ 1297 RCM_a032_eventDriveOrientation 1;
BA_ "Confidence" SG_ 1297 RCM_a032_eventIDFsignal 1;
BA_ "Confidence" SG_ 1297 RCM_a032_eventFrontLeftSeatbelt 1;
BA_ "Confidence" SG_ 1297 RCM_a032_eventFrontRightSeatbelt 1;
BA_ "Confidence" SG_ 1297 RCM_a032_eventVehicleSpeed 1;
BA_ "Confidence" SG_ 1297 RCM_a032_eventSteeringAngle 1;
BA_ "Confidence" SG_ 1297 RCM_a032_eventDriverBrakeApply 1;
BA_ "GenSigSNA" SG_ 1297 RCM_a032_eventDriverBrakeApply "3";
BA_ "Confidence" SG_ 1297 RCM_a032_eventAccelPedalPos 1;
BA_ "GenSigSNA" SG_ 1297 RCM_a032_eventAccelPedalPos "255";
BA_ "Confidence" SG_ 1297 RCM_a033_eventArmStatus 1;
BA_ "Confidence" SG_ 1297 RCM_a033_eventFactoryMode 1;
BA_ "Confidence" SG_ 1297 RCM_a033_eventDiagEnabled 1;
BA_ "Confidence" SG_ 1297 RCM_a033_eventDriveOrientation 1;
BA_ "Confidence" SG_ 1297 RCM_a033_eventIDFsignal 1;
BA_ "Confidence" SG_ 1297 RCM_a033_eventFrontLeftSeatbelt 1;
BA_ "Confidence" SG_ 1297 RCM_a033_eventFrontRightSeatbelt 1;
BA_ "Confidence" SG_ 1297 RCM_a033_eventVehicleSpeed 1;
BA_ "Confidence" SG_ 1297 RCM_a033_eventSteeringAngle 1;
BA_ "Confidence" SG_ 1297 RCM_a033_eventDriverBrakeApply 1;
BA_ "GenSigSNA" SG_ 1297 RCM_a033_eventDriverBrakeApply "3";
BA_ "Confidence" SG_ 1297 RCM_a033_eventAccelPedalPos 1;
BA_ "GenSigSNA" SG_ 1297 RCM_a033_eventAccelPedalPos "255";
BA_ "Confidence" SG_ 1297 RCM_a034_eventArmStatus 1;
BA_ "Confidence" SG_ 1297 RCM_a034_eventFactoryMode 1;
BA_ "Confidence" SG_ 1297 RCM_a034_eventDiagEnabled 1;
BA_ "Confidence" SG_ 1297 RCM_a034_eventDriveOrientation 1;
BA_ "Confidence" SG_ 1297 RCM_a034_eventIDFsignal 1;
BA_ "Confidence" SG_ 1297 RCM_a034_eventFrontLeftSeatbelt 1;
BA_ "Confidence" SG_ 1297 RCM_a034_eventFrontRightSeatbelt 1;
BA_ "Confidence" SG_ 1297 RCM_a034_eventVehicleSpeed 1;
BA_ "Confidence" SG_ 1297 RCM_a034_eventSteeringAngle 1;
BA_ "Confidence" SG_ 1297 RCM_a034_eventDriverBrakeApply 1;
BA_ "GenSigSNA" SG_ 1297 RCM_a034_eventDriverBrakeApply "3";
BA_ "Confidence" SG_ 1297 RCM_a034_eventAccelPedalPos 1;
BA_ "GenSigSNA" SG_ 1297 RCM_a034_eventAccelPedalPos "255";
BA_ "Confidence" SG_ 1297 RCM_a035_eventArmStatus 1;
BA_ "Confidence" SG_ 1297 RCM_a035_eventFactoryMode 1;
BA_ "Confidence" SG_ 1297 RCM_a035_eventDiagEnabled 1;
BA_ "Confidence" SG_ 1297 RCM_a035_eventDriveOrientation 1;
BA_ "Confidence" SG_ 1297 RCM_a035_eventIDFsignal 1;
BA_ "Confidence" SG_ 1297 RCM_a035_eventFrontLeftSeatbelt 1;
BA_ "Confidence" SG_ 1297 RCM_a035_eventFrontRightSeatbelt 1;
BA_ "Confidence" SG_ 1297 RCM_a035_eventVehicleSpeed 1;
BA_ "Confidence" SG_ 1297 RCM_a035_eventSteeringAngle 1;
BA_ "Confidence" SG_ 1297 RCM_a035_eventDriverBrakeApply 1;
BA_ "GenSigSNA" SG_ 1297 RCM_a035_eventDriverBrakeApply "3";
BA_ "Confidence" SG_ 1297 RCM_a035_eventAccelPedalPos 1;
BA_ "GenSigSNA" SG_ 1297 RCM_a035_eventAccelPedalPos "255";
BA_ "Confidence" SG_ 1297 RCM_a036_eventArmStatus 1;
BA_ "Confidence" SG_ 1297 RCM_a036_eventFactoryMode 1;
BA_ "Confidence" SG_ 1297 RCM_a036_eventDiagEnabled 1;
BA_ "Confidence" SG_ 1297 RCM_a036_eventDriveOrientation 1;
BA_ "Confidence" SG_ 1297 RCM_a036_eventIDFsignal 1;
BA_ "Confidence" SG_ 1297 RCM_a036_eventFrontLeftSeatbelt 1;
BA_ "Confidence" SG_ 1297 RCM_a036_eventFrontRightSeatbelt 1;
BA_ "Confidence" SG_ 1297 RCM_a036_eventVehicleSpeed 1;
BA_ "Confidence" SG_ 1297 RCM_a036_eventSteeringAngle 1;
BA_ "Confidence" SG_ 1297 RCM_a036_eventDriverBrakeApply 1;
BA_ "GenSigSNA" SG_ 1297 RCM_a036_eventDriverBrakeApply "3";
BA_ "Confidence" SG_ 1297 RCM_a036_eventAccelPedalPos 1;
BA_ "GenSigSNA" SG_ 1297 RCM_a036_eventAccelPedalPos "255";
BA_ "Confidence" SG_ 1297 RCM_a037_eventArmStatus 1;
BA_ "Confidence" SG_ 1297 RCM_a037_eventFactoryMode 1;
BA_ "Confidence" SG_ 1297 RCM_a037_eventDiagEnabled 1;
BA_ "Confidence" SG_ 1297 RCM_a037_eventDriveOrientation 1;
BA_ "Confidence" SG_ 1297 RCM_a037_eventIDFsignal 1;
BA_ "Confidence" SG_ 1297 RCM_a037_eventFrontLeftSeatbelt 1;
BA_ "Confidence" SG_ 1297 RCM_a037_eventFrontRightSeatbelt 1;
BA_ "Confidence" SG_ 1297 RCM_a037_eventVehicleSpeed 1;
BA_ "Confidence" SG_ 1297 RCM_a037_eventSteeringAngle 1;
BA_ "Confidence" SG_ 1297 RCM_a037_eventDriverBrakeApply 1;
BA_ "GenSigSNA" SG_ 1297 RCM_a037_eventDriverBrakeApply "3";
BA_ "Confidence" SG_ 1297 RCM_a037_eventAccelPedalPos 1;
BA_ "GenSigSNA" SG_ 1297 RCM_a037_eventAccelPedalPos "255";
BA_ "Confidence" SG_ 1297 RCM_a040_eventArmStatus 1;
BA_ "Confidence" SG_ 1297 RCM_a040_eventFactoryMode 1;
BA_ "Confidence" SG_ 1297 RCM_a040_eventDiagEnabled 1;
BA_ "Confidence" SG_ 1297 RCM_a040_eventDriveOrientation 1;
BA_ "Confidence" SG_ 1297 RCM_a040_eventIDFsignal 1;
BA_ "Confidence" SG_ 1297 RCM_a040_eventFrontLeftSeatbelt 1;
BA_ "Confidence" SG_ 1297 RCM_a040_eventFrontRightSeatbelt 1;
BA_ "Confidence" SG_ 1297 RCM_a040_eventVehicleSpeed 1;
BA_ "Confidence" SG_ 1297 RCM_a040_eventSteeringAngle 1;
BA_ "Confidence" SG_ 1297 RCM_a040_eventDriverBrakeApply 1;
BA_ "GenSigSNA" SG_ 1297 RCM_a040_eventDriverBrakeApply "3";
BA_ "Confidence" SG_ 1297 RCM_a040_eventAccelPedalPos 1;
BA_ "GenSigSNA" SG_ 1297 RCM_a040_eventAccelPedalPos "255";
BA_ "Confidence" SG_ 1297 RCM_a041_eventArmStatus 1;
BA_ "Confidence" SG_ 1297 RCM_a041_eventFactoryMode 1;
BA_ "Confidence" SG_ 1297 RCM_a041_eventDiagEnabled 1;
BA_ "Confidence" SG_ 1297 RCM_a041_eventDriveOrientation 1;
BA_ "Confidence" SG_ 1297 RCM_a041_eventIDFsignal 1;
BA_ "Confidence" SG_ 1297 RCM_a041_eventFrontLeftSeatbelt 1;
BA_ "Confidence" SG_ 1297 RCM_a041_eventFrontRightSeatbelt 1;
BA_ "Confidence" SG_ 1297 RCM_a041_eventVehicleSpeed 1;
BA_ "Confidence" SG_ 1297 RCM_a041_eventSteeringAngle 1;
BA_ "Confidence" SG_ 1297 RCM_a041_eventDriverBrakeApply 1;
BA_ "GenSigSNA" SG_ 1297 RCM_a041_eventDriverBrakeApply "3";
BA_ "Confidence" SG_ 1297 RCM_a041_eventAccelPedalPos 1;
BA_ "GenSigSNA" SG_ 1297 RCM_a041_eventAccelPedalPos "255";
BA_ "Confidence" SG_ 1297 RCM_a042_eventArmStatus 1;
BA_ "Confidence" SG_ 1297 RCM_a042_eventFactoryMode 1;
BA_ "Confidence" SG_ 1297 RCM_a042_eventDiagEnabled 1;
BA_ "Confidence" SG_ 1297 RCM_a042_eventDriveOrientation 1;
BA_ "Confidence" SG_ 1297 RCM_a042_eventIDFsignal 1;
BA_ "Confidence" SG_ 1297 RCM_a042_eventFrontLeftSeatbelt 1;
BA_ "Confidence" SG_ 1297 RCM_a042_eventFrontRightSeatbelt 1;
BA_ "Confidence" SG_ 1297 RCM_a042_eventVehicleSpeed 1;
BA_ "Confidence" SG_ 1297 RCM_a042_eventSteeringAngle 1;
BA_ "Confidence" SG_ 1297 RCM_a042_eventDriverBrakeApply 1;
BA_ "GenSigSNA" SG_ 1297 RCM_a042_eventDriverBrakeApply "3";
BA_ "Confidence" SG_ 1297 RCM_a042_eventAccelPedalPos 1;
BA_ "GenSigSNA" SG_ 1297 RCM_a042_eventAccelPedalPos "255";
BA_ "Confidence" SG_ 1297 RCM_a043_eventArmStatus 1;
BA_ "Confidence" SG_ 1297 RCM_a043_eventFactoryMode 1;
BA_ "Confidence" SG_ 1297 RCM_a043_eventDiagEnabled 1;
BA_ "Confidence" SG_ 1297 RCM_a043_eventDriveOrientation 1;
BA_ "Confidence" SG_ 1297 RCM_a043_eventIDFsignal 1;
BA_ "Confidence" SG_ 1297 RCM_a043_eventFrontLeftSeatbelt 1;
BA_ "Confidence" SG_ 1297 RCM_a043_eventFrontRightSeatbelt 1;
BA_ "Confidence" SG_ 1297 RCM_a043_eventVehicleSpeed 1;
BA_ "Confidence" SG_ 1297 RCM_a043_eventSteeringAngle 1;
BA_ "Confidence" SG_ 1297 RCM_a043_eventDriverBrakeApply 1;
BA_ "GenSigSNA" SG_ 1297 RCM_a043_eventDriverBrakeApply "3";
BA_ "Confidence" SG_ 1297 RCM_a043_eventAccelPedalPos 1;
BA_ "GenSigSNA" SG_ 1297 RCM_a043_eventAccelPedalPos "255";
BA_ "Confidence" SG_ 1297 RCM_a044_eventArmStatus 1;
BA_ "Confidence" SG_ 1297 RCM_a044_eventFactoryMode 1;
BA_ "Confidence" SG_ 1297 RCM_a044_eventDiagEnabled 1;
BA_ "Confidence" SG_ 1297 RCM_a044_eventDriveOrientation 1;
BA_ "Confidence" SG_ 1297 RCM_a044_eventIDFsignal 1;
BA_ "Confidence" SG_ 1297 RCM_a044_eventFrontLeftSeatbelt 1;
BA_ "Confidence" SG_ 1297 RCM_a044_eventFrontRightSeatbelt 1;
BA_ "Confidence" SG_ 1297 RCM_a044_eventVehicleSpeed 1;
BA_ "Confidence" SG_ 1297 RCM_a044_eventSteeringAngle 1;
BA_ "Confidence" SG_ 1297 RCM_a044_eventDriverBrakeApply 1;
BA_ "GenSigSNA" SG_ 1297 RCM_a044_eventDriverBrakeApply "3";
BA_ "Confidence" SG_ 1297 RCM_a044_eventAccelPedalPos 1;
BA_ "GenSigSNA" SG_ 1297 RCM_a044_eventAccelPedalPos "255";
BA_ "Confidence" SG_ 1297 RCM_a045_eventArmStatus 1;
BA_ "Confidence" SG_ 1297 RCM_a045_eventFactoryMode 1;
BA_ "Confidence" SG_ 1297 RCM_a045_eventDiagEnabled 1;
BA_ "Confidence" SG_ 1297 RCM_a045_eventDriveOrientation 1;
BA_ "Confidence" SG_ 1297 RCM_a045_eventIDFsignal 1;
BA_ "Confidence" SG_ 1297 RCM_a045_eventFrontLeftSeatbelt 1;
VAL_ 463 PM_torqueCheckState 4 "CANNOT_POLICE_AT_ALL" 3 "CANNOT_POLICE_MEASUREMENT" 2 "CANNOT_POLICE_COMMAND" 1 "POLICING" 0 "START" ;
VAL_ 463 PM_limpRequest 2 "SYSTEM" 1 "UNIT" 0 "OK" ;
VAL_ 463 PM_torqueCommand -4096 "SNA" ;
VAL_ 463 PM_torqueState 2 "INHIBITED" 1 "DISALLOWED" 0 "ALLOWED" ;
VAL_ 463 PM_hvilSystemStatus 3 "SNA" 2 "CLOSED" 1 "OPEN" 0 "DISABLED" ;
VAL_ 463 PM_sysElecPower -1024 "SNA" ;
VAL_ 519 PTC_leftPowerDerating 3 "OVERTEMPERATURE_CORE" 2 "OVERTEMPERATURE_IGBT" 1 "OVERTEMPERATURE_PCB" 0 "NOT_DERATED" ;
VAL_ 519 PTC_rightPowerDerating 3 "OVERTEMPERATURE_CORE" 2 "OVERTEMPERATURE_IGBT" 1 "OVERTEMPERATURE_PCB" 0 "NOT_DERATED" ;
VAL_ 519 PTC_ocpEvent 2 "OCP_EVENT_RIGHT_SIDE" 1 "OCP_EVENT_LEFT_SIDE" 0 "NO_OCP_EVENT" ;
VAL_ 519 PTC_tliSource 4 "HV_OVER_VOLTAGE" 3 "OCP" 2 "12_VOLTS" 1 "IGBT_DRIVER" 0 "NO_ERROR" ;
VAL_ 1297 RCM_alertID 118 "a118_imuInPlaneAcceleration" 117 "a117_imuVerticalAcceleration" 116 "a116_imuLateralAcceleration" 115 "a115_imuLinearAcceleration" 114 "a114_imuRollRate" 113 "a113_imuPitchRate" 112 "a112_imuYawRate" 111 "a111_diagnosticsEnabled" 110 "a110_factoryMode" 109 "a109_abuseImmunity" 108 "a108_crashAlgoWakeup" 107 "a107_imuVertAccOffstCompLim" 106 "a106_imuLatAccOffstCompLim" 105 "a105_imuLongAccOffstCompLim" 104 "a104_imuRollR8OffstCompLim" 103 "a103_imuPtchR8OffstCompLim" 102 "a102_imuYawR8OffstCompLim" 101 "a101_idfSystem" 100 "a100_comDIsystemStatus" 99 "a099_comDItorque" 98 "a098_comDIchassisControl" 97 "a097_comDIspeed" 96 "a096_comESPwheelSpeeds" 95 "a095_comESPstatus" 94 "a094_comVCRIGHTStatus" 93 "a093_comVCLEFTStatus" 92 "a092_comDASISF" 91 "a091_comEPAS3PsysStatus" 90 "a090_comPartyBusOff" 89 "a089_comCHCANPH3" 88 "a088_comCHCANPH2" 87 "a087_comCANSilent" 86 "a086_comVINMIA" 85 "a085_comGTWCarConfig" 84 "a084_comTPMSStatus" 83 "a083_comGTWCarState" 82 "a082_comUIodo" 81 "a081_comVCFRONTLVPwr" 80 "a080_comGTWACS" 79 "a079_comOCS1DStatus" 78 "a078_comOCS1PStatus" 77 "a077_comEPBRStatus" 76 "a076_comEPBLStatus" 75 "a075_comCHCANPH6" 74 "a074_comCHCANPH5" 73 "a073_comCHCANPH4" 72 "a072_comUnused" 71 "a071_comCHCANPH9" 70 "a070_comCHCANPH8" 69 "a069_comCHCANPH7" 68 "a068_comChassisBusOff" 67 "a067_comCANInitFailure" 66 "a066_seatBackSw2ndRowLeft" 65 "a065_driverOrientConfigPin" 64 "a064_hardwareCodingPin1" 63 "a063_sbsw2ndRowRight" 62 "a062_alrSwitch" 61 "a061_stpsRight" 60 "a060_stpsLeft" 59 "a059_buckle1stRowRight" 58 "a058_buckle1stRowLeft" 57 "a057_driverOCS" 56 "a056_passengerFrontOCS" 55 "a055_inertialMeasurement" 54 "a054_pressurePedProRight" 53 "a053_pressurePedProLeft" 52 "a052_pressureFrontRtDoor" 51 "a051_pressureFrontLftDoor" 50 "a050_upFrontSensorCenter" 49 "a049_sideAccelCPillarRight" 48 "a048_sideAccelCPillarLeft" 47 "a047_sideAccelBPillarRight" 46 "a046_sideAccelBPillarLeft" 45 "a045_upFrontSensorRight" 44 "a044_upFrontSensorLeft" 43 "a043_ens2Line" 42 "a042_ens1Line" 41 "a041_hoodActuatorLeft" 40 "a040_hoodActuatorRight" 39 "a039_unusedB" 38 "a038_unusedA" 37 "a037_curAB2ndRowRight" 36 "a036_curAB2ndRowLeft" 35 "a035_preten2ndRowRight" 34 "a034_preten2ndRowLeft" 33 "a033_curtainABRight" 32 "a032_curtainABLeft" 31 "a031_frontCenterAirbag" 30 "a030_farSideInboardAirbag" 29 "a029_driverABActiveVent" 28 "a028_sideAB1stRowRight" 27 "a027_sideAB1stRowLeft" 26 "a026_kneeABFrontPassenger" 25 "a025_kneeABDriver" 24 "a024_loadLimiterRightSide" 23 "a023_loadLimiterLeftSide" 22 "a022_pretenLapFrontRight" 21 "a021_pretenLapFrontLeft" 20 "a020_pretenShldFrontRight" 19 "a019_pretenShldrFrontLeft" 18 "a018_passengerActiveVent" 17 "a017_passABStage2" 16 "a016_passABStage1" 15 "a015_driverABStage2" 14 "a014_driverABStage1" 13 "a013_driverOrientation" 12 "a012_vinStorage" 11 "a011_eepromDataLocked" 10 "a010_scmDisabled" 9 "a009_reprogramLimit" 8 "a008_powerSupplyInternal" 7 "a007_powerSupplyExternal" 6 "a006_batteryVoltageRange" 5 "a005_crcError" 4 "a004_internalFault" 3 "a003_warningIndicator" 2 "a002_airbagsNotArmed" 1 "a001_nearDeploy" 0 "a000_crashDetected" ;
VAL_ 1297 RCM_alertState 1 "SET" 0 "CLEARED" ;
VAL_ 1297 RCM_a000_eventArmStatus 1 "ARMED" 0 "UNARMED" ;
VAL_ 1297 RCM_a000_eventFactoryMode 1 "ENABLED" 0 "DISABLED" ;
VAL_ 1297 RCM_a000_eventDiagEnabled 1 "ENABLED" 0 "DISABLED" ;
VAL_ 1297 RCM_a000_eventDriveOrientation 1 "RIGHT_HAND_DRIVE" 0 "LEFT_HAND_DRIVE" ;
VAL_ 1297 RCM_a000_eventIDFsignal 1 "ACTIVE" 0 "NOT_ACTIVE" ;
VAL_ 1297 RCM_a000_eventFrontLeftSeatbelt 1 "LATCHED" 0 "UNLATCHED" ;
VAL_ 1297 RCM_a000_eventFrontRightSeatbelt 1 "LATCHED" 0 "UNLATCHED" ;
VAL_ 1297 RCM_a000_eventDriverBrakeApply 3 "Faulty_SNA" 2 "Driver_applying_brakes" 1 "Not_Applied" 0 "NotInit_orOff" ;
VAL_ 1297 RCM_a000_eventAccelPedalPos 255 "SNA" ;
VAL_ 1297 RCM_a001_eventArmStatus 1 "ARMED" 0 "UNARMED" ;
VAL_ 1297 RCM_a001_eventFactoryMode 1 "ENABLED" 0 "DISABLED" ;
VAL_ 1297 RCM_a001_eventDiagEnabled 1 "ENABLED" 0 "DISABLED" ;
VAL_ 1297 RCM_a001_eventDriveOrientation 1 "RIGHT_HAND_DRIVE" 0 "LEFT_HAND_DRIVE" ;
VAL_ 1297 RCM_a001_eventIDFsignal 1 "ACTIVE" 0 "NOT_ACTIVE" ;
VAL_ 1297 RCM_a001_eventFrontLeftSeatbelt 1 "LATCHED" 0 "UNLATCHED" ;
VAL_ 1297 RCM_a001_eventFrontRightSeatbelt 1 "LATCHED" 0 "UNLATCHED" ;
VAL_ 1297 RCM_a001_eventDriverBrakeApply 3 "Faulty_SNA" 2 "Driver_applying_brakes" 1 "Not_Applied" 0 "NotInit_orOff" ;
VAL_ 1297 RCM_a001_eventAccelPedalPos 255 "SNA" ;
VAL_ 1297 RCM_a002_eventArmStatus 1 "ARMED" 0 "UNARMED" ;
VAL_ 1297 RCM_a002_eventFactoryMode 1 "ENABLED" 0 "DISABLED" ;
VAL_ 1297 RCM_a002_eventDiagEnabled 1 "ENABLED" 0 "DISABLED" ;
VAL_ 1297 RCM_a002_eventDriveOrientation 1 "RIGHT_HAND_DRIVE" 0 "LEFT_HAND_DRIVE" ;
VAL_ 1297 RCM_a002_eventIDFsignal 1 "ACTIVE" 0 "NOT_ACTIVE" ;
VAL_ 1297 RCM_a002_eventFrontLeftSeatbelt 1 "LATCHED" 0 "UNLATCHED" ;
VAL_ 1297 RCM_a002_eventFrontRightSeatbelt 1 "LATCHED" 0 "UNLATCHED" ;
VAL_ 1297 RCM_a002_eventDriverBrakeApply 3 "Faulty_SNA" 2 "Driver_applying_brakes" 1 "Not_Applied" 0 "NotInit_orOff" ;
VAL_ 1297 RCM_a002_eventAccelPedalPos 255 "SNA" ;
VAL_ 1297 RCM_a003_eventArmStatus 1 "ARMED" 0 "UNARMED" ;
VAL_ 1297 RCM_a003_eventFactoryMode 1 "ENABLED" 0 "DISABLED" ;
VAL_ 1297 RCM_a003_eventDiagEnabled 1 "ENABLED" 0 "DISABLED" ;
VAL_ 1297 RCM_a003_eventDriveOrientation 1 "RIGHT_HAND_DRIVE" 0 "LEFT_HAND_DRIVE" ;
VAL_ 1297 RCM_a003_eventIDFsignal 1 "ACTIVE" 0 "NOT_ACTIVE" ;
VAL_ 1297 RCM_a003_eventFrontLeftSeatbelt 1 "LATCHED" 0 "UNLATCHED" ;
VAL_ 1297 RCM_a003_eventFrontRightSeatbelt 1 "LATCHED" 0 "UNLATCHED" ;
VAL_ 1297 RCM_a003_eventDriverBrakeApply 3 "Faulty_SNA" 2 "Driver_applying_brakes" 1 "Not_Applied" 0 "NotInit_orOff" ;
VAL_ 1297 RCM_a003_eventAccelPedalPos 255 "SNA" ;
VAL_ 1297 RCM_a004_eventArmStatus 1 "ARMED" 0 "UNARMED" ;
VAL_ 1297 RCM_a004_eventFactoryMode 1 "ENABLED" 0 "DISABLED" ;
VAL_ 1297 RCM_a004_eventDiagEnabled 1 "ENABLED" 0 "DISABLED" ;
VAL_ 1297 RCM_a004_eventDriveOrientation 1 "RIGHT_HAND_DRIVE" 0 "LEFT_HAND_DRIVE" ;
VAL_ 1297 RCM_a004_eventIDFsignal 1 "ACTIVE" 0 "NOT_ACTIVE" ;
VAL_ 1297 RCM_a004_eventFrontLeftSeatbelt 1 "LATCHED" 0 "UNLATCHED" ;
VAL_ 1297 RCM_a004_eventFrontRightSeatbelt 1 "LATCHED" 0 "UNLATCHED" ;
VAL_ 1297 RCM_a004_eventDriverBrakeApply 3 "Faulty_SNA" 2 "Driver_applying_brakes" 1 "Not_Applied" 0 "NotInit_orOff" ;
VAL_ 1297 RCM_a004_eventAccelPedalPos 255 "SNA" ;
VAL_ 1297 RCM_a005_eventArmStatus 1 "ARMED" 0 "UNARMED" ;
VAL_ 1297 RCM_a005_eventFactoryMode 1 "ENABLED" 0 "DISABLED" ;
VAL_ 1297 RCM_a005_eventDiagEnabled 1 "ENABLED" 0 "DISABLED" ;
VAL_ 1297 RCM_a005_eventDriveOrientation 1 "RIGHT_HAND_DRIVE" 0 "LEFT_HAND_DRIVE" ;
VAL_ 1297 RCM_a005_eventIDFsignal 1 "ACTIVE" 0 "NOT_ACTIVE" ;
VAL_ 1297 RCM_a005_eventFrontLeftSeatbelt 1 "LATCHED" 0 "UNLATCHED" ;
VAL_ 1297 RCM_a005_eventFrontRightSeatbelt 1 "LATCHED" 0 "UNLATCHED" ;
VAL_ 1297 RCM_a005_eventDriverBrakeApply 3 "Faulty_SNA" 2 "Driver_applying_brakes" 1 "Not_Applied" 0 "NotInit_orOff" ;
VAL_ 1297 RCM_a005_eventAccelPedalPos 255 "SNA" ;
VAL_ 1297 RCM_a006_eventArmStatus 1 "ARMED" 0 "UNARMED" ;
VAL_ 1297 RCM_a006_eventFactoryMode 1 "ENABLED" 0 "DISABLED" ;
VAL_ 1297 RCM_a006_eventDiagEnabled 1 "ENABLED" 0 "DISABLED" ;
VAL_ 1297 RCM_a006_eventDriveOrientation 1 "RIGHT_HAND_DRIVE" 0 "LEFT_HAND_DRIVE" ;
VAL_ 1297 RCM_a006_eventIDFsignal 1 "ACTIVE" 0 "NOT_ACTIVE" ;
VAL_ 1297 RCM_a006_eventFrontLeftSeatbelt 1 "LATCHED" 0 "UNLATCHED" ;
VAL_ 1297 RCM_a006_eventFrontRightSeatbelt 1 "LATCHED" 0 "UNLATCHED" ;
VAL_ 1297 RCM_a006_eventDriverBrakeApply 3 "Faulty_SNA" 2 "Driver_applying_brakes" 1 "Not_Applied" 0 "NotInit_orOff" ;
VAL_ 1297 RCM_a006_eventAccelPedalPos 255 "SNA" ;
VAL_ 1297 RCM_a008_eventArmStatus 1 "ARMED" 0 "UNARMED" ;
VAL_ 1297 RCM_a008_eventFactoryMode 1 "ENABLED" 0 "DISABLED" ;
VAL_ 1297 RCM_a008_eventDiagEnabled 1 "ENABLED" 0 "DISABLED" ;
VAL_ 1297 RCM_a008_eventDriveOrientation 1 "RIGHT_HAND_DRIVE" 0 "LEFT_HAND_DRIVE" ;
VAL_ 1297 RCM_a008_eventIDFsignal 1 "ACTIVE" 0 "NOT_ACTIVE" ;
VAL_ 1297 RCM_a008_eventFrontLeftSeatbelt 1 "LATCHED" 0 "UNLATCHED" ;
VAL_ 1297 RCM_a008_eventFrontRightSeatbelt 1 "LATCHED" 0 "UNLATCHED" ;
VAL_ 1297 RCM_a008_eventDriverBrakeApply 3 "Faulty_SNA" 2 "Driver_applying_brakes" 1 "Not_Applied" 0 "NotInit_orOff" ;
VAL_ 1297 RCM_a008_eventAccelPedalPos 255 "SNA" ;
VAL_ 1297 RCM_a009_eventArmStatus 1 "ARMED" 0 "UNARMED" ;
VAL_ 1297 RCM_a009_eventFactoryMode 1 "ENABLED" 0 "DISABLED" ;
VAL_ 1297 RCM_a009_eventDiagEnabled 1 "ENABLED" 0 "DISABLED" ;
VAL_ 1297 RCM_a009_eventDriveOrientation 1 "RIGHT_HAND_DRIVE" 0 "LEFT_HAND_DRIVE" ;
VAL_ 1297 RCM_a009_eventIDFsignal 1 "ACTIVE" 0 "NOT_ACTIVE" ;
VAL_ 1297 RCM_a009_eventFrontLeftSeatbelt 1 "LATCHED" 0 "UNLATCHED" ;
VAL_ 1297 RCM_a009_eventFrontRightSeatbelt 1 "LATCHED" 0 "UNLATCHED" ;
VAL_ 1297 RCM_a009_eventDriverBrakeApply 3 "Faulty_SNA" 2 "Driver_applying_brakes" 1 "Not_Applied" 0 "NotInit_orOff" ;
VAL_ 1297 RCM_a009_eventAccelPedalPos 255 "SNA" ;
VAL_ 1297 RCM_a011_eventArmStatus 1 "ARMED" 0 "UNARMED" ;
VAL_ 1297 RCM_a011_eventFactoryMode 1 "ENABLED" 0 "DISABLED" ;
VAL_ 1297 RCM_a011_eventDiagEnabled 1 "ENABLED" 0 "DISABLED" ;
VAL_ 1297 RCM_a011_eventDriveOrientation 1 "RIGHT_HAND_DRIVE" 0 "LEFT_HAND_DRIVE" ;
VAL_ 1297 RCM_a011_eventIDFsignal 1 "ACTIVE" 0 "NOT_ACTIVE" ;
VAL_ 1297 RCM_a011_eventFrontLeftSeatbelt 1 "LATCHED" 0 "UNLATCHED" ;
VAL_ 1297 RCM_a011_eventFrontRightSeatbelt 1 "LATCHED" 0 "UNLATCHED" ;
VAL_ 1297 RCM_a011_eventDriverBrakeApply 3 "Faulty_SNA" 2 "Driver_applying_brakes" 1 "Not_Applied" 0 "NotInit_orOff" ;
VAL_ 1297 RCM_a011_eventAccelPedalPos 255 "SNA" ;
VAL_ 1297 RCM_a012_eventArmStatus 1 "ARMED" 0 "UNARMED" ;
VAL_ 1297 RCM_a012_eventFactoryMode 1 "ENABLED" 0 "DISABLED" ;
VAL_ 1297 RCM_a012_eventDiagEnabled 1 "ENABLED" 0 "DISABLED" ;
VAL_ 1297 RCM_a012_eventDriveOrientation 1 "RIGHT_HAND_DRIVE" 0 "LEFT_HAND_DRIVE" ;
VAL_ 1297 RCM_a012_eventIDFsignal 1 "ACTIVE" 0 "NOT_ACTIVE" ;
VAL_ 1297 RCM_a012_eventFrontLeftSeatbelt 1 "LATCHED" 0 "UNLATCHED" ;
VAL_ 1297 RCM_a012_eventFrontRightSeatbelt 1 "LATCHED" 0 "UNLATCHED" ;
VAL_ 1297 RCM_a012_eventDriverBrakeApply 3 "Faulty_SNA" 2 "Driver_applying_brakes" 1 "Not_Applied" 0 "NotInit_orOff" ;
VAL_ 1297 RCM_a012_eventAccelPedalPos 255 "SNA" ;
VAL_ 1297 RCM_a013_eventArmStatus 1 "ARMED" 0 "UNARMED" ;
VAL_ 1297 RCM_a013_eventFactoryMode 1 "ENABLED" 0 "DISABLED" ;
VAL_ 1297 RCM_a013_eventDiagEnabled 1 "ENABLED" 0 "DISABLED" ;
VAL_ 1297 RCM_a013_eventDriveOrientation 1 "RIGHT_HAND_DRIVE" 0 "LEFT_HAND_DRIVE" ;
VAL_ 1297 RCM_a013_eventIDFsignal 1 "ACTIVE" 0 "NOT_ACTIVE" ;
VAL_ 1297 RCM_a013_eventFrontLeftSeatbelt 1 "LATCHED" 0 "UNLATCHED" ;
VAL_ 1297 RCM_a013_eventFrontRightSeatbelt 1 "LATCHED" 0 "UNLATCHED" ;
VAL_ 1297 RCM_a013_eventDriverBrakeApply 3 "Faulty_SNA" 2 "Driver_applying_brakes" 1 "Not_Applied" 0 "NotInit_orOff" ;
VAL_ 1297 RCM_a013_eventAccelPedalPos 255 "SNA" ;
VAL_ 1297 RCM_a014_eventArmStatus 1 "ARMED" 0 "UNARMED" ;
VAL_ 1297 RCM_a014_eventFactoryMode 1 "ENABLED" 0 "DISABLED" ;
VAL_ 1297 RCM_a014_eventDiagEnabled 1 "ENABLED" 0 "DISABLED" ;
VAL_ 1297 RCM_a014_eventDriveOrientation 1 "RIGHT_HAND_DRIVE" 0 "LEFT_HAND_DRIVE" ;
VAL_ 1297 RCM_a014_eventIDFsignal 1 "ACTIVE" 0 "NOT_ACTIVE" ;
VAL_ 1297 RCM_a014_eventFrontLeftSeatbelt 1 "LATCHED" 0 "UNLATCHED" ;
VAL_ 1297 RCM_a014_eventFrontRightSeatbelt 1 "LATCHED" 0 "UNLATCHED" ;
VAL_ 1297 RCM_a014_eventDriverBrakeApply 3 "Faulty_SNA" 2 "Driver_applying_brakes" 1 "Not_Applied" 0 "NotInit_orOff" ;
VAL_ 1297 RCM_a014_eventAccelPedalPos 255 "SNA" ;
VAL_ 1297 RCM_a015_eventArmStatus 1 "ARMED" 0 "UNARMED" ;
VAL_ 1297 RCM_a015_eventFactoryMode 1 "ENABLED" 0 "DISABLED" ;
VAL_ 1297 RCM_a015_eventDiagEnabled 1 "ENABLED" 0 "DISABLED" ;
VAL_ 1297 RCM_a015_eventDriveOrientation 1 "RIGHT_HAND_DRIVE" 0 "LEFT_HAND_DRIVE" ;
VAL_ 1297 RCM_a015_eventIDFsignal 1 "ACTIVE" 0 "NOT_ACTIVE" ;
VAL_ 1297 RCM_a015_eventFrontLeftSeatbelt 1 "LATCHED" 0 "UNLATCHED" ;
VAL_ 1297 RCM_a015_eventFrontRightSeatbelt 1 "LATCHED" 0 "UNLATCHED" ;
VAL_ 1297 RCM_a015_eventDriverBrakeApply 3 "Faulty_SNA" 2 "Driver_applying_brakes" 1 "Not_Applied" 0 "NotInit_orOff" ;
VAL_ 1297 RCM_a015_eventAccelPedalPos 255 "SNA" ;
VAL_ 1297 RCM_a016_eventArmStatus 1 "ARMED" 0 "UNARMED" ;
VAL_ 1297 RCM_a016_eventFactoryMode 1 "ENABLED" 0 "DISABLED" ;
VAL_ 1297 RCM_a016_eventDiagEnabled 1 "ENABLED" 0 "DISABLED" ;
VAL_ 1297 RCM_a016_eventDriveOrientation 1 "RIGHT_HAND_DRIVE" 0 "LEFT_HAND_DRIVE" ;
VAL_ 1297 RCM_a016_eventIDFsignal 1 "ACTIVE" 0 "NOT_ACTIVE" ;
VAL_ 1297 RCM_a016_eventFrontLeftSeatbelt 1 "LATCHED" 0 "UNLATCHED" ;
VAL_ 1297 RCM_a016_eventFrontRightSeatbelt 1 "LATCHED" 0 "UNLATCHED" ;
VAL_ 1297 RCM_a016_eventDriverBrakeApply 3 "Faulty_SNA" 2 "Driver_applying_brakes" 1 "Not_Applied" 0 "NotInit_orOff" ;
VAL_ 1297 RCM_a016_eventAccelPedalPos 255 "SNA" ;
VAL_ 1297 RCM_a017_eventArmStatus 1 "ARMED" 0 "UNARMED" ;
VAL_ 1297 RCM_a017_eventFactoryMode 1 "ENABLED" 0 "DISABLED" ;
VAL_ 1297 RCM_a017_eventDiagEnabled 1 "ENABLED" 0 "DISABLED" ;
VAL_ 1297 RCM_a017_eventDriveOrientation 1 "RIGHT_HAND_DRIVE" 0 "LEFT_HAND_DRIVE" ;
VAL_ 1297 RCM_a017_eventIDFsignal 1 "ACTIVE" 0 "NOT_ACTIVE" ;
VAL_ 1297 RCM_a017_eventFrontLeftSeatbelt 1 "LATCHED" 0 "UNLATCHED" ;
VAL_ 1297 RCM_a017_eventFrontRightSeatbelt 1 "LATCHED" 0 "UNLATCHED" ;
VAL_ 1297 RCM_a017_eventDriverBrakeApply 3 "Faulty_SNA" 2 "Driver_applying_brakes" 1 "Not_Applied" 0 "NotInit_orOff" ;
VAL_ 1297 RCM_a017_eventAccelPedalPos 255 "SNA" ;
VAL_ 1297 RCM_a018_eventArmStatus 1 "ARMED" 0 "UNARMED" ;
VAL_ 1297 RCM_a018_eventFactoryMode 1 "ENABLED" 0 "DISABLED" ;
VAL_ 1297 RCM_a018_eventDiagEnabled 1 "ENABLED" 0 "DISABLED" ;
VAL_ 1297 RCM_a018_eventDriveOrientation 1 "RIGHT_HAND_DRIVE" 0 "LEFT_HAND_DRIVE" ;
VAL_ 1297 RCM_a018_eventIDFsignal 1 "ACTIVE" 0 "NOT_ACTIVE" ;
VAL_ 1297 RCM_a018_eventFrontLeftSeatbelt 1 "LATCHED" 0 "UNLATCHED" ;
VAL_ 1297 RCM_a018_eventFrontRightSeatbelt 1 "LATCHED" 0 "UNLATCHED" ;
VAL_ 1297 RCM_a018_eventDriverBrakeApply 3 "Faulty_SNA" 2 "Driver_applying_brakes" 1 "Not_Applied" 0 "NotInit_orOff" ;
VAL_ 1297 RCM_a018_eventAccelPedalPos 255 "SNA" ;
VAL_ 1297 RCM_a019_eventArmStatus 1 "ARMED" 0 "UNARMED" ;
VAL_ 1297 RCM_a019_eventFactoryMode 1 "ENABLED" 0 "DISABLED" ;
VAL_ 1297 RCM_a019_eventDiagEnabled 1 "ENABLED" 0 "DISABLED" ;
VAL_ 1297 RCM_a019_eventDriveOrientation 1 "RIGHT_HAND_DRIVE" 0 "LEFT_HAND_DRIVE" ;
VAL_ 1297 RCM_a019_eventIDFsignal 1 "ACTIVE" 0 "NOT_ACTIVE" ;
VAL_ 1297 RCM_a019_eventFrontLeftSeatbelt 1 "LATCHED" 0 "UNLATCHED" ;
VAL_ 1297 RCM_a019_eventFrontRightSeatbelt 1 "LATCHED" 0 "UNLATCHED" ;
VAL_ 1297 RCM_a019_eventDriverBrakeApply 3 "Faulty_SNA" 2 "Driver_applying_brakes" 1 "Not_Applied" 0 "NotInit_orOff" ;
VAL_ 1297 RCM_a019_eventAccelPedalPos 255 "SNA" ;
VAL_ 1297 RCM_a020_eventArmStatus 1 "ARMED" 0 "UNARMED" ;
VAL_ 1297 RCM_a020_eventFactoryMode 1 "ENABLED" 0 "DISABLED" ;
VAL_ 1297 RCM_a020_eventDiagEnabled 1 "ENABLED" 0 "DISABLED" ;
VAL_ 1297 RCM_a020_eventDriveOrientation 1 "RIGHT_HAND_DRIVE" 0 "LEFT_HAND_DRIVE" ;
VAL_ 1297 RCM_a020_eventIDFsignal 1 "ACTIVE" 0 "NOT_ACTIVE" ;
VAL_ 1297 RCM_a020_eventFrontLeftSeatbelt 1 "LATCHED" 0 "UNLATCHED" ;
VAL_ 1297 RCM_a020_eventFrontRightSeatbelt 1 "LATCHED" 0 "UNLATCHED" ;
VAL_ 1297 RCM_a020_eventDriverBrakeApply 3 "Faulty_SNA" 2 "Driver_applying_brakes" 1 "Not_Applied" 0 "NotInit_orOff" ;
VAL_ 1297 RCM_a020_eventAccelPedalPos 255 "SNA" ;
VAL_ 1297 RCM_a021_eventArmStatus 1 "ARMED" 0 "UNARMED" ;
VAL_ 1297 RCM_a021_eventFactoryMode 1 "ENABLED" 0 "DISABLED" ;
VAL_ 1297 RCM_a021_eventDiagEnabled 1 "ENABLED" 0 "DISABLED" ;
VAL_ 1297 RCM_a021_eventDriveOrientation 1 "RIGHT_HAND_DRIVE" 0 "LEFT_HAND_DRIVE" ;
VAL_ 1297 RCM_a021_eventIDFsignal 1 "ACTIVE" 0 "NOT_ACTIVE" ;
VAL_ 1297 RCM_a021_eventFrontLeftSeatbelt 1 "LATCHED" 0 "UNLATCHED" ;
VAL_ 1297 RCM_a021_eventFrontRightSeatbelt 1 "LATCHED" 0 "UNLATCHED" ;
VAL_ 1297 RCM_a021_eventDriverBrakeApply 3 "Faulty_SNA" 2 "Driver_applying_brakes" 1 "Not_Applied" 0 "NotInit_orOff" ;
VAL_ 1297 RCM_a021_eventAccelPedalPos 255 "SNA" ;
VAL_ 1297 RCM_a022_eventArmStatus 1 "ARMED" 0 "UNARMED" ;
VAL_ 1297 RCM_a022_eventFactoryMode 1 "ENABLED" 0 "DISABLED" ;
VAL_ 1297 RCM_a022_eventDiagEnabled 1 "ENABLED" 0 "DISABLED" ;
VAL_ 1297 RCM_a022_eventDriveOrientation 1 "RIGHT_HAND_DRIVE" 0 "LEFT_HAND_DRIVE" ;
VAL_ 1297 RCM_a022_eventIDFsignal 1 "ACTIVE" 0 "NOT_ACTIVE" ;
VAL_ 1297 RCM_a022_eventFrontLeftSeatbelt 1 "LATCHED" 0 "UNLATCHED" ;
VAL_ 1297 RCM_a022_eventFrontRightSeatbelt 1 "LATCHED" 0 "UNLATCHED" ;
VAL_ 1297 RCM_a022_eventDriverBrakeApply 3 "Faulty_SNA" 2 "Driver_applying_brakes" 1 "Not_Applied" 0 "NotInit_orOff" ;
VAL_ 1297 RCM_a022_eventAccelPedalPos 255 "SNA" ;
VAL_ 1297 RCM_a023_eventArmStatus 1 "ARMED" 0 "UNARMED" ;
VAL_ 1297 RCM_a023_eventFactoryMode 1 "ENABLED" 0 "DISABLED" ;
VAL_ 1297 RCM_a023_eventDiagEnabled 1 "ENABLED" 0 "DISABLED" ;
VAL_ 1297 RCM_a023_eventDriveOrientation 1 "RIGHT_HAND_DRIVE" 0 "LEFT_HAND_DRIVE" ;
VAL_ 1297 RCM_a023_eventIDFsignal 1 "ACTIVE" 0 "NOT_ACTIVE" ;
VAL_ 1297 RCM_a023_eventFrontLeftSeatbelt 1 "LATCHED" 0 "UNLATCHED" ;
VAL_ 1297 RCM_a023_eventFrontRightSeatbelt 1 "LATCHED" 0 "UNLATCHED" ;
VAL_ 1297 RCM_a023_eventDriverBrakeApply 3 "Faulty_SNA" 2 "Driver_applying_brakes" 1 "Not_Applied" 0 "NotInit_orOff" ;
VAL_ 1297 RCM_a023_eventAccelPedalPos 255 "SNA" ;
VAL_ 1297 RCM_a024_eventArmStatus 1 "ARMED" 0 "UNARMED" ;
VAL_ 1297 RCM_a024_eventFactoryMode 1 "ENABLED" 0 "DISABLED" ;
VAL_ 1297 RCM_a024_eventDiagEnabled 1 "ENABLED" 0 "DISABLED" ;
VAL_ 1297 RCM_a024_eventDriveOrientation 1 "RIGHT_HAND_DRIVE" 0 "LEFT_HAND_DRIVE" ;
VAL_ 1297 RCM_a024_eventIDFsignal 1 "ACTIVE" 0 "NOT_ACTIVE" ;
VAL_ 1297 RCM_a024_eventFrontLeftSeatbelt 1 "LATCHED" 0 "UNLATCHED" ;
VAL_ 1297 RCM_a024_eventFrontRightSeatbelt 1 "LATCHED" 0 "UNLATCHED" ;
VAL_ 1297 RCM_a024_eventDriverBrakeApply 3 "Faulty_SNA" 2 "Driver_applying_brakes" 1 "Not_Applied" 0 "NotInit_orOff" ;
VAL_ 1297 RCM_a024_eventAccelPedalPos 255 "SNA" ;
VAL_ 1297 RCM_a025_eventArmStatus 1 "ARMED" 0 "UNARMED" ;
VAL_ 1297 RCM_a025_eventFactoryMode 1 "ENABLED" 0 "DISABLED" ;
VAL_ 1297 RCM_a025_eventDiagEnabled 1 "ENABLED" 0 "DISABLED" ;
VAL_ 1297 RCM_a025_eventDriveOrientation 1 "RIGHT_HAND_DRIVE" 0 "LEFT_HAND_DRIVE" ;
VAL_ 1297 RCM_a025_eventIDFsignal 1 "ACTIVE" 0 "NOT_ACTIVE" ;
VAL_ 1297 RCM_a025_eventFrontLeftSeatbelt 1 "LATCHED" 0 "UNLATCHED" ;
VAL_ 1297 RCM_a025_eventFrontRightSeatbelt 1 "LATCHED" 0 "UNLATCHED" ;
VAL_ 1297 RCM_a025_eventDriverBrakeApply 3 "Faulty_SNA" 2 "Driver_applying_brakes" 1 "Not_Applied" 0 "NotInit_orOff" ;
VAL_ 1297 RCM_a025_eventAccelPedalPos 255 "SNA" ;
VAL_ 1297 RCM_a026_eventArmStatus 1 "ARMED" 0 "UNARMED" ;
VAL_ 1297 RCM_a026_eventFactoryMode 1 "ENABLED" 0 "DISABLED" ;
VAL_ 1297 RCM_a026_eventDiagEnabled 1 "ENABLED" 0 "DISABLED" ;
VAL_ 1297 RCM_a026_eventDriveOrientation 1 "RIGHT_HAND_DRIVE" 0 "LEFT_HAND_DRIVE" ;
VAL_ 1297 RCM_a026_eventIDFsignal 1 "ACTIVE" 0 "NOT_ACTIVE" ;
VAL_ 1297 RCM_a026_eventFrontLeftSeatbelt 1 "LATCHED" 0 "UNLATCHED" ;
VAL_ 1297 RCM_a026_eventFrontRightSeatbelt 1 "LATCHED" 0 "UNLATCHED" ;
VAL_ 1297 RCM_a026_eventDriverBrakeApply 3 "Faulty_SNA" 2 "Driver_applying_brakes" 1 "Not_Applied" 0 "NotInit_orOff" ;
VAL_ 1297 RCM_a026_eventAccelPedalPos 255 "SNA" ;
VAL_ 1297 RCM_a027_eventArmStatus 1 "ARMED" 0 "UNARMED" ;
VAL_ 1297 RCM_a027_eventFactoryMode 1 "ENABLED" 0 "DISABLED" ;
VAL_ 1297 RCM_a027_eventDiagEnabled 1 "ENABLED" 0 "DISABLED" ;
VAL_ 1297 RCM_a027_eventDriveOrientation 1 "RIGHT_HAND_DRIVE" 0 "LEFT_HAND_DRIVE" ;
VAL_ 1297 RCM_a027_eventIDFsignal 1 "ACTIVE" 0 "NOT_ACTIVE" ;
VAL_ 1297 RCM_a027_eventFrontLeftSeatbelt 1 "LATCHED" 0 "UNLATCHED" ;
VAL_ 1297 RCM_a027_eventFrontRightSeatbelt 1 "LATCHED" 0 "UNLATCHED" ;
VAL_ 1297 RCM_a027_eventDriverBrakeApply 3 "Faulty_SNA" 2 "Driver_applying_brakes" 1 "Not_Applied" 0 "NotInit_orOff" ;
VAL_ 1297 RCM_a027_eventAccelPedalPos 255 "SNA" ;
VAL_ 1297 RCM_a028_eventArmStatus 1 "ARMED" 0 "UNARMED" ;
VAL_ 1297 RCM_a028_eventFactoryMode 1 "ENABLED" 0 "DISABLED" ;
VAL_ 1297 RCM_a028_eventDiagEnabled 1 "ENABLED" 0 "DISABLED" ;
VAL_ 1297 RCM_a028_eventDriveOrientation 1 "RIGHT_HAND_DRIVE" 0 "LEFT_HAND_DRIVE" ;
VAL_ 1297 RCM_a028_eventIDFsignal 1 "ACTIVE" 0 "NOT_ACTIVE" ;
VAL_ 1297 RCM_a028_eventFrontLeftSeatbelt 1 "LATCHED" 0 "UNLATCHED" ;
VAL_ 1297 RCM_a028_eventFrontRightSeatbelt 1 "LATCHED" 0 "UNLATCHED" ;
VAL_ 1297 RCM_a028_eventDriverBrakeApply 3 "Faulty_SNA" 2 "Driver_applying_brakes" 1 "Not_Applied" 0 "NotInit_orOff" ;
VAL_ 1297 RCM_a028_eventAccelPedalPos 255 "SNA" ;
VAL_ 1297 RCM_a029_eventArmStatus 1 "ARMED" 0 "UNARMED" ;
VAL_ 1297 RCM_a029_eventFactoryMode 1 "ENABLED" 0 "DISABLED" ;
VAL_ 1297 RCM_a029_eventDiagEnabled 1 "ENABLED" 0 "DISABLED" ;
VAL_ 1297 RCM_a029_eventDriveOrientation 1 "RIGHT_HAND_DRIVE" 0 "LEFT_HAND_DRIVE" ;
VAL_ 1297 RCM_a029_eventIDFsignal 1 "ACTIVE" 0 "NOT_ACTIVE" ;
VAL_ 1297 RCM_a029_eventFrontLeftSeatbelt 1 "LATCHED" 0 "UNLATCHED" ;
VAL_ 1297 RCM_a029_eventFrontRightSeatbelt 1 "LATCHED" 0 "UNLATCHED" ;
VAL_ 1297 RCM_a029_eventDriverBrakeApply 3 "Faulty_SNA" 2 "Driver_applying_brakes" 1 "Not_Applied" 0 "NotInit_orOff" ;
VAL_ 1297 RCM_a029_eventAccelPedalPos 255 "SNA" ;
VAL_ 1297 RCM_a030_eventArmStatus 1 "ARMED" 0 "UNARMED" ;
VAL_ 1297 RCM_a030_eventFactoryMode 1 "ENABLED" 0 "DISABLED" ;
VAL_ 1297 RCM_a030_eventDiagEnabled 1 "ENABLED" 0 "DISABLED" ;
VAL_ 1297 RCM_a030_eventDriveOrientation 1 "RIGHT_HAND_DRIVE" 0 "LEFT_HAND_DRIVE" ;
VAL_ 1297 RCM_a030_eventIDFsignal 1 "ACTIVE" 0 "NOT_ACTIVE" ;
VAL_ 1297 RCM_a030_eventFrontLeftSeatbelt 1 "LATCHED" 0 "UNLATCHED" ;
VAL_ 1297 RCM_a030_eventFrontRightSeatbelt 1 "LATCHED" 0 "UNLATCHED" ;
VAL_ 1297 RCM_a030_eventDriverBrakeApply 3 "Faulty_SNA" 2 "Driver_applying_brakes" 1 "Not_Applied" 0 "NotInit_orOff" ;
VAL_ 1297 RCM_a030_eventAccelPedalPos 255 "SNA" ;
VAL_ 1297 RCM_a031_eventArmStatus 1 "ARMED" 0 "UNARMED" ;
VAL_ 1297 RCM_a031_eventFactoryMode 1 "ENABLED" 0 "DISABLED" ;
VAL_ 1297 RCM_a031_eventDiagEnabled 1 "ENABLED" 0 "DISABLED" ;
VAL_ 1297 RCM_a031_eventDriveOrientation 1 "RIGHT_HAND_DRIVE" 0 "LEFT_HAND_DRIVE" ;
VAL_ 1297 RCM_a031_eventIDFsignal 1 "ACTIVE" 0 "NOT_ACTIVE" ;
VAL_ 1297 RCM_a031_eventFrontLeftSeatbelt 1 "LATCHED" 0 "UNLATCHED" ;
VAL_ 1297 RCM_a031_eventFrontRightSeatbelt 1 "LATCHED" 0 "UNLATCHED" ;
VAL_ 1297 RCM_a031_eventDriverBrakeApply 3 "Faulty_SNA" 2 "Driver_applying_brakes" 1 "Not_Applied" 0 "NotInit_orOff" ;
VAL_ 1297 RCM_a031_eventAccelPedalPos 255 "SNA" ;
VAL_ 1297 RCM_a032_eventArmStatus 1 "ARMED" 0 "UNARMED" ;
VAL_ 1297 RCM_a032_eventFactoryMode 1 "ENABLED" 0 "DISABLED" ;
VAL_ 1297 RCM_a032_eventDiagEnabled 1 "ENABLED" 0 "DISABLED" ;
VAL_ 1297 RCM_a032_eventDriveOrientation 1 "RIGHT_HAND_DRIVE" 0 "LEFT_HAND_DRIVE" ;
VAL_ 1297 RCM_a032_eventIDFsignal 1 "ACTIVE" 0 "NOT_ACTIVE" ;
VAL_ 1297 RCM_a032_eventFrontLeftSeatbelt 1 "LATCHED" 0 "UNLATCHED" ;
VAL_ 1297 RCM_a032_eventFrontRightSeatbelt 1 "LATCHED" 0 "UNLATCHED" ;
VAL_ 1297 RCM_a032_eventDriverBrakeApply 3 "Faulty_SNA" 2 "Driver_applying_brakes" 1 "Not_Applied" 0 "NotInit_orOff" ;
VAL_ 1297 RCM_a032_eventAccelPedalPos 255 "SNA" ;
VAL_ 1297 RCM_a033_eventArmStatus 1 "ARMED" 0 "UNARMED" ;
VAL_ 1297 RCM_a033_eventFactoryMode 1 "ENABLED" 0 "DISABLED" ;
VAL_ 1297 RCM_a033_eventDiagEnabled 1 "ENABLED" 0 "DISABLED" ;
VAL_ 1297 RCM_a033_eventDriveOrientation 1 "RIGHT_HAND_DRIVE" 0 "LEFT_HAND_DRIVE" ;
VAL_ 1297 RCM_a033_eventIDFsignal 1 "ACTIVE" 0 "NOT_ACTIVE" ;
VAL_ 1297 RCM_a033_eventFrontLeftSeatbelt 1 "LATCHED" 0 "UNLATCHED" ;
VAL_ 1297 RCM_a033_eventFrontRightSeatbelt 1 "LATCHED" 0 "UNLATCHED" ;
VAL_ 1297 RCM_a033_eventDriverBrakeApply 3 "Faulty_SNA" 2 "Driver_applying_brakes" 1 "Not_Applied" 0 "NotInit_orOff" ;
VAL_ 1297 RCM_a033_eventAccelPedalPos 255 "SNA" ;
VAL_ 1297 RCM_a034_eventArmStatus 1 "ARMED" 0 "UNARMED" ;
VAL_ 1297 RCM_a034_eventFactoryMode 1 "ENABLED" 0 "DISABLED" ;
VAL_ 1297 RCM_a034_eventDiagEnabled 1 "ENABLED" 0 "DISABLED" ;
VAL_ 1297 RCM_a034_eventDriveOrientation 1 "RIGHT_HAND_DRIVE" 0 "LEFT_HAND_DRIVE" ;
VAL_ 1297 RCM_a034_eventIDFsignal 1 "ACTIVE" 0 "NOT_ACTIVE" ;
VAL_ 1297 RCM_a034_eventFrontLeftSeatbelt 1 "LATCHED" 0 "UNLATCHED" ;
VAL_ 1297 RCM_a034_eventFrontRightSeatbelt 1 "LATCHED" 0 "UNLATCHED" ;
VAL_ 1297 RCM_a034_eventDriverBrakeApply 3 "Faulty_SNA" 2 "Driver_applying_brakes" 1 "Not_Applied" 0 "NotInit_orOff" ;
VAL_ 1297 RCM_a034_eventAccelPedalPos 255 "SNA" ;
VAL_ 1297 RCM_a035_eventArmStatus 1 "ARMED" 0 "UNARMED" ;
VAL_ 1297 RCM_a035_eventFactoryMode 1 "ENABLED" 0 "DISABLED" ;
VAL_ 1297 RCM_a035_eventDiagEnabled 1 "ENABLED" 0 "DISABLED" ;
VAL_ 1297 RCM_a035_eventDriveOrientation 1 "RIGHT_HAND_DRIVE" 0 "LEFT_HAND_DRIVE" ;
VAL_ 1297 RCM_a035_eventIDFsignal 1 "ACTIVE" 0 "NOT_ACTIVE" ;
VAL_ 1297 RCM_a035_eventFrontLeftSeatbelt 1 "LATCHED" 0 "UNLATCHED" ;
VAL_ 1297 RCM_a035_eventFrontRightSeatbelt 1 "LATCHED" 0 "UNLATCHED" ;
VAL_ 1297 RCM_a035_eventDriverBrakeApply 3 "Faulty_SNA" 2 "Driver_applying_brakes" 1 "Not_Applied" 0 "NotInit_orOff" ;
VAL_ 1297 RCM_a035_eventAccelPedalPos 255 "SNA" ;
VAL_ 1297 RCM_a036_eventArmStatus 1 "ARMED" 0 "UNARMED" ;
VAL_ 1297 RCM_a036_eventFactoryMode 1 "ENABLED" 0 "DISABLED" ;
VAL_ 1297 RCM_a036_eventDiagEnabled 1 "ENABLED" 0 "DISABLED" ;
VAL_ 1297 RCM_a036_eventDriveOrientation 1 "RIGHT_HAND_DRIVE" 0 "LEFT_HAND_DRIVE" ;
VAL_ 1297 RCM_a036_eventIDFsignal 1 "ACTIVE" 0 "NOT_ACTIVE" ;
VAL_ 1297 RCM_a036_eventFrontLeftSeatbelt 1 "LATCHED" 0 "UNLATCHED" ;
VAL_ 1297 RCM_a036_eventFrontRightSeatbelt 1 "LATCHED" 0 "UNLATCHED" ;
VAL_ 1297 RCM_a036_eventDriverBrakeApply 3 "Faulty_SNA" 2 "Driver_applying_brakes" 1 "Not_Applied" 0 "NotInit_orOff" ;
VAL_ 1297 RCM_a036_eventAccelPedalPos 255 "SNA" ;
VAL_ 1297 RCM_a037_eventArmStatus 1 "ARMED" 0 "UNARMED" ;
VAL_ 1297 RCM_a037_eventFactoryMode 1 "ENABLED" 0 "DISABLED" ;
VAL_ 1297 RCM_a037_eventDiagEnabled 1 "ENABLED" 0 "DISABLED" ;
VAL_ 1297 RCM_a037_eventDriveOrientation 1 "RIGHT_HAND_DRIVE" 0 "LEFT_HAND_DRIVE" ;
VAL_ 1297 RCM_a037_eventIDFsignal 1 "ACTIVE" 0 "NOT_ACTIVE" ;
VAL_ 1297 RCM_a037_eventFrontLeftSeatbelt 1 "LATCHED" 0 "UNLATCHED" ;
VAL_ 1297 RCM_a037_eventFrontRightSeatbelt 1 "LATCHED" 0 "UNLATCHED" ;
VAL_ 1297 RCM_a037_eventDriverBrakeApply 3 "Faulty_SNA" 2 "Driver_applying_brakes" 1 "Not_Applied" 0 "NotInit_orOff" ;
VAL_ 1297 RCM_a037_eventAccelPedalPos 255 "SNA" ;
VAL_ 1297 RCM_a040_eventArmStatus 1 "ARMED" 0 "UNARMED" ;
VAL_ 1297 RCM_a040_eventFactoryMode 1 "ENABLED" 0 "DISABLED" ;
VAL_ 1297 RCM_a040_eventDiagEnabled 1 "ENABLED" 0 "DISABLED" ;
VAL_ 1297 RCM_a040_eventDriveOrientation 1 "RIGHT_HAND_DRIVE" 0 "LEFT_HAND_DRIVE" ;
VAL_ 1297 RCM_a040_eventIDFsignal 1 "ACTIVE" 0 "NOT_ACTIVE" ;
VAL_ 1297 RCM_a040_eventFrontLeftSeatbelt 1 "LATCHED" 0 "UNLATCHED" ;
VAL_ 1297 RCM_a040_eventFrontRightSeatbelt 1 "LATCHED" 0 "UNLATCHED" ;
VAL_ 1297 RCM_a040_eventDriverBrakeApply 3 "Faulty_SNA" 2 "Driver_applying_brakes" 1 "Not_Applied" 0 "NotInit_orOff" ;
VAL_ 1297 RCM_a040_eventAccelPedalPos 255 "SNA" ;
VAL_ 1297 RCM_a041_eventArmStatus 1 "ARMED" 0 "UNARMED" ;
VAL_ 1297 RCM_a041_eventFactoryMode 1 "ENABLED" 0 "DISABLED" ;
VAL_ 1297 RCM_a041_eventDiagEnabled 1 "ENABLED" 0 "DISABLED" ;
VAL_ 1297 RCM_a041_eventDriveOrientation 1 "RIGHT_HAND_DRIVE" 0 "LEFT_HAND_DRIVE" ;
VAL_ 1297 RCM_a041_eventIDFsignal 1 "ACTIVE" 0 "NOT_ACTIVE" ;
VAL_ 1297 RCM_a041_eventFrontLeftSeatbelt 1 "LATCHED" 0 "UNLATCHED" ;
VAL_ 1297 RCM_a041_eventFrontRightSeatbelt 1 "LATCHED" 0 "UNLATCHED" ;
VAL_ 1297 RCM_a041_eventDriverBrakeApply 3 "Faulty_SNA" 2 "Driver_applying_brakes" 1 "Not_Applied" 0 "NotInit_orOff" ;
VAL_ 1297 RCM_a041_eventAccelPedalPos 255 "SNA" ;
VAL_ 1297 RCM_a042_eventArmStatus 1 "ARMED" 0 "UNARMED" ;
VAL_ 1297 RCM_a042_eventFactoryMode 1 "ENABLED" 0 "DISABLED" ;
VAL_ 1297 RCM_a042_eventDiagEnabled 1 "ENABLED" 0 "DISABLED" ;
VAL_ 1297 RCM_a042_eventDriveOrientation 1 "RIGHT_HAND_DRIVE" 0 "LEFT_HAND_DRIVE" ;
VAL_ 1297 RCM_a042_eventIDFsignal 1 "ACTIVE" 0 "NOT_ACTIVE" ;
VAL_ 1297 RCM_a042_eventFrontLeftSeatbelt 1 "LATCHED" 0 "UNLATCHED" ;
VAL_ 1297 RCM_a042_eventFrontRightSeatbelt 1 "LATCHED" 0 "UNLATCHED" ;
VAL_ 1297 RCM_a042_eventDriverBrakeApply 3 "Faulty_SNA" 2 "Driver_applying_brakes" 1 "Not_Applied" 0 "NotInit_orOff" ;
VAL_ 1297 RCM_a042_eventAccelPedalPos 255 "SNA" ;
VAL_ 1297 RCM_a043_eventArmStatus 1 "ARMED" 0 "UNARMED" ;
VAL_ 1297 RCM_a043_eventFactoryMode 1 "ENABLED" 0 "DISABLED" ;
VAL_ 1297 RCM_a043_eventDiagEnabled 1 "ENABLED" 0 "DISABLED" ;
VAL_ 1297 RCM_a043_eventDriveOrientation 1 "RIGHT_HAND_DRIVE" 0 "LEFT_HAND_DRIVE" ;
VAL_ 1297 RCM_a043_eventIDFsignal 1 "ACTIVE" 0 "NOT_ACTIVE" ;
VAL_ 1297 RCM_a043_eventFrontLeftSeatbelt 1 "LATCHED" 0 "UNLATCHED" ;
VAL_ 1297 RCM_a043_eventFrontRightSeatbelt 1 "LATCHED" 0 "UNLATCHED" ;
VAL_ 1297 RCM_a043_eventDriverBrakeApply 3 "Faulty_SNA" 2 "Driver_applying_brakes" 1 "Not_Applied" 0 "NotInit_orOff" ;
VAL_ 1297 RCM_a043_eventAccelPedalPos 255 "SNA" ;
VAL_ 1297 RCM_a044_eventArmStatus 1 "ARMED" 0 "UNARMED" ;
VAL_ 1297 RCM_a044_eventFactoryMode 1 "ENABLED" 0 "DISABLED" ;
VAL_ 1297 RCM_a044_eventDiagEnabled 1 "ENABLED" 0 "DISABLED" ;
VAL_ 1297 RCM_a044_eventDriveOrientation 1 "RIGHT_HAND_DRIVE" 0 "LEFT_HAND_DRIVE" ;
VAL_ 1297 RCM_a044_eventIDFsignal 1 "ACTIVE" 0 "NOT_ACTIVE" ;
VAL_ 1297 RCM_a044_eventFrontLeftSeatbelt 1 "LATCHED" 0 "UNLATCHED" ;
VAL_ 1297 RCM_a044_eventFrontRightSeatbelt 1 "LATCHED" 0 "UNLATCHED" ;
VAL_ 1297 RCM_a044_eventDriverBrakeApply 3 "Faulty_SNA" 2 "Driver_applying_brakes" 1 "Not_Applied" 0 "NotInit_orOff" ;
VAL_ 1297 RCM_a044_eventAccelPedalPos 255 "SNA" ;
VAL_ 1297 RCM_a045_eventArmStatus 1 "ARMED" 0 "UNARMED" ;
VAL_ 1297 RCM_a045_eventFactoryMode 1 "ENABLED" 0 "DISABLED" ;
VAL_ 1297 RCM_a045_eventDiagEnabled 1 "ENABLED" 0 "DISABLED" ;
VAL_ 1297 RCM_a045_eventDriveOrientation 1 "RIGHT_HAND_DRIVE" 0 "LEFT_HAND_DRIVE" ;
VAL_ 1297 RCM_a045_eventIDFsignal 1 "ACTIVE" 0 "NOT_ACTIVE" ;
VAL_ 1297 RCM_a045_eventFrontLeftSeatbelt 1 "LATCHED" 0 "UNLATCHED" ;
